VERSION ""

NS_ :

BS_:

BU_:

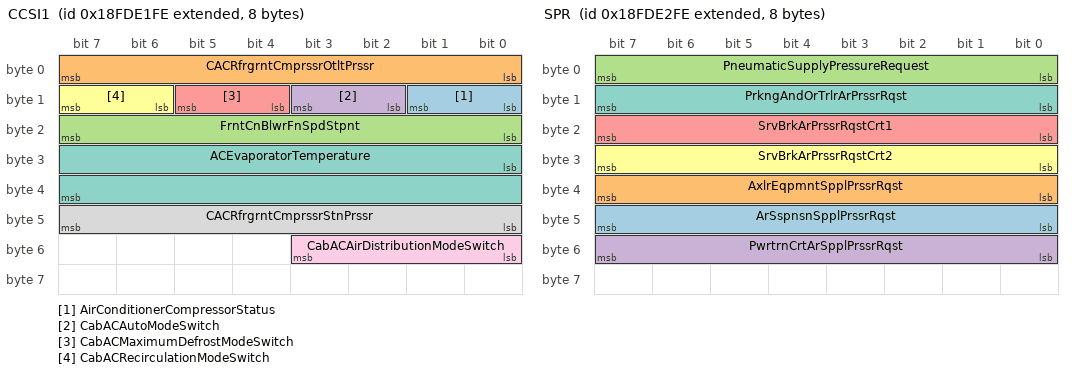
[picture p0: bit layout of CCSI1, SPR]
BO_ 2566775294 CCSI1: 8 Vector__XXX
 SG_ AirConditionerCompressorStatus : 8|2@1+ (1,0) [0|3] "" Vector__XXX
 SG_ CACRfrgrntCmprssrOtltPrssr : 0|8@1+ (16,0) [0|4000] "kPa" Vector__XXX
 SG_ FrntCnBlwrFnSpdStpnt : 16|8@1+ (0.4,0) [0|100] "%" Vector__XXX
 SG_ CabACAutoModeSwitch : 10|2@1+ (1,0) [0|3] "" Vector__XXX
 SG_ CabACMaximumDefrostModeSwitch : 12|2@1+ (1,0) [0|3] "" Vector__XXX
 SG_ CabACRecirculationModeSwitch : 14|2@1+ (1,0) [0|3] "" Vector__XXX
 SG_ ACEvaporatorTemperature : 24|16@1+ (0.03125,-273) [-273|1734.96875] "degC" Vector__XXX
 SG_ CACRfrgrntCmprssrStnPrssr : 40|8@1+ (16,0) [0|4000] "kPa" Vector__XXX
 SG_ CabACAirDistributionModeSwitch : 48|4@1+ (1,0) [0|15] "" Vector__XXX

BO_ 2566775550 SPR: 8 Vector__XXX
 SG_ ArSspnsnSpplPrssrRqst : 40|8@1+ (8,0) [0|2000] "kPa" Vector__XXX
 SG_ AxlrEqpmntSpplPrssrRqst : 32|8@1+ (8,0) [0|2000] "kPa" Vector__XXX
 SG_ PneumaticSupplyPressureRequest : 0|8@1+ (8,0) [0|2000] "kPa" Vector__XXX
 SG_ PwrtrnCrtArSpplPrssrRqst : 48|8@1+ (8,0) [0|2000] "kPa" Vector__XXX
 SG_ SrvBrkArPrssrRqstCrt1 : 16|8@1+ (8,0) [0|2000] "kPa" Vector__XXX
 SG_ SrvBrkArPrssrRqstCrt2 : 24|8@1+ (8,0) [0|2000] "kPa" Vector__XXX
 SG_ PrkngAndOrTrlrArPrssrRqst : 8|8@1+ (8,0) [0|2000] "kPa" Vector__XXX

BO_ 2566775806 EOAC: 8 Vector__XXX
 SG_ TravelVelocityControlPosition : 0|8@1+ (1,-125) [-125|125] "%" Vector__XXX

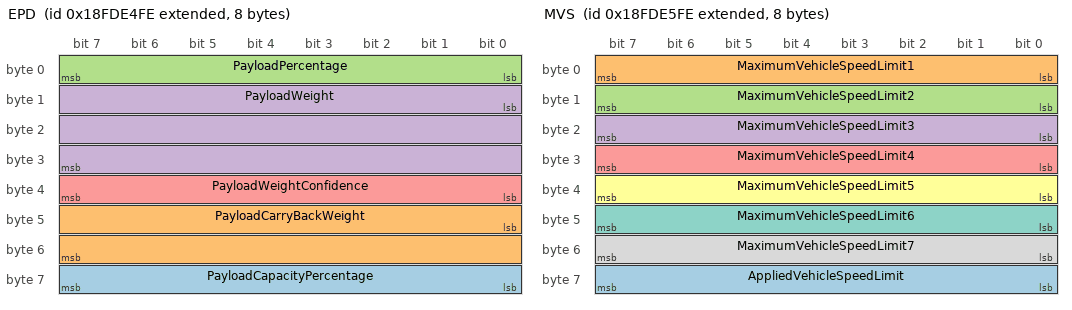
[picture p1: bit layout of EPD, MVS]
BO_ 2566776062 EPD: 8 Vector__XXX
 SG_ PayloadCapacityPercentage : 56|8@1+ (1,0) [0|250] "%" Vector__XXX
 SG_ PayloadCarryBackWeight : 40|16@1+ (2,0) [0|128510] "kg" Vector__XXX
 SG_ PayloadPercentage : 0|8@1+ (1,0) [0|250] "%" Vector__XXX
 SG_ PayloadWeight : 8|24@1+ (2,0) [0|32899070] "kg" Vector__XXX
 SG_ PayloadWeightConfidence : 32|8@1+ (0.5,0) [0|100] "%" Vector__XXX

BO_ 2566776318 MVS: 8 Vector__XXX
 SG_ AppliedVehicleSpeedLimit : 56|8@1+ (1,0) [0|250] "km/h" Vector__XXX
 SG_ MaximumVehicleSpeedLimit1 : 0|8@1+ (1,0) [0|250] "km/h" Vector__XXX
 SG_ MaximumVehicleSpeedLimit2 : 8|8@1+ (1,0) [0|250] "km/h" Vector__XXX
 SG_ MaximumVehicleSpeedLimit3 : 16|8@1+ (1,0) [0|250] "km/h" Vector__XXX
 SG_ MaximumVehicleSpeedLimit4 : 24|8@1+ (1,0) [0|250] "km/h" Vector__XXX
 SG_ MaximumVehicleSpeedLimit5 : 32|8@1+ (1,0) [0|250] "km/h" Vector__XXX
 SG_ MaximumVehicleSpeedLimit6 : 40|8@1+ (1,0) [0|250] "km/h" Vector__XXX
 SG_ MaximumVehicleSpeedLimit7 : 48|8@1+ (1,0) [0|250] "km/h" Vector__XXX

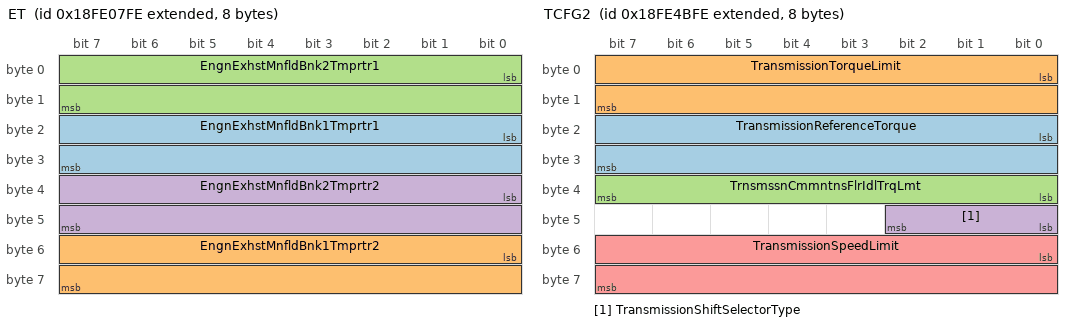
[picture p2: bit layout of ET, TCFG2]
BO_ 2566785022 ET: 8 Vector__XXX
 SG_ EngnExhstMnfldBnk1Tmprtr1 : 16|16@1+ (0.03125,-273) [-273|1734.96875] "degC" Vector__XXX
 SG_ EngnExhstMnfldBnk1Tmprtr2 : 48|16@1+ (0.03125,-273) [-273|1734.96875] "degC" Vector__XXX
 SG_ EngnExhstMnfldBnk2Tmprtr1 : 0|16@1+ (0.03125,-273) [-273|1734.96875] "degC" Vector__XXX
 SG_ EngnExhstMnfldBnk2Tmprtr2 : 32|16@1+ (0.03125,-273) [-273|1734.96875] "degC" Vector__XXX

BO_ 2566799614 LD: 8 Vector__XXX
 SG_ AlternateBeamHeadLightData : 2|2@1+ (1,0) [0|3] "" Vector__XXX
 SG_ BackUpLightAndAlarmHorn : 16|2@1+ (1,0) [0|3] "" Vector__XXX
 SG_ CenterStopLight : 18|2@1+ (1,0) [0|3] "" Vector__XXX
 SG_ HighBeamHeadLightData : 6|2@1+ (1,0) [0|3] "" Vector__XXX
 SG_ ImplementClearanceLight : 24|2@1+ (1,0) [0|3] "" Vector__XXX
 SG_ ImplementLeftFacingWorkLight : 60|2@1+ (1,0) [0|3] "" Vector__XXX
 SG_ ImplementLeftForwardWorkLight : 54|2@1+ (1,0) [0|3] "" Vector__XXX
 SG_ ImplementMarkerLight : 28|2@1+ (1,0) [0|3] "" Vector__XXX
 SG_ ImplementOemOption1Light : 50|2@1+ (1,0) [0|3] "" Vector__XXX
 SG_ ImplementOemOption2Light : 48|2@1+ (1,0) [0|3] "" Vector__XXX
 SG_ ImplementRearWorkLight : 62|2@1+ (1,0) [0|3] "" Vector__XXX
 SG_ ImplementRightFacingWorkLight : 52|2@1+ (1,0) [0|3] "" Vector__XXX
 SG_ ImplementRightForwardWorkLight : 58|2@1+ (1,0) [0|3] "" Vector__XXX
 SG_ LeftStopLight : 22|2@1+ (1,0) [0|3] "" Vector__XXX
 SG_ LeftTurnSignalLights : 14|2@1+ (1,0) [0|3] "" Vector__XXX
 SG_ LowBeamHeadLightData : 4|2@1+ (1,0) [0|3] "" Vector__XXX
 SG_ RearFogLights : 32|2@1+ (1,0) [0|3] "" Vector__XXX
 SG_ RightStopLight : 20|2@1+ (1,0) [0|3] "" Vector__XXX
 SG_ RightTurnSignalLights : 12|2@1+ (1,0) [0|3] "" Vector__XXX
 SG_ RotatingBeaconLight : 10|2@1+ (1,0) [0|3] "" Vector__XXX
 SG_ RunningLight : 0|2@1+ (1,0) [0|3] "" Vector__XXX
 SG_ TractorClearanceLight : 26|2@1+ (1,0) [0|3] "" Vector__XXX
 SG_ TractorFrontFogLights : 8|2@1+ (1,0) [0|3] "" Vector__XXX
 SG_ TractorMarkerLight : 30|2@1+ (1,0) [0|3] "" Vector__XXX
 SG_ TractorRearLowMountedWorkLights : 36|2@1+ (1,0) [0|3] "" Vector__XXX
 SG_ TractorSideLowMountedWorkLights : 40|2@1+ (1,0) [0|3] "" Vector__XXX
 SG_ TrtrFrntHghMntdWrkLghts : 46|2@1+ (1,0) [0|3] "" Vector__XXX
 SG_ TrtrFrntLwMntdWrkLghts : 44|2@1+ (1,0) [0|3] "" Vector__XXX
 SG_ TrtrRrHghMntdWrkLghts : 38|2@1+ (1,0) [0|3] "" Vector__XXX
 SG_ TrtrSdHghMntdWrkLghts : 42|2@1+ (1,0) [0|3] "" Vector__XXX
 SG_ TrtrUndrsdMntdWrkLghts : 34|2@1+ (1,0) [0|3] "" Vector__XXX

BO_ 2566802174 ETC7: 8 Vector__XXX
 SG_ ActiveShiftConsoleIndicator : 10|2@1+ (1,0) [0|3] "" Vector__XXX
 SG_ TransmissionEngineCrankEnable : 12|2@1+ (1,0) [0|3] "" Vector__XXX
 SG_ TransmissionManualModeIndicator : 54|2@1+ (1,0) [0|3] "" Vector__XXX
 SG_ TransmissionMode10Indicator : 46|2@1+ (1,0) [0|3] "" Vector__XXX
 SG_ TransmissionMode1Indicator : 22|2@1+ (1,0) [0|3] "" Vector__XXX
 SG_ TransmissionMode2Indicator : 20|2@1+ (1,0) [0|3] "" Vector__XXX
 SG_ TransmissionMode3Indicator : 18|2@1+ (1,0) [0|3] "" Vector__XXX
 SG_ TransmissionMode4Indicator : 16|2@1+ (1,0) [0|3] "" Vector__XXX
 SG_ TransmissionMode5Indicator : 32|2@1+ (1,0) [0|3] "" Vector__XXX
 SG_ TransmissionMode6Indicator : 34|2@1+ (1,0) [0|3] "" Vector__XXX
 SG_ TransmissionMode7Indicator : 36|2@1+ (1,0) [0|3] "" Vector__XXX
 SG_ TransmissionMode8Indicator : 38|2@1+ (1,0) [0|3] "" Vector__XXX
 SG_ TransmissionMode9Indicator : 44|2@1+ (1,0) [0|3] "" Vector__XXX
 SG_ TransmissionServiceIndicator : 2|2@1+ (1,0) [0|3] "" Vector__XXX
 SG_ TransmissionWarningIndicator : 42|2@1+ (1,0) [0|3] "" Vector__XXX
 SG_ TrnsmssnArSpplPrssrIndtr : 48|3@1+ (1,0) [0|7] "" Vector__XXX
 SG_ TrnsmssnAtNtrlMnlRtrnStt : 51|3@1+ (1,0) [0|7] "" Vector__XXX
 SG_ TrnsmssnCrrntRngDsplBlnkStt : 0|2@1+ (1,0) [0|3] "" Vector__XXX
 SG_ TrnsmssnRdFrBrkRls : 8|2@1+ (1,0) [0|3] "" Vector__XXX
 SG_ TrnsmssnRqstdGrFdk : 24|8@1+ (1,-125) [-125|125] "gear value" Vector__XXX
 SG_ TrnsmssnRqstdRngDsplBlnkStt : 4|2@1+ (1,0) [0|3] "" Vector__XXX
 SG_ TrnsmssnRqstdRngDsplFlshStt : 6|2@1+ (1,0) [0|3] "" Vector__XXX
 SG_ TrnsmssnRvrsGrShftInhtStts : 40|2@1+ (1,0) [0|3] "" Vector__XXX
 SG_ TrnsmssnShftInhtIndtr : 14|2@1+ (1,0) [0|3] "" Vector__XXX
 SG_ TrnsmssnLdRdtnIndtr : 56|2@1+ (1,0) [0|3] "" Vector__XXX
 SG_ TrnsmssnPrDfndRngLmtIndtr : 58|2@1+ (1,0) [0|3] "" Vector__XXX
 SG_ TransmissionCoastModeIndicator : 60|2@1+ (1,0) [0|3] "" Vector__XXX
 SG_ TrnsmssnOtptShftBrkIndtr : 62|2@1+ (1,0) [0|3] "" Vector__XXX

BO_ 2566802430 TCFG2: 8 Vector__XXX
 SG_ TransmissionReferenceTorque : 16|16@1+ (1,0) [0|64255] "Nm" Vector__XXX
 SG_ TransmissionTorqueLimit : 0|16@1+ (1,0) [0|64255] "Nm" Vector__XXX
 SG_ TrnsmssnCmmntnsFlrIdlTrqLmt : 32|8@1+ (1,-125) [0|125] "%" Vector__XXX
 SG_ TransmissionShiftSelectorType : 40|3@1+ (1,0) [0|7] "" Vector__XXX
 SG_ TransmissionSpeedLimit : 48|16@1+ (0.125,0) [0|8031.875] "rpm" Vector__XXX

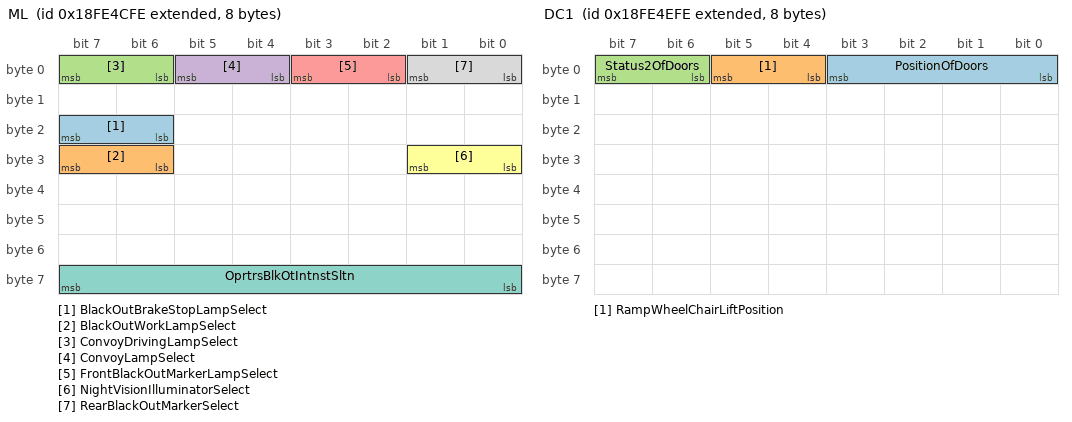
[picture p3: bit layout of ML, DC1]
BO_ 2566802686 ML: 8 Vector__XXX
 SG_ BlackOutBrakeStopLampSelect : 22|2@1+ (1,0) [0|3] "" Vector__XXX
 SG_ BlackOutWorkLampSelect : 30|2@1+ (1,0) [0|3] "" Vector__XXX
 SG_ ConvoyDrivingLampSelect : 6|2@1+ (1,0) [0|3] "" Vector__XXX
 SG_ ConvoyLampSelect : 4|2@1+ (1,0) [0|3] "" Vector__XXX
 SG_ FrontBlackOutMarkerLampSelect : 2|2@1+ (1,0) [0|3] "" Vector__XXX
 SG_ NightVisionIlluminatorSelect : 24|2@1+ (1,0) [0|3] "" Vector__XXX
 SG_ OprtrsBlkOtIntnstSltn : 56|8@1+ (0.4,0) [0|100] "%" Vector__XXX
 SG_ RearBlackOutMarkerSelect : 0|2@1+ (1,0) [0|3] "" Vector__XXX

BO_ 2566803198 DC1: 8 Vector__XXX
 SG_ PositionOfDoors : 0|4@1+ (1,0) [0|15] "" Vector__XXX
 SG_ RampWheelChairLiftPosition : 4|2@1+ (1,0) [0|3] "" Vector__XXX
 SG_ Status2OfDoors : 6|2@1+ (1,0) [0|3] "" Vector__XXX

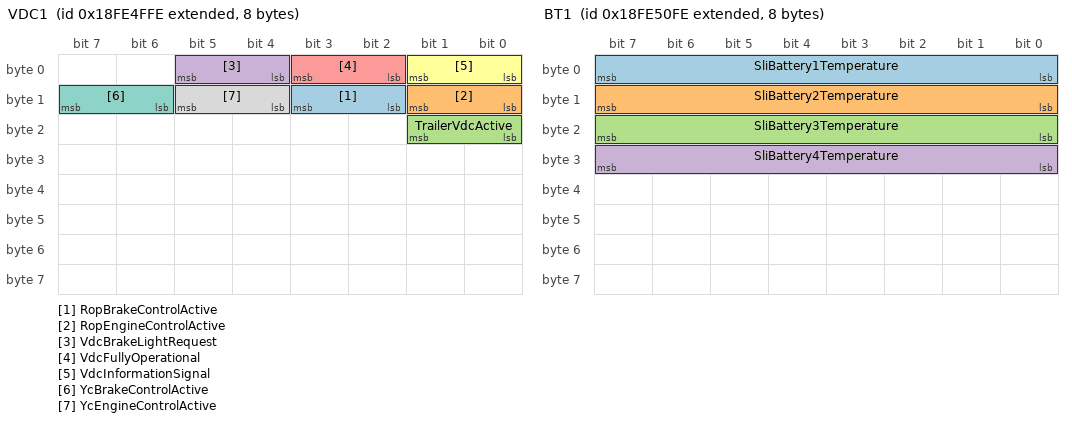
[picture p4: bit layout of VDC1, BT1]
BO_ 2566803454 VDC1: 8 Vector__XXX
 SG_ RopBrakeControlActive : 10|2@1+ (1,0) [0|3] "" Vector__XXX
 SG_ RopEngineControlActive : 8|2@1+ (1,0) [0|3] "" Vector__XXX
 SG_ TrailerVdcActive : 16|2@1+ (1,0) [0|3] "" Vector__XXX
 SG_ VdcBrakeLightRequest : 4|2@1+ (1,0) [0|3] "" Vector__XXX
 SG_ VdcFullyOperational : 2|2@1+ (1,0) [0|3] "" Vector__XXX
 SG_ VdcInformationSignal : 0|2@1+ (1,0) [0|3] "" Vector__XXX
 SG_ YcBrakeControlActive : 14|2@1+ (1,0) [0|3] "" Vector__XXX
 SG_ YcEngineControlActive : 12|2@1+ (1,0) [0|3] "" Vector__XXX

BO_ 2566803710 BT1: 8 Vector__XXX
 SG_ SliBattery1Temperature : 0|8@1+ (1,-40) [-40|210] "degC" Vector__XXX
 SG_ SliBattery2Temperature : 8|8@1+ (1,-40) [-40|210] "degC" Vector__XXX
 SG_ SliBattery3Temperature : 16|8@1+ (1,-40) [-40|210] "degC" Vector__XXX
 SG_ SliBattery4Temperature : 24|8@1+ (1,-40) [-40|210] "degC" Vector__XXX

BO_ 2566803966 ACC2: 8 Vector__XXX
 SG_ AccUsageDemand : 0|2@1+ (1,0) [0|3] "" Vector__XXX
 SG_ RequestedAccDistanceMode : 5|3@1+ (1,0) [0|7] "" Vector__XXX

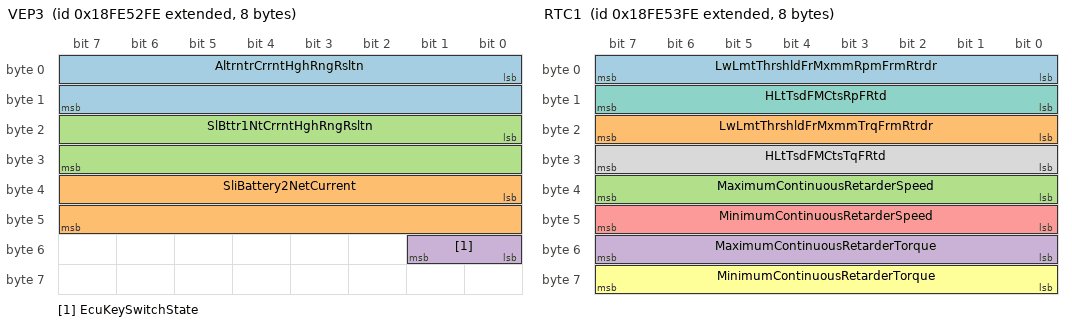
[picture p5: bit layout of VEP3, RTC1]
BO_ 2566804222 VEP3: 8 Vector__XXX
 SG_ AltrntrCrrntHghRngRsltn : 0|16@1+ (0.05,-1600) [-1600|1612.75] "A" Vector__XXX
 SG_ SliBattery2NetCurrent : 32|16@1+ (0.05,-1600) [-1600|1612.75] "A" Vector__XXX
 SG_ SlBttr1NtCrrntHghRngRsltn : 16|16@1+ (0.05,-1600) [-1600|1612.75] "A" Vector__XXX
 SG_ EcuKeySwitchState : 48|2@1+ (1,0) [0|3] "" Vector__XXX

BO_ 2566804478 RTC1: 8 Vector__XXX
 SG_ LwLmtThrshldFrMxmmRpmFrmRtrdr : 0|8@1+ (32,0) [0|8000] "rpm" Vector__XXX
 SG_ LwLmtThrshldFrMxmmTrqFrmRtrdr : 16|8@1+ (1,-125) [-125|125] "%" Vector__XXX
 SG_ MaximumContinuousRetarderSpeed : 32|8@1+ (32,0) [0|8000] "rpm" Vector__XXX
 SG_ MaximumContinuousRetarderTorque : 48|8@1+ (1,-125) [-125|125] "%" Vector__XXX
 SG_ MinimumContinuousRetarderSpeed : 40|8@1+ (32,0) [0|8000] "rpm" Vector__XXX
 SG_ MinimumContinuousRetarderTorque : 56|8@1+ (1,-125) [-125|125] "%" Vector__XXX
 SG_ HLtTsdFMCtsRpFRtd : 8|8@1+ (32,0) [0|8000] "rpm" Vector__XXX
 SG_ HLtTsdFMCtsTqFRtd : 24|8@1+ (1,-125) [-125|125] "%" Vector__XXX

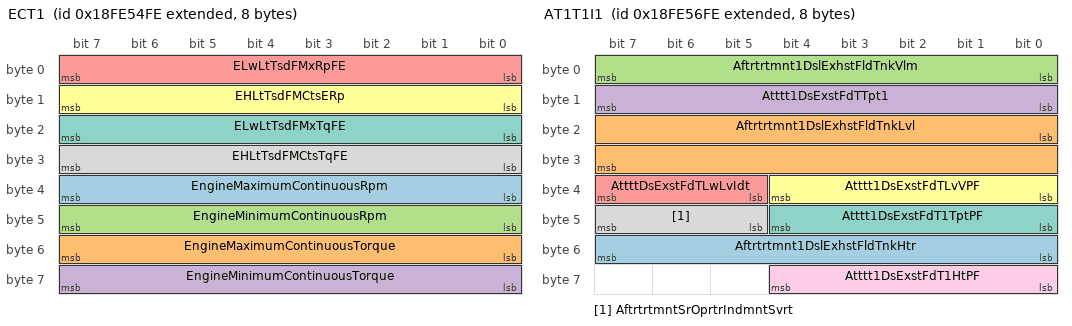
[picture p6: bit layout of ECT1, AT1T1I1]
BO_ 2566804734 ECT1: 8 Vector__XXX
 SG_ EngineMaximumContinuousRpm : 32|8@1+ (32,0) [0|8000] "rpm" Vector__XXX
 SG_ EngineMaximumContinuousTorque : 48|8@1+ (1,-125) [-125|125] "%" Vector__XXX
 SG_ EngineMinimumContinuousRpm : 40|8@1+ (32,0) [0|8000] "rpm" Vector__XXX
 SG_ EngineMinimumContinuousTorque : 56|8@1+ (1,-125) [-125|125] "%" Vector__XXX
 SG_ ELwLtTsdFMxRpFE : 0|8@1+ (32,0) [0|8000] "rpm" Vector__XXX
 SG_ EHLtTsdFMCtsERp : 8|8@1+ (32,0) [0|8000] "rpm" Vector__XXX
 SG_ ELwLtTsdFMxTqFE : 16|8@1+ (1,-125) [-125|125] "%" Vector__XXX
 SG_ EHLtTsdFMCtsTqFE : 24|8@1+ (1,-125) [-125|125] "%" Vector__XXX

BO_ 2566804990 GFD: 8 Vector__XXX
 SG_ FuelEnergyContent : 32|16@1+ (0.00390625,0) [0|250.99609375] "MJ/(Nm*Nm*Nm)" Vector__XXX
 SG_ ReferenceEngineGasMassFlowRate : 16|16@1+ (0.05,0) [0|3212.75] "kg/h" Vector__XXX
 SG_ SpecificHeatRatio : 0|16@1+ (0.001,0) [0|2] "" Vector__XXX

BO_ 2566805246 AT1T1I1: 8 Vector__XXX
 SG_ Aftrtrtmnt1DslExhstFldTnkHtr : 48|8@1+ (0.4,0) [0|100] "%" Vector__XXX
 SG_ Aftrtrtmnt1DslExhstFldTnkLvl : 16|16@1+ (0.1,0) [0|6425.5] "mm" Vector__XXX
 SG_ Aftrtrtmnt1DslExhstFldTnkVlm : 0|8@1+ (0.4,0) [0|100] "%" Vector__XXX
 SG_ Atttt1DsExstFdTTpt1 : 8|8@1+ (1,-40) [-40|210] "degC" Vector__XXX
 SG_ AttttDsExstFdTLwLvIdt : 37|3@1+ (1,0) [0|7] "" Vector__XXX
 SG_ Atttt1DsExstFdTLvVPF : 32|5@1+ (1,0) [0|31] "" Vector__XXX
 SG_ Atttt1DsExstFdT1TptPF : 40|5@1+ (1,0) [0|31] "" Vector__XXX
 SG_ AftrtrtmntSrOprtrIndmntSvrt : 45|3@1+ (1,0) [0|7] "" Vector__XXX
 SG_ Atttt1DsExstFdT1HtPF : 56|5@1+ (1,0) [0|31] "" Vector__XXX

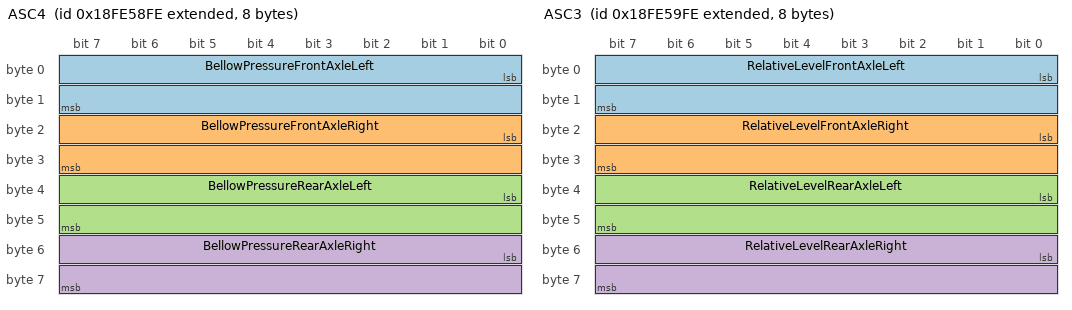
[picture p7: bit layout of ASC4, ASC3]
BO_ 2566805758 ASC4: 8 Vector__XXX
 SG_ BellowPressureFrontAxleLeft : 0|16@1+ (0.1,0) [0|6425.5] "kPa" Vector__XXX
 SG_ BellowPressureFrontAxleRight : 16|16@1+ (0.1,0) [0|6425.5] "kPa" Vector__XXX
 SG_ BellowPressureRearAxleLeft : 32|16@1+ (0.1,0) [0|6425.5] "kPa" Vector__XXX
 SG_ BellowPressureRearAxleRight : 48|16@1+ (0.1,0) [0|6425.5] "kPa" Vector__XXX

BO_ 2566806014 ASC3: 8 Vector__XXX
 SG_ RelativeLevelFrontAxleLeft : 0|16@1+ (0.1,-3200) [-3200|3225.5] "mm" Vector__XXX
 SG_ RelativeLevelFrontAxleRight : 16|16@1+ (0.1,-3200) [-3200|3225.5] "mm" Vector__XXX
 SG_ RelativeLevelRearAxleLeft : 32|16@1+ (0.1,-3200) [-3200|3225.5] "mm" Vector__XXX
 SG_ RelativeLevelRearAxleRight : 48|16@1+ (0.1,-3200) [-3200|3225.5] "mm" Vector__XXX

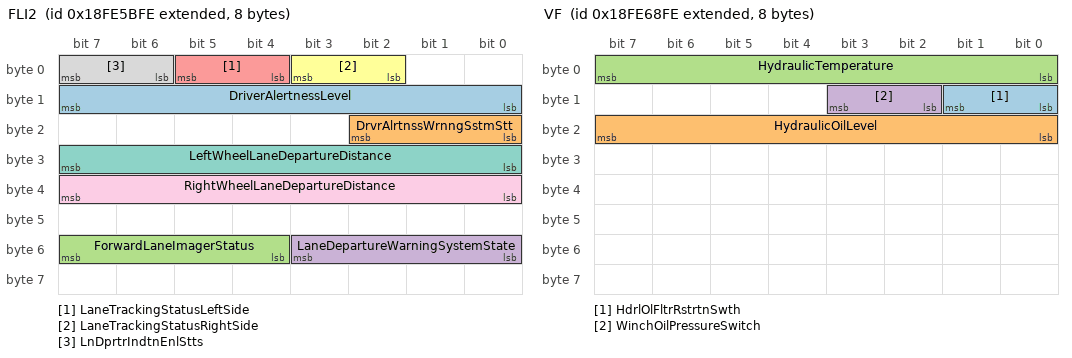
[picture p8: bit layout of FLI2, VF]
BO_ 2566806526 FLI2: 8 Vector__XXX
 SG_ DriverAlertnessLevel : 8|8@1+ (0.4,0) [0|100] "%" Vector__XXX
 SG_ DrvrAlrtnssWrnngSstmStt : 16|3@1+ (1,0) [0|7] "" Vector__XXX
 SG_ ForwardLaneImagerStatus : 52|4@1+ (1,0) [0|15] "" Vector__XXX
 SG_ LaneDepartureWarningSystemState : 48|4@1+ (1,0) [0|15] "" Vector__XXX
 SG_ LaneTrackingStatusLeftSide : 4|2@1+ (1,0) [0|3] "" Vector__XXX
 SG_ LaneTrackingStatusRightSide : 2|2@1+ (1,0) [0|3] "" Vector__XXX
 SG_ LeftWheelLaneDepartureDistance : 24|8@1+ (1,-125) [-125|125] "cm" Vector__XXX
 SG_ LnDprtrIndtnEnlStts : 6|2@1+ (1,0) [0|3] "" Vector__XXX
 SG_ RightWheelLaneDepartureDistance : 32|8@1+ (1,-125) [-125|125] "cm" Vector__XXX

BO_ 2566809342 BM: 8 Vector__XXX
 SG_ BatteryMainSwitchHoldState : 0|2@1+ (1,0) [0|3] "" Vector__XXX

BO_ 2566809598 CCC: 8 Vector__XXX
 SG_ AxlrHtrMxmmOtptPwr : 0|16@1+ (2,0) [0|128510] "W" Vector__XXX

BO_ 2566809854 VF: 8 Vector__XXX
 SG_ HdrlOlFltrRstrtnSwth : 8|2@1+ (1,0) [0|3] "" Vector__XXX
 SG_ HydraulicOilLevel : 16|8@1+ (0.4,0) [0|100] "%" Vector__XXX
 SG_ HydraulicTemperature : 0|8@1+ (1,-40) [-40|210] "degC" Vector__XXX
 SG_ WinchOilPressureSwitch : 10|2@1+ (1,0) [0|3] "" Vector__XXX

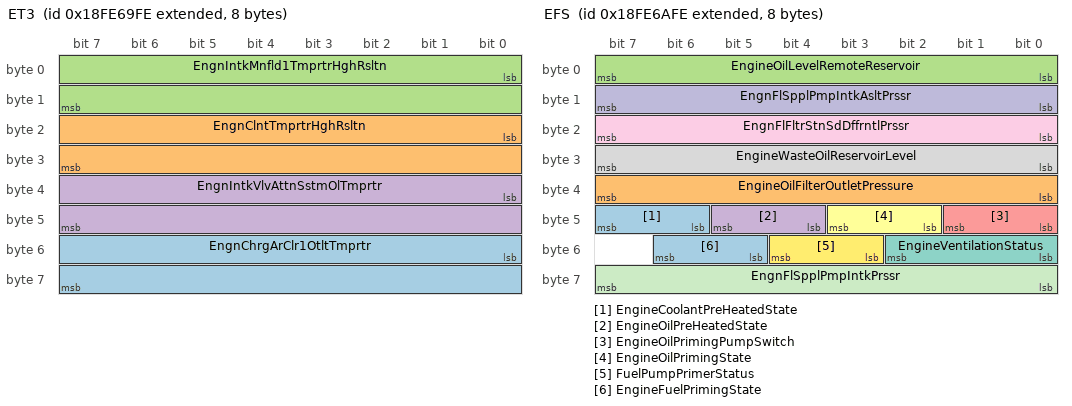
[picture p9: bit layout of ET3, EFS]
BO_ 2566810110 ET3: 8 Vector__XXX
 SG_ EngnChrgArClr1OtltTmprtr : 48|16@1+ (0.03125,-273) [-273|1734.96875] "degC" Vector__XXX
 SG_ EngnClntTmprtrHghRsltn : 16|16@1+ (0.03125,-273) [-273|1734.96875] "degC" Vector__XXX
 SG_ EngnIntkMnfld1TmprtrHghRsltn : 0|16@1+ (0.03125,-273) [-273|1734.96875] "degC" Vector__XXX
 SG_ EngnIntkVlvAttnSstmOlTmprtr : 32|16@1+ (0.03125,-273) [-273|1734.96875] "degC" Vector__XXX

BO_ 2566810366 EFS: 8 Vector__XXX
 SG_ EngineCoolantPreHeatedState : 46|2@1+ (1,0) [0|3] "" Vector__XXX
 SG_ EngineOilFilterOutletPressure : 32|8@1+ (4,0) [0|1000] "kPa" Vector__XXX
 SG_ EngineOilLevelRemoteReservoir : 0|8@1+ (0.4,0) [0|100] "%" Vector__XXX
 SG_ EngineOilPreHeatedState : 44|2@1+ (1,0) [0|3] "" Vector__XXX
 SG_ EngineOilPrimingPumpSwitch : 40|2@1+ (1,0) [0|3] "" Vector__XXX
 SG_ EngineOilPrimingState : 42|2@1+ (1,0) [0|3] "" Vector__XXX
 SG_ EngineVentilationStatus : 48|3@1+ (1,0) [0|7] "" Vector__XXX
 SG_ EngineWasteOilReservoirLevel : 24|8@1+ (0.4,0) [0|100] "%" Vector__XXX
 SG_ EngnFlFltrStnSdDffrntlPrssr : 16|8@1+ (2,0) [0|500] "kPa" Vector__XXX
 SG_ EngnFlSpplPmpIntkAsltPrssr : 8|8@1+ (2,0) [0|500] "kPa" Vector__XXX
 SG_ EngnFlSpplPmpIntkPrssr : 56|8@1+ (2,0) [0|500] "kPa" Vector__XXX
 SG_ FuelPumpPrimerStatus : 51|2@1+ (1,0) [0|3] "" Vector__XXX
 SG_ EngineFuelPrimingState : 53|2@1+ (1,0) [0|3] "" Vector__XXX

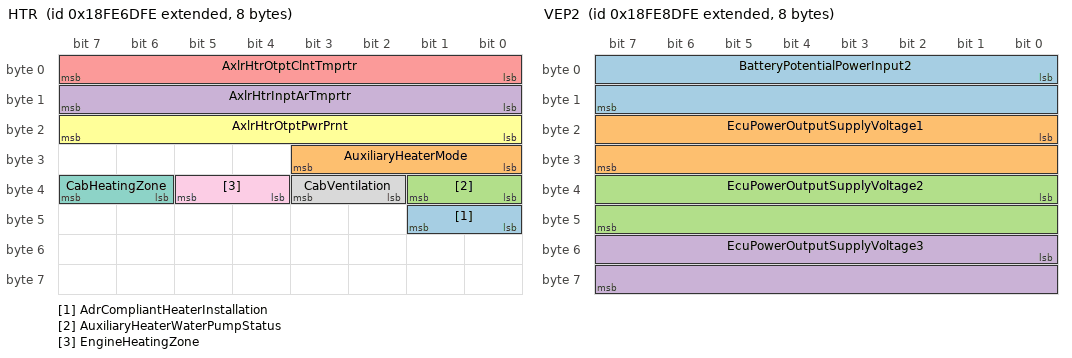
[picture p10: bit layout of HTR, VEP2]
BO_ 2566811134 HTR: 8 Vector__XXX
 SG_ AdrCompliantHeaterInstallation : 40|2@1+ (1,0) [0|3] "" Vector__XXX
 SG_ AuxiliaryHeaterMode : 24|4@1+ (1,0) [0|15] "" Vector__XXX
 SG_ AuxiliaryHeaterWaterPumpStatus : 32|2@1+ (1,0) [0|3] "" Vector__XXX
 SG_ AxlrHtrInptArTmprtr : 8|8@1+ (1,-40) [-40|210] "degC" Vector__XXX
 SG_ AxlrHtrOtptClntTmprtr : 0|8@1+ (1,-40) [-40|210] "degC" Vector__XXX
 SG_ AxlrHtrOtptPwrPrnt : 16|8@1+ (0.4,0) [0|100] "%" Vector__XXX
 SG_ CabHeatingZone : 38|2@1+ (1,0) [0|3] "" Vector__XXX
 SG_ CabVentilation : 34|2@1+ (1,0) [0|3] "" Vector__XXX
 SG_ EngineHeatingZone : 36|2@1+ (1,0) [0|3] "" Vector__XXX

BO_ 2566811902 CVW: 8 Vector__XXX
 SG_ GrossCombinationVehicleWeight : 16|16@1+ (10,0) [0|642550] "kg" Vector__XXX
 SG_ PoweredVehicleWeight : 0|16@1+ (10,0) [0|642550] "kg" Vector__XXX
 SG_ GrssCmntnVhlWghtCnfdn : 32|8@1+ (0.5,0) [0|100] "%" Vector__XXX

BO_ 2566819326 VEP2: 8 Vector__XXX
 SG_ BatteryPotentialPowerInput2 : 0|16@1+ (0.05,0) [0|3212.75] "V" Vector__XXX
 SG_ EcuPowerOutputSupplyVoltage1 : 16|16@1+ (0.05,0) [0|3212.75] "V" Vector__XXX
 SG_ EcuPowerOutputSupplyVoltage2 : 32|16@1+ (0.05,0) [0|3212.75] "V" Vector__XXX
 SG_ EcuPowerOutputSupplyVoltage3 : 48|16@1+ (0.05,0) [0|3212.75] "V" Vector__XXX

BO_ 2566819838 SP2: 8 Vector__XXX
 SG_ EngnExtrnlShtdwnArSpplPrssr : 0|16@1+ (0.5,0) [0|32127.5] "kPa" Vector__XXX

BO_ 2566820094 ETH: 33 Vector__XXX
 SG_ CalibrationRecordDurationTime : 80|32@1+ (0.05,0) [0|210554060.75] "h" Vector__XXX
 SG_ CalibrationRecordStartDay : 64|8@1+ (0.25,0) [0.25|31.75] "days" Vector__XXX
 SG_ CalibrationRecordStartMonth : 56|8@1+ (1,0) [1|12] "month" Vector__XXX
 SG_ CalibrationRecordStartYear : 72|8@1+ (1,1985) [1985|2235] "year" Vector__XXX
 SG_ EnginePeakTorque1 : 24|16@1+ (1,0) [0|64255] "Nm" Vector__XXX
 SG_ EnginePeakTorque2 : 40|16@1+ (1,0) [0|64255] "Nm" Vector__XXX
 SG_ EnginePower : 8|16@1+ (0.5,0) [0|32127.5] "kW" Vector__XXX
 SG_ EngineTorqueLimit1Transmission : 136|16@1+ (1,0) [0|64255] "Nm" Vector__XXX
 SG_ EngineTorqueLimit2Transmission : 168|16@1+ (1,0) [0|64255] "Nm" Vector__XXX
 SG_ EngineTorqueLimit3Transmission : 200|16@1+ (1,0) [0|64255] "Nm" Vector__XXX
 SG_ EngineTorqueLimit4Transmission : 216|16@1+ (1,0) [0|64255] "Nm" Vector__XXX
 SG_ EngineTorqueLimit5Switch : 232|16@1+ (1,0) [0|64255] "Nm" Vector__XXX
 SG_ EngineTorqueLimit6AxleInput : 248|16@1+ (2,0) [0|128510] "Nm" Vector__XXX
 SG_ EngineTorqueLimitFeature : 114|3@1+ (1,0) [0|7] "" Vector__XXX
 SG_ TorqueLimitingFeatureStatus : 112|2@1+ (1,0) [0|3] "" Vector__XXX
 SG_ TransmissionGearRatio1 : 120|16@1+ (0.01,0) [0|642.55] "" Vector__XXX
 SG_ TransmissionGearRatio2 : 152|16@1+ (0.01,0) [0|642.55] "" Vector__XXX
 SG_ TransmissionGearRatio3 : 184|16@1+ (0.01,0) [0|642.55] "" Vector__XXX
 SG_ NmrOfEngnTrqHstrRrds : 0|8@1+ (1,0) [0|250] "Record" Vector__XXX

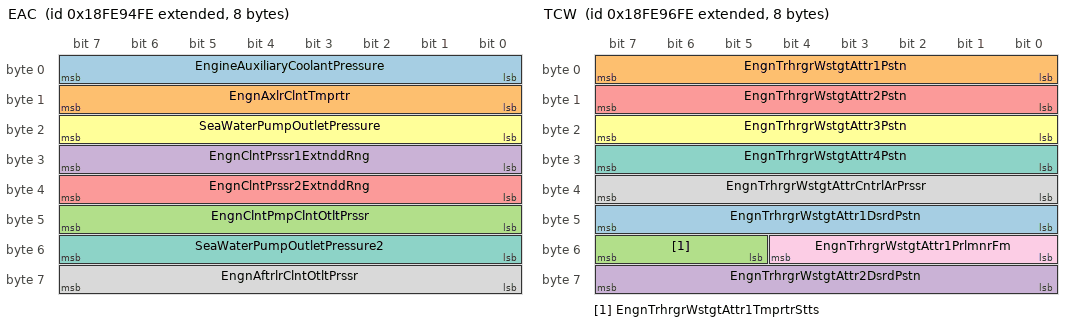
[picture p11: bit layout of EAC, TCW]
BO_ 2566821118 EAC: 8 Vector__XXX
 SG_ EngineAuxiliaryCoolantPressure : 0|8@1+ (4,0) [0|1000] "kPa" Vector__XXX
 SG_ EngnAxlrClntTmprtr : 8|8@1+ (1,-40) [-40|210] "degC" Vector__XXX
 SG_ EngnClntPmpClntOtltPrssr : 40|8@1+ (2,0) [0|500] "kPa" Vector__XXX
 SG_ EngnClntPrssr1ExtnddRng : 24|8@1+ (4,0) [0|1000] "kPa" Vector__XXX
 SG_ EngnClntPrssr2ExtnddRng : 32|8@1+ (4,0) [0|1000] "kPa" Vector__XXX
 SG_ SeaWaterPumpOutletPressure : 16|8@1+ (2,0) [0|500] "kPa" Vector__XXX
 SG_ SeaWaterPumpOutletPressure2 : 48|8@1+ (2,0) [0|500] "kPa" Vector__XXX
 SG_ EngnAftrlrClntOtltPrssr : 56|8@1+ (4,0) [0|1000] "kPa" Vector__XXX

BO_ 2566821630 TCW: 8 Vector__XXX
 SG_ EngnTrhrgrWstgtAttr1DsrdPstn : 40|8@1+ (0.4,0) [0|100] "%" Vector__XXX
 SG_ EngnTrhrgrWstgtAttr1Pstn : 0|8@1+ (0.4,0) [0|100] "%" Vector__XXX
 SG_ EngnTrhrgrWstgtAttr1TmprtrStts : 53|3@1+ (1,0) [0|7] "" Vector__XXX
 SG_ EngnTrhrgrWstgtAttr2DsrdPstn : 56|8@1+ (0.4,0) [0|100] "%" Vector__XXX
 SG_ EngnTrhrgrWstgtAttr2Pstn : 8|8@1+ (0.4,0) [0|100] "%" Vector__XXX
 SG_ EngnTrhrgrWstgtAttr3Pstn : 16|8@1+ (0.4,0) [0|100] "%" Vector__XXX
 SG_ EngnTrhrgrWstgtAttr4Pstn : 24|8@1+ (0.4,0) [0|100] "%" Vector__XXX
 SG_ EngnTrhrgrWstgtAttrCntrlArPrssr : 32|8@1+ (4,0) [0|1000] "kPa" Vector__XXX
 SG_ EngnTrhrgrWstgtAttr1PrlmnrFm : 48|5@1+ (1,0) [0|31] "" Vector__XXX

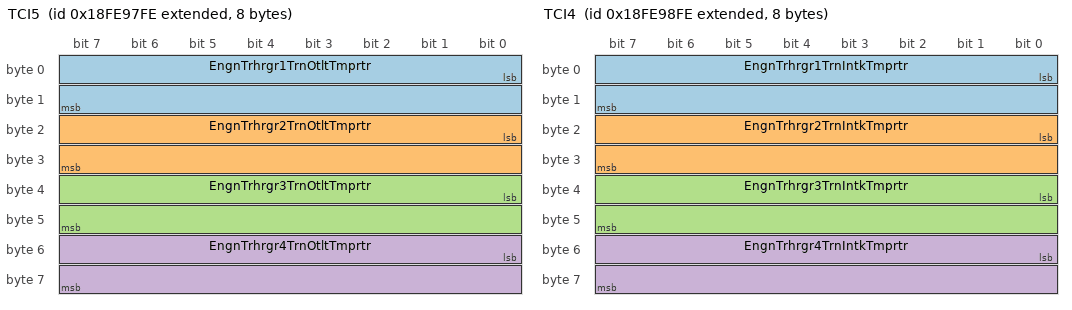
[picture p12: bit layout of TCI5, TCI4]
BO_ 2566821886 TCI5: 8 Vector__XXX
 SG_ EngnTrhrgr1TrnOtltTmprtr : 0|16@1+ (0.03125,-273) [-273|1734.96875] "degC" Vector__XXX
 SG_ EngnTrhrgr2TrnOtltTmprtr : 16|16@1+ (0.03125,-273) [-273|1734.96875] "degC" Vector__XXX
 SG_ EngnTrhrgr3TrnOtltTmprtr : 32|16@1+ (0.03125,-273) [-273|1734.96875] "degC" Vector__XXX
 SG_ EngnTrhrgr4TrnOtltTmprtr : 48|16@1+ (0.03125,-273) [-273|1734.96875] "degC" Vector__XXX

BO_ 2566822142 TCI4: 8 Vector__XXX
 SG_ EngnTrhrgr1TrnIntkTmprtr : 0|16@1+ (0.03125,-273) [-273|1734.96875] "degC" Vector__XXX
 SG_ EngnTrhrgr2TrnIntkTmprtr : 16|16@1+ (0.03125,-273) [-273|1734.96875] "degC" Vector__XXX
 SG_ EngnTrhrgr3TrnIntkTmprtr : 32|16@1+ (0.03125,-273) [-273|1734.96875] "degC" Vector__XXX
 SG_ EngnTrhrgr4TrnIntkTmprtr : 48|16@1+ (0.03125,-273) [-273|1734.96875] "degC" Vector__XXX

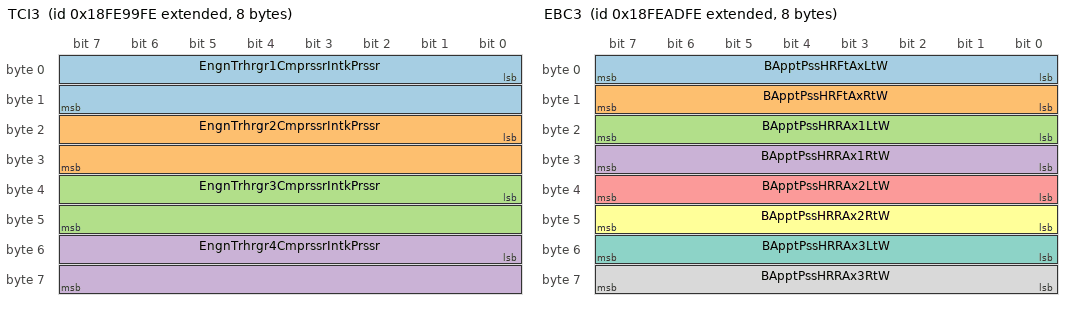
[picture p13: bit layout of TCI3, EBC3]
BO_ 2566822398 TCI3: 8 Vector__XXX
 SG_ EngnTrhrgr1CmprssrIntkPrssr : 0|16@1+ (0.0078125,-250) [-250|251.9921875] "kPa" Vector__XXX
 SG_ EngnTrhrgr2CmprssrIntkPrssr : 16|16@1+ (0.0078125,-250) [-250|251.9921875] "kPa" Vector__XXX
 SG_ EngnTrhrgr3CmprssrIntkPrssr : 32|16@1+ (0.0078125,-250) [-250|251.9921875] "kPa" Vector__XXX
 SG_ EngnTrhrgr4CmprssrIntkPrssr : 48|16@1+ (0.0078125,-250) [-250|251.9921875] "kPa" Vector__XXX

BO_ 2566822654 TCI2: 8 Vector__XXX
 SG_ EngnTrhrgr1CmprssrIntkTmprtr : 0|16@1+ (0.03125,-273) [-273|1734.96875] "degC" Vector__XXX
 SG_ EngnTrhrgr2CmprssrIntkTmprtr : 16|16@1+ (0.03125,-273) [-273|1734.96875] "degC" Vector__XXX
 SG_ EngnTrhrgr3CmprssrIntkTmprtr : 32|16@1+ (0.03125,-273) [-273|1734.96875] "degC" Vector__XXX
 SG_ EngnTrhrgr4CmprssrIntkTmprtr : 48|16@1+ (0.03125,-273) [-273|1734.96875] "degC" Vector__XXX

BO_ 2566823166 MBT3: 8 Vector__XXX
 SG_ EngineMainBearing10Temperature : 16|16@1+ (0.03125,-273) [-273|1734.96875] "degC" Vector__XXX
 SG_ EngineMainBearing11Temperature : 32|16@1+ (0.03125,-273) [-273|1734.96875] "degC" Vector__XXX
 SG_ EngineMainBearing12Temperature : 48|16@1+ (0.03125,-273) [-273|1734.96875] "degC" Vector__XXX
 SG_ EngineMainBearing9Temperature : 0|16@1+ (0.03125,-273) [-273|1734.96875] "degC" Vector__XXX

BO_ 2566823422 MBT2: 8 Vector__XXX
 SG_ EngineMainBearing5Temperature : 0|16@1+ (0.03125,-273) [-273|1734.96875] "degC" Vector__XXX
 SG_ EngineMainBearing6Temperature : 16|16@1+ (0.03125,-273) [-273|1734.96875] "degC" Vector__XXX
 SG_ EngineMainBearing7Temperature : 32|16@1+ (0.03125,-273) [-273|1734.96875] "degC" Vector__XXX
 SG_ EngineMainBearing8Temperature : 48|16@1+ (0.03125,-273) [-273|1734.96875] "degC" Vector__XXX

BO_ 2566823678 MBT1: 8 Vector__XXX
 SG_ EngineMainBearing1Temperature : 0|16@1+ (0.03125,-273) [-273|1734.96875] "degC" Vector__XXX
 SG_ EngineMainBearing2Temperature : 16|16@1+ (0.03125,-273) [-273|1734.96875] "degC" Vector__XXX
 SG_ EngineMainBearing3Temperature : 32|16@1+ (0.03125,-273) [-273|1734.96875] "degC" Vector__XXX
 SG_ EngineMainBearing4Temperature : 48|16@1+ (0.03125,-273) [-273|1734.96875] "degC" Vector__XXX

BO_ 2566824190 EPT4: 8 Vector__XXX
 SG_ EngnExhstGsPrt13Tmprtr : 0|16@1+ (0.03125,-273) [-273|1734.96875] "degC" Vector__XXX
 SG_ EngnExhstGsPrt14Tmprtr : 16|16@1+ (0.03125,-273) [-273|1734.96875] "degC" Vector__XXX
 SG_ EngnExhstGsPrt15Tmprtr : 32|16@1+ (0.03125,-273) [-273|1734.96875] "degC" Vector__XXX
 SG_ EngnExhstGsPrt16Tmprtr : 48|16@1+ (0.03125,-273) [-273|1734.96875] "degC" Vector__XXX

BO_ 2566825214 ET2: 8 Vector__XXX
 SG_ EngineEcuTemperature : 16|16@1+ (0.03125,-273) [-273|1734.96875] "degC" Vector__XXX
 SG_ EngineOilTemperature2 : 0|16@1+ (0.03125,-273) [-273|1734.96875] "degC" Vector__XXX
 SG_ EngnExhstGsRrltn1DffrntlPrssr : 32|16@1+ (0.0078125,-250) [-250|251.9921875] "kPa" Vector__XXX
 SG_ EngnExhstGsRrltn1Tmprtr : 48|16@1+ (0.03125,-273) [-273|1734.96875] "degC" Vector__XXX

BO_ 2566825726 IMT1: 8 Vector__XXX
 SG_ EngnTrhrgr1BstPrssr : 0|16@1+ (0.125,0) [0|8031.875] "kPa" Vector__XXX
 SG_ EngnTrhrgr2BstPrssr : 16|16@1+ (0.125,0) [0|8031.875] "kPa" Vector__XXX
 SG_ EngnTrhrgr3BstPrssr : 32|16@1+ (0.125,0) [0|8031.875] "kPa" Vector__XXX
 SG_ EngnTrhrgr4BstPrssr : 48|16@1+ (0.125,0) [0|8031.875] "kPa" Vector__XXX

BO_ 2566827518 EBC3: 8 Vector__XXX
 SG_ BApptPssHRFtAxLtW : 0|8@1+ (5,0) [0|1250] "kPa" Vector__XXX
 SG_ BApptPssHRFtAxRtW : 8|8@1+ (5,0) [0|1250] "kPa" Vector__XXX
 SG_ BApptPssHRRAx1LtW : 16|8@1+ (5,0) [0|1250] "kPa" Vector__XXX
 SG_ BApptPssHRRAx1RtW : 24|8@1+ (5,0) [0|1250] "kPa" Vector__XXX
 SG_ BApptPssHRRAx2LtW : 32|8@1+ (5,0) [0|1250] "kPa" Vector__XXX
 SG_ BApptPssHRRAx2RtW : 40|8@1+ (5,0) [0|1250] "kPa" Vector__XXX
 SG_ BApptPssHRRAx3LtW : 48|8@1+ (5,0) [0|1250] "kPa" Vector__XXX
 SG_ BApptPssHRRAx3RtW : 56|8@1+ (5,0) [0|1250] "kPa" Vector__XXX

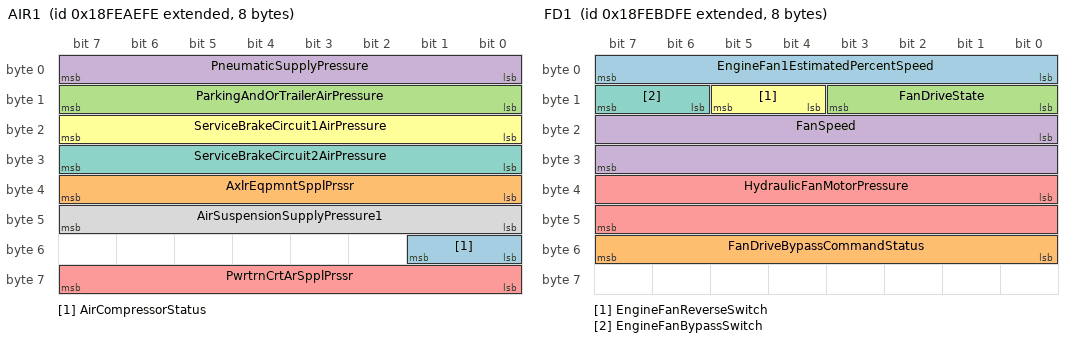
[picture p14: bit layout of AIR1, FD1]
BO_ 2566827774 AIR1: 8 Vector__XXX
 SG_ AirCompressorStatus : 48|2@1+ (1,0) [0|3] "" Vector__XXX
 SG_ AxlrEqpmntSpplPrssr : 32|8@1+ (8,0) [0|2000] "kPa" Vector__XXX
 SG_ ParkingAndOrTrailerAirPressure : 8|8@1+ (8,0) [0|2000] "kPa" Vector__XXX
 SG_ PneumaticSupplyPressure : 0|8@1+ (8,0) [0|2000] "kPa" Vector__XXX
 SG_ PwrtrnCrtArSpplPrssr : 56|8@1+ (8,0) [0|2000] "kPa" Vector__XXX
 SG_ ServiceBrakeCircuit1AirPressure : 16|8@1+ (8,0) [0|2000] "kPa" Vector__XXX
 SG_ ServiceBrakeCircuit2AirPressure : 24|8@1+ (8,0) [0|2000] "kPa" Vector__XXX
 SG_ AirSuspensionSupplyPressure1 : 40|8@1+ (8,0) [0|2000] "kPa" Vector__XXX

BO_ 2566831614 FD1: 8 Vector__XXX
 SG_ EngineFan1EstimatedPercentSpeed : 0|8@1+ (0.4,0) [0|100] "%" Vector__XXX
 SG_ FanDriveBypassCommandStatus : 48|8@1+ (0.4,0) [0|100] "%" Vector__XXX
 SG_ FanDriveState : 8|4@1+ (1,0) [0|15] "" Vector__XXX
 SG_ FanSpeed : 16|16@1+ (0.125,0) [0|8031.875] "rpm" Vector__XXX
 SG_ HydraulicFanMotorPressure : 32|16@1+ (0.5,0) [0|32127.5] "kPa" Vector__XXX
 SG_ EngineFanReverseSwitch : 12|2@1+ (1,0) [0|3] "" Vector__XXX
 SG_ EngineFanBypassSwitch : 14|2@1+ (1,0) [0|3] "" Vector__XXX

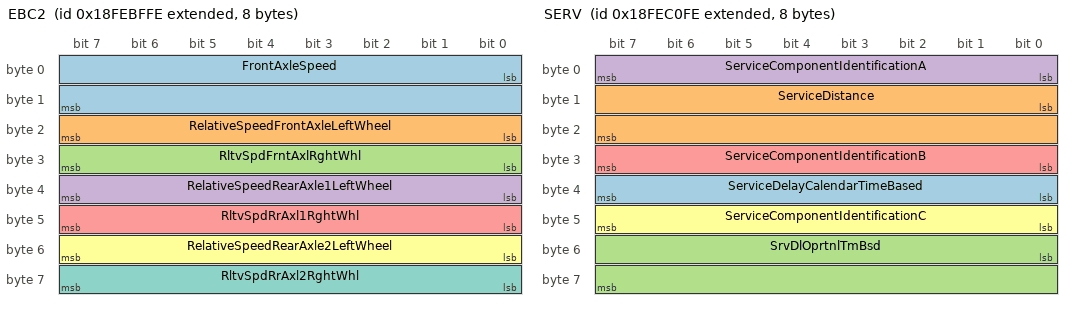
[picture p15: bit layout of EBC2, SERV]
BO_ 2566832126 EBC2: 8 Vector__XXX
 SG_ FrontAxleSpeed : 0|16@1+ (0.00390625,0) [0|250.99609375] "km/h" Vector__XXX
 SG_ RelativeSpeedFrontAxleLeftWheel : 16|8@1+ (0.0625,-7.8125) [-7.8125|7.8125] "km/h" Vector__XXX
 SG_ RltvSpdFrntAxlRghtWhl : 24|8@1+ (0.0625,-7.8125) [-7.8125|7.8125] "km/h" Vector__XXX
 SG_ RelativeSpeedRearAxle1LeftWheel : 32|8@1+ (0.0625,-7.8125) [-7.8125|7.8125] "km/h" Vector__XXX
 SG_ RltvSpdRrAxl1RghtWhl : 40|8@1+ (0.0625,-7.8125) [-7.8125|7.8125] "km/h" Vector__XXX
 SG_ RelativeSpeedRearAxle2LeftWheel : 48|8@1+ (0.0625,-7.8125) [-7.8125|7.8125] "km/h" Vector__XXX
 SG_ RltvSpdRrAxl2RghtWhl : 56|8@1+ (0.0625,-7.8125) [-7.8125|7.8125] "km/h" Vector__XXX

BO_ 2566832382 SERV: 8 Vector__XXX
 SG_ ServiceDelayCalendarTimeBased : 32|8@1+ (1,-125) [-125|125] "week" Vector__XXX
 SG_ ServiceDistance : 8|16@1+ (5,-160635) [-160635|160640] "km" Vector__XXX
 SG_ SrvDlOprtnlTmBsd : 48|16@1+ (1,-32127) [-32127|32128] "h" Vector__XXX
 SG_ ServiceComponentIdentificationA : 0|8@1+ (1,0) [0|250] "ID" Vector__XXX
 SG_ ServiceComponentIdentificationB : 24|8@1+ (1,0) [0|250] "ID" Vector__XXX
 SG_ ServiceComponentIdentificationC : 40|8@1+ (1,0) [0|250] "ID" Vector__XXX

BO_ 2566832638 VDHR: 8 Vector__XXX
 SG_ TripDistanceHighResolution : 32|32@1+ (5,0) [0|21055406075] "m" Vector__XXX
 SG_ TtlVhlDstnHghRsltn : 0|32@1+ (5,0) [0|21055406075] "m" Vector__XXX

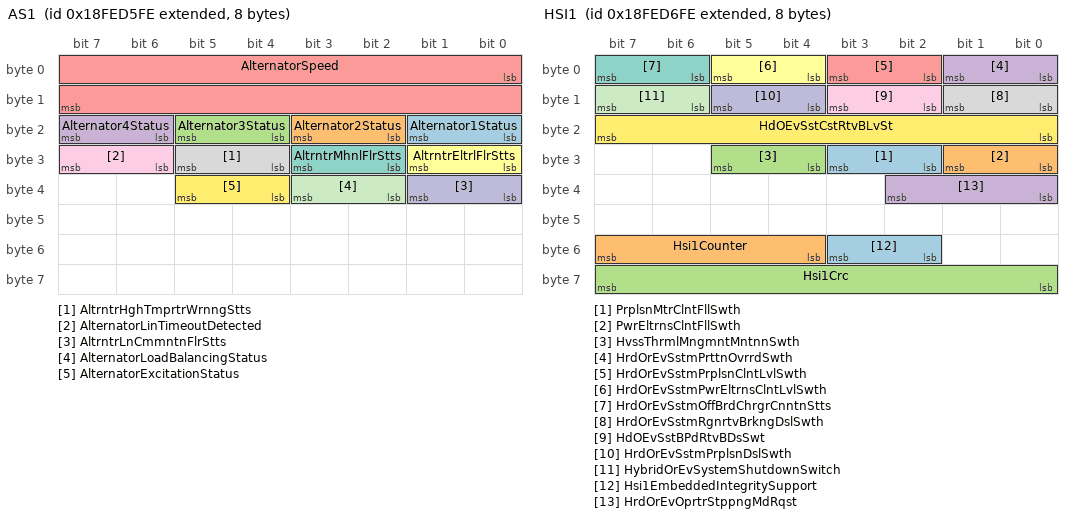
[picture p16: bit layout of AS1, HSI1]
BO_ 2566837758 AS1: 8 Vector__XXX
 SG_ Alternator1Status : 16|2@1+ (1,0) [0|3] "" Vector__XXX
 SG_ Alternator2Status : 18|2@1+ (1,0) [0|3] "" Vector__XXX
 SG_ Alternator3Status : 20|2@1+ (1,0) [0|3] "" Vector__XXX
 SG_ Alternator4Status : 22|2@1+ (1,0) [0|3] "" Vector__XXX
 SG_ AlternatorSpeed : 0|16@1+ (0.5,0) [0|32127.5] "rpm" Vector__XXX
 SG_ AltrntrEltrlFlrStts : 24|2@1+ (1,0) [0|3] "" Vector__XXX
 SG_ AltrntrMhnlFlrStts : 26|2@1+ (1,0) [0|3] "" Vector__XXX
 SG_ AltrntrHghTmprtrWrnngStts : 28|2@1+ (1,0) [0|3] "" Vector__XXX
 SG_ AlternatorLinTimeoutDetected : 30|2@1+ (1,0) [0|3] "" Vector__XXX
 SG_ AltrntrLnCmmntnFlrStts : 32|2@1+ (1,0) [0|3] "" Vector__XXX
 SG_ AlternatorLoadBalancingStatus : 34|2@1+ (1,0) [0|3] "" Vector__XXX
 SG_ AlternatorExcitationStatus : 36|2@1+ (1,0) [0|3] "" Vector__XXX

BO_ 2566838014 HSI1: 8 Vector__XXX
 SG_ PrplsnMtrClntFllSwth : 26|2@1+ (1,0) [0|3] "" Vector__XXX
 SG_ PwrEltrnsClntFllSwth : 24|2@1+ (1,0) [0|3] "" Vector__XXX
 SG_ HvssThrmlMngmntMntnnSwth : 28|2@1+ (1,0) [0|3] "" Vector__XXX
 SG_ HrdOrEvSstmPrttnOvrrdSwth : 0|2@1+ (1,0) [0|3] "" Vector__XXX
 SG_ HrdOrEvSstmPrplsnClntLvlSwth : 2|2@1+ (1,0) [0|3] "" Vector__XXX
 SG_ HrdOrEvSstmPwrEltrnsClntLvlSwth : 4|2@1+ (1,0) [0|3] "" Vector__XXX
 SG_ HrdOrEvSstmOffBrdChrgrCnntnStts : 6|2@1+ (1,0) [0|3] "" Vector__XXX
 SG_ HrdOrEvSstmRgnrtvBrkngDslSwth : 8|2@1+ (1,0) [0|3] "" Vector__XXX
 SG_ HdOEvSstBPdRtvBDsSwt : 10|2@1+ (1,0) [0|3] "" Vector__XXX
 SG_ HrdOrEvSstmPrplsnDslSwth : 12|2@1+ (1,0) [0|3] "" Vector__XXX
 SG_ HybridOrEvSystemShutdownSwitch : 14|2@1+ (1,0) [0|3] "" Vector__XXX
 SG_ HdOEvSstCstRtvBLvSt : 16|8@1+ (0.4,0) [0|100] "%" Vector__XXX
 SG_ Hsi1EmbeddedIntegritySupport : 50|2@1+ (1,0) [0|3] "" Vector__XXX
 SG_ Hsi1Counter : 52|4@1+ (1,0) [0|15] "" Vector__XXX
 SG_ Hsi1Crc : 56|8@1+ (1,0) [0|250] "count" Vector__XXX
 SG_ HrdOrEvOprtrStppngMdRqst : 32|3@1+ (1,0) [0|7] "" Vector__XXX

BO_ 2566838782 AUXIO1: 8 Vector__XXX
 SG_ AuxiliaryIO01 : 6|2@1+ (1,0) [0|3] "" Vector__XXX
 SG_ AuxiliaryIO02 : 4|2@1+ (1,0) [0|3] "" Vector__XXX
 SG_ AuxiliaryIO03 : 2|2@1+ (1,0) [0|3] "" Vector__XXX
 SG_ AuxiliaryIO04 : 0|2@1+ (1,0) [0|3] "" Vector__XXX
 SG_ AuxiliaryIO05 : 14|2@1+ (1,0) [0|3] "" Vector__XXX
 SG_ AuxiliaryIO06 : 12|2@1+ (1,0) [0|3] "" Vector__XXX
 SG_ AuxiliaryIO07 : 10|2@1+ (1,0) [0|3] "" Vector__XXX
 SG_ AuxiliaryIO08 : 8|2@1+ (1,0) [0|3] "" Vector__XXX
 SG_ AuxiliaryIO09 : 22|2@1+ (1,0) [0|3] "" Vector__XXX
 SG_ AuxiliaryIO10 : 20|2@1+ (1,0) [0|3] "" Vector__XXX
 SG_ AuxiliaryIO11 : 18|2@1+ (1,0) [0|3] "" Vector__XXX
 SG_ AuxiliaryIO12 : 16|2@1+ (1,0) [0|3] "" Vector__XXX
 SG_ AuxiliaryIO13 : 30|2@1+ (1,0) [0|3] "" Vector__XXX
 SG_ AuxiliaryIO14 : 28|2@1+ (1,0) [0|3] "" Vector__XXX
 SG_ AuxiliaryIO15 : 26|2@1+ (1,0) [0|3] "" Vector__XXX
 SG_ AuxiliaryIO16 : 24|2@1+ (1,0) [0|3] "" Vector__XXX
 SG_ AuxiliaryIOChannel1 : 32|16@1+ (1,0) [0|64255] "count" Vector__XXX
 SG_ AuxiliaryIOChannel2 : 48|16@1+ (1,0) [0|64255] "count" Vector__XXX

BO_ 2566839038 SOFT: 8 Vector__XXX
 SG_ NmrOfSftwrIdntftnFlds : 0|8@1+ (1,0) [0|125] "step" Vector__XXX

BO_ 2566839294 EFLP2: 8 Vector__XXX
 SG_ EngnFl1InjtrMtrngRl1Prssr : 16|16@1+ (0.00390625,0) [0|250.99609375] "MPa" Vector__XXX
 SG_ EngnFl1InjtrMtrngRl2Prssr : 48|16@1+ (0.00390625,0) [0|250.99609375] "MPa" Vector__XXX
 SG_ EngnFl1InjtrTmngRl1Prssr : 32|16@1+ (0.00390625,0) [0|250.99609375] "MPa" Vector__XXX
 SG_ EngnFlInjtnCntrlPrssr : 0|16@1+ (0.00390625,0) [0|250.99609375] "MPa" Vector__XXX

BO_ 2566839550 IO: 8 Vector__XXX
 SG_ EngineTotalIdleFuelUsed : 0|32@1+ (0.5,0) [0|2105540607.5] "l" Vector__XXX
 SG_ EngineTotalIdleHours : 32|32@1+ (0.05,0) [0|210554060.75] "h" Vector__XXX

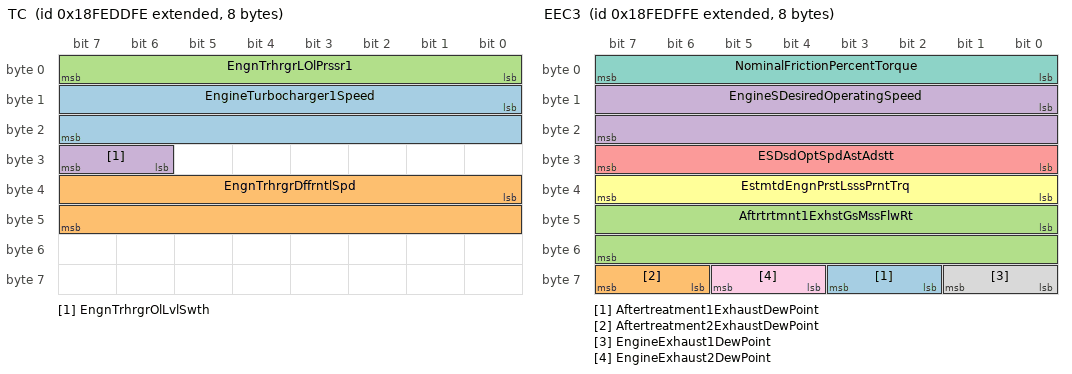
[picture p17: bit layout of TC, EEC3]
BO_ 2566839806 TC: 8 Vector__XXX
 SG_ EngineTurbocharger1Speed : 8|16@1+ (4,0) [0|257020] "rpm" Vector__XXX
 SG_ EngnTrhrgrDffrntlSpd : 32|16@1+ (4,0) [0|257020] "rpm" Vector__XXX
 SG_ EngnTrhrgrLOlPrssr1 : 0|8@1+ (4,0) [0|1000] "kPa" Vector__XXX
 SG_ EngnTrhrgrOlLvlSwth : 30|2@1+ (1,0) [0|3] "" Vector__XXX

BO_ 2566840062 AIR2: 8 Vector__XXX
 SG_ EngineAirStartPressure : 0|8@1+ (4,0) [0|1000] "kPa" Vector__XXX
 SG_ EngineAirStopPressure : 16|8@1+ (4,0) [0|1000] "kPa" Vector__XXX
 SG_ EngnArStrtPrssrExtnddRng : 8|8@1+ (16,0) [0|4000] "kPa" Vector__XXX

BO_ 2566840318 EEC3: 8 Vector__XXX
 SG_ Aftertreatment1ExhaustDewPoint : 58|2@1+ (1,0) [0|3] "" Vector__XXX
 SG_ Aftertreatment2ExhaustDewPoint : 62|2@1+ (1,0) [0|3] "" Vector__XXX
 SG_ Aftrtrtmnt1ExhstGsMssFlwRt : 40|16@1+ (0.2,0) [0|12851] "kg/h" Vector__XXX
 SG_ EngineSDesiredOperatingSpeed : 8|16@1+ (0.125,0) [0|8031.875] "rpm" Vector__XXX
 SG_ ESDsdOptSpdAstAdstt : 24|8@1+ (1,0) [0|250] "" Vector__XXX
 SG_ EstmtdEngnPrstLsssPrntTrq : 32|8@1+ (1,-125) [0|125] "%" Vector__XXX
 SG_ NominalFrictionPercentTorque : 0|8@1+ (1,-125) [-125|125] "%" Vector__XXX
 SG_ EngineExhaust1DewPoint : 56|2@1+ (1,0) [0|3] "" Vector__XXX
 SG_ EngineExhaust2DewPoint : 60|2@1+ (1,0) [0|3] "" Vector__XXX

BO_ 2566840574 VD: 8 Vector__XXX
 SG_ TotalVehicleDistance : 32|32@1+ (0.125,0) [0|526385151.875] "km" Vector__XXX
 SG_ TripDistance : 0|32@1+ (0.125,0) [0|526385151.875] "km" Vector__XXX

BO_ 2566840830 RC: 19 Vector__XXX
 SG_ MaximumRetarderSpeedPoint2 : 40|16@1+ (0.125,0) [0|8031.875] "rpm" Vector__XXX
 SG_ RetarderControlMethod : 8|8@1+ (1,0) [0|250] "step" Vector__XXX
 SG_ RetarderLocation : 4|4@1+ (1,0) [0|15] "" Vector__XXX
 SG_ RetarderPercentTorqueAtPoint3 : 80|8@1+ (1,-125) [-125|0] "%" Vector__XXX
 SG_ RetarderPercentTorqueAtPoint4 : 104|8@1+ (1,-125) [-125|0] "%" Vector__XXX
 SG_ RetarderReferenceTorque : 128|16@1+ (1,0) [0|64255] "Nm" Vector__XXX
 SG_ RetarderSpeedAtIdlePoint1 : 16|16@1+ (0.125,0) [0|8031.875] "rpm" Vector__XXX
 SG_ RetarderSpeedAtPeakTorquePoint5 : 112|16@1+ (0.125,0) [0|8031.875] "rpm" Vector__XXX
 SG_ RetarderSpeedAtPoint3 : 64|16@1+ (0.125,0) [0|8031.875] "rpm" Vector__XXX
 SG_ RetarderSpeedAtPoint4 : 88|16@1+ (0.125,0) [0|8031.875] "rpm" Vector__XXX
 SG_ RetarderType : 0|4@1+ (1,0) [0|15] "" Vector__XXX
 SG_ RtrdrPrntTrqAtIdlPnt1 : 32|8@1+ (1,-125) [-125|0] "%" Vector__XXX
 SG_ RtrdrPrntTrqAtMxmmSpdPnt2 : 56|8@1+ (1,-125) [-125|0] "%" Vector__XXX
 SG_ RtrdrPrntTrqAtPkTrqPnt5 : 144|8@1+ (1,-125) [-125|0] "%" Vector__XXX

BO_ 2566841086 TCFG: 8 Vector__XXX
 SG_ NumberOfForwardGearRatios : 8|8@1+ (1,0) [0|125] "gear value" Vector__XXX
 SG_ NumberOfReverseGearRatios : 0|8@1+ (1,0) [0|125] "gear value" Vector__XXX
 SG_ TransmissionGearRatio : 16|16@1+ (0.001,0) [0|64.255] "" Vector__XXX

BO_ 2566841342 EC1: 42 Vector__XXX
 SG_ EngineDefaultIdleTorqueLimit : 312|8@1+ (1,-125) [0|125] "%" Vector__XXX
 SG_ EngineDefaultTorqueLimit : 256|16@1+ (1,0) [0|64255] "Nm" Vector__XXX
 SG_ EngineMomentOfInertia : 240|16@1+ (0.004,0) [0|257.02] "kg*(m*m)" Vector__XXX
 SG_ EnginePercentTorqueAtIdlePoint1 : 16|8@1+ (1,-125) [0|125] "%" Vector__XXX
 SG_ EnginePercentTorqueAtPoint2 : 40|8@1+ (1,-125) [0|125] "%" Vector__XXX
 SG_ EnginePercentTorqueAtPoint3 : 64|8@1+ (1,-125) [0|125] "%" Vector__XXX
 SG_ EnginePercentTorqueAtPoint4 : 88|8@1+ (1,-125) [0|125] "%" Vector__XXX
 SG_ EnginePercentTorqueAtPoint5 : 112|8@1+ (1,-125) [0|125] "%" Vector__XXX
 SG_ EngineReferenceTorque : 152|16@1+ (1,0) [0|64255] "Nm" Vector__XXX
 SG_ EngineSpeedAtHighIdlePoint6 : 120|16@1+ (0.125,0) [0|8031.875] "rpm" Vector__XXX
 SG_ EngineSpeedAtIdlePoint1 : 0|16@1+ (0.125,0) [0|8031.875] "rpm" Vector__XXX
 SG_ EngineSpeedAtPoint2 : 24|16@1+ (0.125,0) [0|8031.875] "rpm" Vector__XXX
 SG_ EngineSpeedAtPoint3 : 48|16@1+ (0.125,0) [0|8031.875] "rpm" Vector__XXX
 SG_ EngineSpeedAtPoint4 : 72|16@1+ (0.125,0) [0|8031.875] "rpm" Vector__XXX
 SG_ EngineSpeedAtPoint5 : 96|16@1+ (0.125,0) [0|8031.875] "rpm" Vector__XXX
 SG_ EngnGnKpOfThEndspdGvrnr : 136|16@1+ (0.00078125,0) [0|50.19921875] "%/rpm" Vector__XXX
 SG_ EngnMxmmMmntrOvrrdSpdPnt7 : 168|16@1+ (0.125,0) [0|8031.875] "rpm" Vector__XXX
 SG_ EngnMxmmMmntrOvrrdTmLmt : 184|8@1+ (0.1,0) [0|25] "s" Vector__XXX
 SG_ EngnRqstdSpdCntrlRngLwrLmt : 192|8@1+ (10,0) [0|2500] "rpm" Vector__XXX
 SG_ EngnRqstdSpdCntrlRngUpprLmt : 200|8@1+ (10,0) [0|2500] "rpm" Vector__XXX
 SG_ EngnRqstdTrqCntrlRngLwrLmt : 208|8@1+ (1,-125) [0|125] "%" Vector__XXX
 SG_ EngnRqstdTrqCntrlRngUpprLmt : 216|8@1+ (1,-125) [0|125] "%" Vector__XXX
 SG_ ERqstdSpdCtRUppLtExtddR : 224|16@1+ (0.125,0) [0|8031.875] "rpm" Vector__XXX
 SG_ SupportTsc1ControlPurposeGroup1 : 280|8@1+ (1,0) [0|250] "" Vector__XXX
 SG_ SupportTsc1ControlPurposeGroup2 : 288|8@1+ (1,0) [0|250] "" Vector__XXX
 SG_ SupportTsc1ControlPurposeGroup3 : 296|8@1+ (1,0) [0|250] "" Vector__XXX
 SG_ SupportTsc1ControlPurposeGroup4 : 304|8@1+ (1,0) [0|250] "" Vector__XXX
 SG_ SupportVariableRateTsc1Message : 272|8@1+ (1,0) [0|250] "" Vector__XXX
 SG_ EngineDefaultSpeedLimit : 320|16@1+ (0.125,0) [0|8031.875] "rpm" Vector__XXX

BO_ 2566841598 SHUTDN: 8 Vector__XXX
 SG_ ACHighPressureFanSwitch : 16|2@1+ (1,0) [0|3] "" Vector__XXX
 SG_ ClntLvlEngnPrttnShtdwnStts : 60|2@1+ (1,0) [0|3] "" Vector__XXX
 SG_ EngineAirShutoffCommandStatus : 52|2@1+ (1,0) [0|3] "" Vector__XXX
 SG_ EngineAirShutoffStatus : 56|2@1+ (1,0) [0|3] "" Vector__XXX
 SG_ EngineAlarmAcknowledge : 48|2@1+ (1,0) [0|3] "" Vector__XXX
 SG_ EngineAlarmOutputCommandStatus : 50|2@1+ (1,0) [0|3] "" Vector__XXX
 SG_ EngineIdleShutdownTimerFunction : 14|2@1+ (1,0) [0|3] "" Vector__XXX
 SG_ EngineIdleShutdownTimerOverride : 4|2@1+ (1,0) [0|3] "" Vector__XXX
 SG_ EngineIdleShutdownTimerState : 6|2@1+ (1,0) [0|3] "" Vector__XXX
 SG_ EngineOilPressureSwitch : 62|2@1+ (1,0) [0|3] "" Vector__XXX
 SG_ EngineOverspeedTest : 54|2@1+ (1,0) [0|3] "" Vector__XXX
 SG_ EngineWaitToStartLamp : 24|2@1+ (1,0) [0|3] "" Vector__XXX
 SG_ EngnIdlShtdwnDrvrAlrtMd : 2|2@1+ (1,0) [0|3] "" Vector__XXX
 SG_ EngnIdlShtdwnHsShtdwnEngn : 0|2@1+ (1,0) [0|3] "" Vector__XXX
 SG_ EngnPrttnSstmApprhngShtdwn : 34|2@1+ (1,0) [0|3] "" Vector__XXX
 SG_ EngnPrttnSstmCnfgrtn : 46|2@1+ (1,0) [0|3] "" Vector__XXX
 SG_ EngnPrttnSstmHsShtdwnEngn : 32|2@1+ (1,0) [0|3] "" Vector__XXX
 SG_ EngnPrttnSstmTmrOvrrd : 36|2@1+ (1,0) [0|3] "" Vector__XXX
 SG_ EngnPrttnSstmTmrStt : 38|2@1+ (1,0) [0|3] "" Vector__XXX
 SG_ PtoShutdownHasShutdownEngine : 58|2@1+ (1,0) [0|3] "" Vector__XXX
 SG_ RefrigerantHighPressureSwitch : 20|2@1+ (1,0) [0|3] "" Vector__XXX
 SG_ RefrigerantLowPressureSwitch : 18|2@1+ (1,0) [0|3] "" Vector__XXX
 SG_ MhnIntvtShtdwnHsShtdwnEngn : 26|2@1+ (1,0) [0|3] "" Vector__XXX

BO_ 2566841854 HOURS: 8 Vector__XXX
 SG_ EngineTotalHoursOfOperation : 0|32@1+ (0.05,0) [0|210554060.75] "h" Vector__XXX
 SG_ EngineTotalRevolutions : 32|32@1+ (1000,0) [0|4211081215000] "r" Vector__XXX

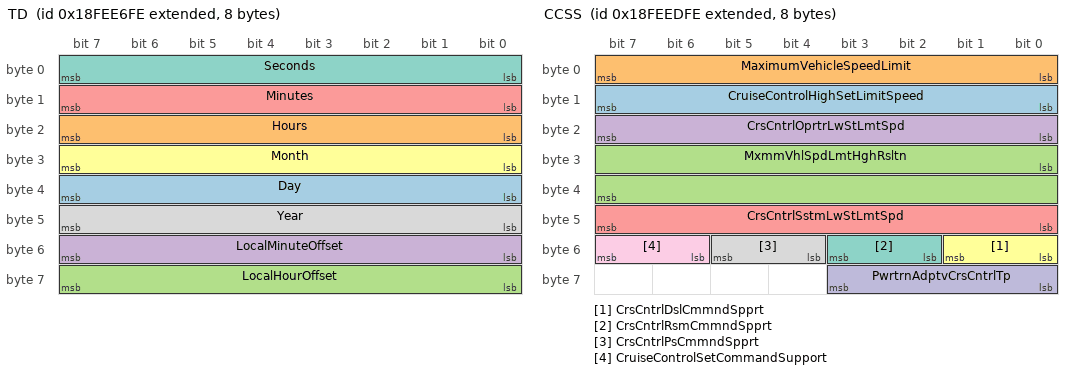
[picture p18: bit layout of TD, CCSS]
BO_ 2566842110 TD: 8 Vector__XXX
 SG_ Day : 32|8@1+ (0.25,0) [0.25|31.75] "days" Vector__XXX
 SG_ Hours : 16|8@1+ (1,0) [0|23] "h" Vector__XXX
 SG_ LocalHourOffset : 56|8@1+ (1,-125) [-23|23] "h" Vector__XXX
 SG_ LocalMinuteOffset : 48|8@1+ (1,-125) [-59|59] "min" Vector__XXX
 SG_ Minutes : 8|8@1+ (1,0) [0|59] "min" Vector__XXX
 SG_ Month : 24|8@1+ (1,0) [1|12] "month" Vector__XXX
 SG_ Seconds : 0|8@1+ (0.25,0) [0|59.75] "s" Vector__XXX
 SG_ Year : 40|8@1+ (1,1985) [1985|2235] "year" Vector__XXX

BO_ 2566842366 VH: 8 Vector__XXX
 SG_ TotalPowerTakeoffHours : 32|32@1+ (0.05,0) [0|210554060.75] "h" Vector__XXX
 SG_ TotalVehicleHours : 0|32@1+ (0.05,0) [0|210554060.75] "h" Vector__XXX

BO_ 2566842622 VDS: 8 Vector__XXX
 SG_ Altitude : 48|16@1+ (0.125,-2500) [-2500|5531.875] "m" Vector__XXX
 SG_ CompassBearing : 0|16@1+ (0.0078125,0) [0|501.9921875] "deg" Vector__XXX
 SG_ NavigationBasedVehicleSpeed : 16|16@1+ (0.00390625,0) [0|250.99609375] "km/h" Vector__XXX
 SG_ Pitch : 32|16@1+ (0.0078125,-200) [-200|301.9921875] "deg" Vector__XXX

BO_ 2566842878 LFC1: 8 Vector__XXX
 SG_ EngineTotalFuelUsed : 32|32@1+ (0.5,0) [0|2105540607.5] "l" Vector__XXX
 SG_ EngineTripFuel : 0|32@1+ (0.5,0) [0|2105540607.5] "l" Vector__XXX

BO_ 2566843134 VW: 8 Vector__XXX
 SG_ AxleLocation : 0|8@1+ (1,0) [0|250] "" Vector__XXX
 SG_ AxleWeight : 8|16@1+ (0.5,0) [0|32127.5] "kg" Vector__XXX
 SG_ CargoWeight : 40|16@1+ (2,0) [0|128510] "kg" Vector__XXX
 SG_ TrailerWeight : 24|16@1+ (2,0) [0|128510] "kg" Vector__XXX

BO_ 2566843902 CCSS: 8 Vector__XXX
 SG_ CruiseControlHighSetLimitSpeed : 8|8@1+ (1,0) [0|250] "km/h" Vector__XXX
 SG_ MaximumVehicleSpeedLimit : 0|8@1+ (1,0) [0|250] "km/h" Vector__XXX
 SG_ MxmmVhlSpdLmtHghRsltn : 24|16@1+ (0.00390625,0) [0|250.99609375] "km/h" Vector__XXX
 SG_ CrsCntrlOprtrLwStLmtSpd : 16|8@1+ (1,0) [0|250] "km/h" Vector__XXX
 SG_ CrsCntrlSstmLwStLmtSpd : 40|8@1+ (1,0) [0|250] "km/h" Vector__XXX
 SG_ CrsCntrlDslCmmndSpprt : 48|2@1+ (1,0) [0|3] "" Vector__XXX
 SG_ CrsCntrlRsmCmmndSpprt : 50|2@1+ (1,0) [0|3] "" Vector__XXX
 SG_ CrsCntrlPsCmmndSpprt : 52|2@1+ (1,0) [0|3] "" Vector__XXX
 SG_ CruiseControlSetCommandSupport : 54|2@1+ (1,0) [0|3] "" Vector__XXX
 SG_ PwrtrnAdptvCrsCntrlTp : 56|4@1+ (1,0) [0|15] "" Vector__XXX

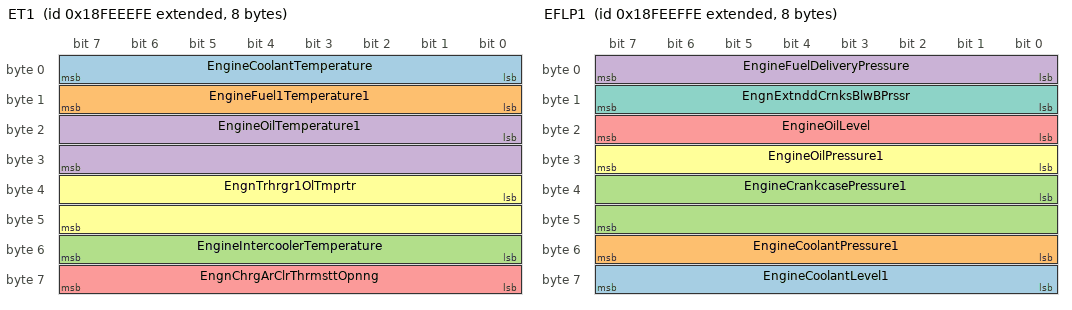
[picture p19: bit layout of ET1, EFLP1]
BO_ 2566844158 ET1: 8 Vector__XXX
 SG_ EngineCoolantTemperature : 0|8@1+ (1,-40) [-40|210] "degC" Vector__XXX
 SG_ EngineFuel1Temperature1 : 8|8@1+ (1,-40) [-40|210] "degC" Vector__XXX
 SG_ EngineIntercoolerTemperature : 48|8@1+ (1,-40) [-40|210] "degC" Vector__XXX
 SG_ EngineOilTemperature1 : 16|16@1+ (0.03125,-273) [-273|1734.96875] "degC" Vector__XXX
 SG_ EngnChrgArClrThrmsttOpnng : 56|8@1+ (0.4,0) [0|100] "%" Vector__XXX
 SG_ EngnTrhrgr1OlTmprtr : 32|16@1+ (0.03125,-273) [-273|1734.96875] "degC" Vector__XXX

BO_ 2566844414 EFLP1: 8 Vector__XXX
 SG_ EngineCoolantLevel1 : 56|8@1+ (0.4,0) [0|100] "%" Vector__XXX
 SG_ EngineCoolantPressure1 : 48|8@1+ (2,0) [0|500] "kPa" Vector__XXX
 SG_ EngineCrankcasePressure1 : 32|16@1+ (0.0078125,-250) [-250|251.9921875] "kPa" Vector__XXX
 SG_ EngineFuelDeliveryPressure : 0|8@1+ (4,0) [0|1000] "kPa" Vector__XXX
 SG_ EngineOilLevel : 16|8@1+ (0.4,0) [0|100] "%" Vector__XXX
 SG_ EngineOilPressure1 : 24|8@1+ (4,0) [0|1000] "kPa" Vector__XXX
 SG_ EngnExtnddCrnksBlwBPrssr : 8|8@1+ (0.05,0) [0|12.5] "kPa" Vector__XXX

CM_ BO_ 2566775294 "Cab Climate System Information 1";
CM_ SG_ 2566775294 AirConditionerCompressorStatus "Air Conditioner Compressor Status: Signal which indicates if the Air Conditioner compressor is on or off.00b = Air Conditioner Compressor is OFF01b = Air Conditioner Compressor is ON10b = Error11b = Not Available";
CM_ SG_ 2566775294 CACRfrgrntCmprssrOtltPrssr "Cab A/C Refrigerant Compressor Outlet Pressure: This is the gage pressure at the compressor outlet in the cab air conditioning system.";
CM_ SG_ 2566775294 FrntCnBlwrFnSpdStpnt "Front Cabin Blower Fan Speed Setpoint: Speed at which the cabin front HVAC blower fan is being controlled.  100% represents the highest available fan speed.";
CM_ SG_ 2566775294 CabACAutoModeSwitch "Cab A/C Auto Mode Switch: Indicates whether HVAC auto mode is selected.00b = HVAC auto mode is selected OFF01b = HVAC auto mode is selected ON10b = Error11b = Not Available";
CM_ SG_ 2566775294 CabACMaximumDefrostModeSwitch "Cab A/C Maximum Defrost Mode Switch: Indicates whether HVAC maximum defrost mode is selected.00b = HVAC Maximum Defrost mode is selected OFF01b = HVAC Maximum Defrost mode is selected ON10b = Error11b = Not Available";
CM_ SG_ 2566775294 CabACRecirculationModeSwitch "Cab A/C Recirculation Mode Switch: Indicates whether HVAC recirculation mode is selected.00b = HVAC recirculation mode is selected OFF (fresh air)01b = HVAC recirculation mode is selected ON (cabin air)10b = Error11b = Not Available";
CM_ SG_ 2566775294 ACEvaporatorTemperature "A/C Evaporator Temperature: Temperature of the HVAC evaporator.";
CM_ SG_ 2566775294 CACRfrgrntCmprssrStnPrssr "Cab A/C Refrigerant Compressor Suction Pressure: The gage pressure at the suction or intake side of the compressor in the cab air conditioning system.Note:  Sometimes called the low side pressure.";
CM_ SG_ 2566775294 CabACAirDistributionModeSwitch "Cab A/C Air Distribution Mode Switch: Indicates which HVAC Air Distribution mode is selected. Modes are manufacturer and application specific (but may include for example, defrost, defrost & vents, vents, etc.)0000b = Mode 10001b = Mode 20010b = Mode...";
CM_ BO_ 2566775550 "Supply Pressure Demand";
CM_ SG_ 2566775550 ArSspnsnSpplPrssrRqst "Air Suspension Supply Pressure Request: Command signal to influence the pneumatic pressure in the circuit for the electronically controlled air suspension system.   This parameter is the setpoint for the parameter SPN 1090.";
CM_ SG_ 2566775550 AxlrEqpmntSpplPrssrRqst "Auxiliary Equipment Supply Pressure Request: Command signal to influence the pneumatic pressure in the auxiliary circuit.   This parameter is the setpoint for the parameter SPN 1089.";
CM_ SG_ 2566775550 PneumaticSupplyPressureRequest "Pneumatic Supply Pressure Request: Command signal to influence the pneumatic pressure in the main reservoir.  This parameter is the setpoint for the parameter SPN 46.";
CM_ SG_ 2566775550 PwrtrnCrtArSpplPrssrRqst "Powertrain Circuit Air Supply Pressure Request: Command signal to influence the air pressure in the powertrain circuit.  This parameter is the setpoint for the parameter SPN 6305.";
CM_ SG_ 2566775550 SrvBrkArPrssrRqstCrt1 "Service Brake Air Pressure Request, Circuit #1: Command signal to influence the pneumatic pressure in the service brake circuit or reservoir #1.  This parameter is the setpoint for the parameter SPN 1087.";
CM_ SG_ 2566775550 SrvBrkArPrssrRqstCrt2 "Service Brake Air Pressure Request, Circuit #2: Command signal to influence the pneumatic pressure in the service brake circuit or reservoir #2.  This parameter is the setpoint for the parameter SPN 1088.";
CM_ SG_ 2566775550 PrkngAndOrTrlrArPrssrRqst "Parking and/or Trailer Air Pressure Request: Command signal to influence the pneumatic pressure in the circuit or reservoir for the parking brake and/or the trailer supply.  This parameter is the setpoint for the parameter SPN 1086.";
CM_ BO_ 2566775806 "Equipment Operation and Control";
CM_ SG_ 2566775806 TravelVelocityControlPosition "Travel Velocity Control Position: The position of the travel velocity control component reported as a percentage of the control's full displacement in each direction respectively.  Positive position values indicate forward travel direction;  negative...";
CM_ BO_ 2566776062 "Equipment Performance Data";
CM_ SG_ 2566776062 PayloadCapacityPercentage "Payload Capacity Percentage: The current equipment payload plus the weight of any after-factory modifications reported as a percentage of the equipment's maximum payload capacity. The equipment's maximum payload capacity is the maximum capacity of th...";
CM_ SG_ 2566776062 PayloadCarryBackWeight "Payload Carry Back Weight: The payload weight left on the machine after the last payload dump event.";
CM_ SG_ 2566776062 PayloadPercentage "Payload Percentage: The current payload of the equipment, reported as a percentage of the equipment's rated payload limit.";
CM_ SG_ 2566776062 PayloadWeight "Payload Weight: The current payload weight carried by the machine.";
CM_ SG_ 2566776062 PayloadWeightConfidence "Payload Weight Confidence: The level of confidence of the real time payload weight measurement (SPN 6851). Higher confidence values indicate greater probability the real time payload weight is the actual weight and providing feedback on the potential...";
CM_ BO_ 2566776318 "Maximum Vehicle Speed Limit Status";
CM_ SG_ 2566776318 AppliedVehicleSpeedLimit "Applied Vehicle Speed Limit: The vehicle speed limit in effect.251 (FBh) is used to indicate that a maximum vehicle speed limit is not selected.See SPN 7420 for alternate resolution.";
CM_ SG_ 2566776318 MaximumVehicleSpeedLimit1 "Maximum Vehicle Speed Limit 1: The lowest Maximum Vehicle Speed Limit. This value is the similar to SPN 74. However, SPN 74 was not specifically defined to convey the applied vehicle speed limit or what was possible to be applied. This new SP is the ...";
CM_ SG_ 2566776318 MaximumVehicleSpeedLimit2 "Maximum Vehicle Speed Limit 2: The highest of the two lowest vehicle speed limits";
CM_ SG_ 2566776318 MaximumVehicleSpeedLimit3 "Maximum Vehicle Speed Limit 3: The highest of the three lowest vehicle speed limits";
CM_ SG_ 2566776318 MaximumVehicleSpeedLimit4 "Maximum Vehicle Speed Limit 4: The highest of the four lowest vehicle speed limits";
CM_ SG_ 2566776318 MaximumVehicleSpeedLimit5 "Maximum Vehicle Speed Limit 5: The highest of the five lowest vehicle speed limits";
CM_ SG_ 2566776318 MaximumVehicleSpeedLimit6 "Maximum Vehicle Speed Limit 6: The highest of the six lowest vehicle speed limits";
CM_ SG_ 2566776318 MaximumVehicleSpeedLimit7 "Maximum Vehicle Speed Limit 7: The highest of the seven lowest vehicle speed limits";
CM_ BO_ 2566785022 "Exhaust Temperature";
CM_ SG_ 2566785022 EngnExhstMnfldBnk1Tmprtr1 "Engine Exhaust Manifold Bank 1 Temperature 1: Temperature of combustion byproducts measured in engine bank 1 (left bank) exhaust manifold.  Single manifold engines should use exhaust temperature (SPN 173).";
CM_ SG_ 2566785022 EngnExhstMnfldBnk1Tmprtr2 "Engine Exhaust Manifold Bank 1 Temperature 2: Temperature of combustion byproducts measured by a second sensor in engine bank 1 (left bank) exhaust manifold. This should be used for the sensor toward the rear of the engine on the bank 1 manifold.";
CM_ SG_ 2566785022 EngnExhstMnfldBnk2Tmprtr1 "Engine Exhaust Manifold Bank 2 Temperature 1: Temperature of combustion byproducts measured in engine bank 2 (right bank) exhaust manifold.  Single manifold engines should use exhaust temperature (SPN 173).";
CM_ SG_ 2566785022 EngnExhstMnfldBnk2Tmprtr2 "Engine Exhaust Manifold Bank 2 Temperature 2: Temperature of combustion byproducts measured by a second sensor in engine bank 2 (right bank) exhaust manifold. This should be used for the sensor toward the rear of the engine on the bank 2 manifold.";
CM_ BO_ 2566799614 "Lighting Data";
CM_ SG_ 2566799614 AlternateBeamHeadLightData "Alternate Beam Head Light Data: This parameter provides measured data from the tractor alternate beam head light lamps. 00b = De-activated01b = Activated10b = Fault Detected11b = Not Available";
CM_ SG_ 2566799614 BackUpLightAndAlarmHorn "Back Up Light and Alarm Horn: This parameter provides measured data from the back up lights and/ or associated alarm.00b = De-activated01b = Activated10b = Fault Detected11b = Not Available";
CM_ SG_ 2566799614 CenterStopLight "Center Stop Light: This parameter provides measured data from the tractor and attached implement center stop lights.00b = De-activated01b = Activated10b = Fault Detected11b = Not Available";
CM_ SG_ 2566799614 HighBeamHeadLightData "High Beam Head Light Data: This parameter provides measured data from the tractor high beam head light lamps. 00b = De-activated01b = Activated10b = Fault Detected11b = Not Available";
CM_ SG_ 2566799614 ImplementClearanceLight "Implement Clearance Light: This parameter provides measured data from an attached implement high mounted clearance lights.00b = De-activated01b = Activated10b = Fault Detected11b = Not Available";
CM_ SG_ 2566799614 ImplementLeftFacingWorkLight "Implement Left Facing Work Light: This parameter provides measured data from the left facing work lights toward the left end of the implement.00b = De-activated01b = Activated10b = Fault Detected11b = Not Available";
CM_ SG_ 2566799614 ImplementLeftForwardWorkLight "Implement Left Forward Work Light: This parameter provides measured data from the work lights mounted on an implement to illuminate the forward left end of the implement.00b = De-activate01b = Activate10b = Fault Detected11b = Not Available";
CM_ SG_ 2566799614 ImplementMarkerLight "Implement Marker Light: This parameter provides measured data from an attached implement marker lights, including front position lights, rear tail lights, side running lights, license plate lights and instruments and switch back lights.00b = De-activ...";
CM_ SG_ 2566799614 ImplementOemOption1Light "Implement OEM Option 1 Light: This parameter provides measured data from the implement OEM option 1 light.00b = De-activated01b = Activated10b = Fault Detected11b = Not Available";
CM_ SG_ 2566799614 ImplementOemOption2Light "Implement OEM Option 2 Light: This parameter provides measured data from the implement OEM option 2 light.00b = De-activated01b = Activated10b = Fault Detected11b = Not Available";
CM_ SG_ 2566799614 ImplementRearWorkLight "Implement Rear Work Light: This parameter provides measured data from the implement rear work lamps.00b = De-activated01b = Activated10b = Fault Detected11b = Not Available";
CM_ SG_ 2566799614 ImplementRightFacingWorkLight "Implement Right Facing Work Light: This parameter provides measured data from the work lights mounted on an implement to illuminate beyond right end of the implement.00b = De-activated01b = Activated10b = Fault Detected11b = Not Available";
CM_ SG_ 2566799614 ImplementRightForwardWorkLight "Implement Right Forward Work Light: This parameter provides measured data from the forward facing work lights toward the right end of the implement.00b = De-activated01b = Activated10b = Fault Detected11b = Not Available";
CM_ SG_ 2566799614 LeftStopLight "Left Stop Light: This parameter provides measured data from the tractor and attached implement left stop lights.00b = De-activated01b = Activated10b = Fault Detected11b = Not Available";
CM_ SG_ 2566799614 LeftTurnSignalLights "Left Turn Signal Lights: This parameter provides measured data from the tractor and attached implement left turn signal lights.00b = De-activated01b = Activated10b = Fault Detected11b = Not Available";
CM_ SG_ 2566799614 LowBeamHeadLightData "Low Beam Head Light Data: This parameter provides measured data from the tractor low beam head light lamps. 00b = De-activated01b = Activated10b = Fault Detected11b = Not Available";
CM_ SG_ 2566799614 RearFogLights "Rear Fog Lights: This parameter provides measured data from the tractor and/or implement rear fog lights.00b = De-activated01b = Activated10b = Fault Detected11b = Not Available";
CM_ SG_ 2566799614 RightStopLight "Right Stop Light: This parameter provides measured data from the tractor and attached implement right stop lights.00b = De-activated01b = Activated10b = Fault Detected11b = Not Available";
CM_ SG_ 2566799614 RightTurnSignalLights "Right Turn Signal Lights: This parameter provides measured data from the tractor and attached implement right turn signal lights.00b = De-activated01b = Activated10b = Fault Detected11b = Not Available";
CM_ SG_ 2566799614 RotatingBeaconLight "Rotating Beacon Light: This parameter provides measured data from the beacon light on tractor or attached implements.00b = De-activated01b = Activated10b = Fault Detected11b = Not Available";
CM_ SG_ 2566799614 RunningLight "Running Light: This parameter provides measured data from the vehicle's running lights.00b = De-activated01b = Activated10b = Fault Detected11b = Not Available";
CM_ SG_ 2566799614 TractorClearanceLight "Tractor Clearance Light: This parameter provides measured data from the tractor high mounted clearance and center ID lights.00b = De-activated01b = Activated10b = Fault Detected11b = Not Available";
CM_ SG_ 2566799614 TractorFrontFogLights "Tractor Front Fog Lights: This parameter provides measured data from the tractor front fog lights.00b = De-activated01b = Activated10b = Fault Detected11b = Not Available";
CM_ SG_ 2566799614 TractorMarkerLight "Tractor Marker Light: This parameter provides measured data from the tractor and attached implement marker lights, including front position lights, rear tail lights, side running lights, license plate lights and instruments and switch back lights.00b...";
CM_ SG_ 2566799614 TractorRearLowMountedWorkLights "Tractor Rear Low Mounted Work Lights: This parameter provides measured data from the tractor rear low mounted work lights.00b = De-activated01b = Activated10b = Fault Detected11b = Not Available";
CM_ SG_ 2566799614 TractorSideLowMountedWorkLights "Tractor Side Low Mounted Work Lights: This parameter provides measured data from the tractor side low mounted work lights. 00b = De-activated01b = Activated10b = Fault Detected11b = Not Available";
CM_ SG_ 2566799614 TrtrFrntHghMntdWrkLghts "Tractor Front High Mounted Work Lights: This parameter provides measured data from the tractor front high mounted work lights. 00b = De-activated01b = Activated10b = Fault Detected11b = Not Available";
CM_ SG_ 2566799614 TrtrFrntLwMntdWrkLghts "Tractor Front Low Mounted Work Lights: This parameter provides measured data from the tractor front low mounted work lights. 00b = De-activated01b = Activated10b = Fault Detected11b = Not Available";
CM_ SG_ 2566799614 TrtrRrHghMntdWrkLghts "Tractor Rear High Mounted Work Lights: This parameter provides measured data from the tractor rear high mounted work lights. 00b = De-activated01b = Activated10b = Fault Detected11b = Not Available";
CM_ SG_ 2566799614 TrtrSdHghMntdWrkLghts "Tractor Side High Mounted Work Lights: This parameter provides measured data from the tractor side high mounted work lights. 00b = De-activated01b = Activated10b = Fault Detected11b = Not Available";
CM_ SG_ 2566799614 TrtrUndrsdMntdWrkLghts "Tractor Underside Mounted Work Lights: This parameter provides measured data from the tractor underside mounted work lights. 00b = De-activated01b = Activated10b = Fault Detected11b = Not Available";
CM_ BO_ 2566802174 "Electronic Transmission Controller 7";
CM_ SG_ 2566802174 ActiveShiftConsoleIndicator "Active Shift Console Indicator: Signal from transmission control unit indicating which shift console (primary or secondary) it currently considers as the active shift selector input.00b = Primary shift console is active01b = Secondary shift console i...";
CM_ SG_ 2566802174 TransmissionEngineCrankEnable "Transmission Engine Crank Enable: State signal from the transmission indicating if the transmission's status is such that engine cranking is allowed (i.e.  at a minimum, transmission is in neutral and the driveline is disengaged).  As sender of this ...";
CM_ SG_ 2566802174 TransmissionManualModeIndicator "Transmission Manual Mode Indicator: This parameter indicates if the operator has selected a Manual Mode of the transmission. When a Manual Mode is active, the operator has directly and intentionally restricted the available transmission ranges for th...";
CM_ SG_ 2566802174 TransmissionMode10Indicator "Transmission Mode 10 Indicator: Indicates that the transmission is operating under transmission mode 10 (SPN 6570) as commanded via the TC2 message (PGN 3328). The definition of the transmission mode is left to the discretion of the transmission manu...";
CM_ SG_ 2566802174 TransmissionMode1Indicator "Transmission Mode 1 Indicator: This state signal is the transmission's indication that it is operating under transmission mode 1 (SPN 1852) as commanded via the TC1 message (PGN 256).  The definition of the transmission mode is left to the discretion...";
CM_ SG_ 2566802174 TransmissionMode2Indicator "Transmission Mode 2 Indicator: This state signal is the transmission's indication that it is operating under transmission mode 2 (SPN 1853) as commanded via the TC1 message (PGN 256).  The definition of the transmission mode is left to the discretion...";
CM_ SG_ 2566802174 TransmissionMode3Indicator "Transmission Mode 3 Indicator: This state signal is the transmission's indication that it is operating under transmission mode 3 (SPN 1854) as commanded via the TC1 message (PGN 256).  The definition of the transmission mode is left to the discretion...";
CM_ SG_ 2566802174 TransmissionMode4Indicator "Transmission Mode 4 Indicator: This state signal is the transmission's indication that it is operating under transmission mode 4 (SPN 1855) as commanded via the TC1 message (PGN 256).  The definition of the transmission mode is left to the discretion...";
CM_ SG_ 2566802174 TransmissionMode5Indicator "Transmission Mode 5 Indicator: This state signal is the transmission's indication that it is operating under transmission mode 5 (SPN 4246) as commanded via the TC1 message (PGN 256).  The definition of the transmission mode is left to the discretion...";
CM_ SG_ 2566802174 TransmissionMode6Indicator "Transmission Mode 6 Indicator: This state signal is the transmission's indication that it is operating under transmission mode 6 (SPN 4247) as commanded via the TC1 message (PGN 256).  The definition of the transmission mode is left to the discretion...";
CM_ SG_ 2566802174 TransmissionMode7Indicator "Transmission Mode 7 Indicator: This state signal is the transmission's indication that it is operating under transmission mode 7 (SPN 4248) as commanded via the TC1 message (PGN 256).  The definition of the transmission mode is left to the discretion...";
CM_ SG_ 2566802174 TransmissionMode8Indicator "Transmission Mode 8 Indicator: This state signal is the transmission's indication that it is operating under transmission mode 8 (SPN 4249) as commanded via the TC1 message (PGN 256).  The definition of the transmission mode is left to the discretion...";
CM_ SG_ 2566802174 TransmissionMode9Indicator "Transmission Mode 9 Indicator: Indicates that the transmission is operating under transmission mode 9 (SPN 6569) as commanded via the TC2 message (PGN 3328). The definition of the transmission mode is left to the discretion of the transmission manufa...";
CM_ SG_ 2566802174 TransmissionServiceIndicator "Transmission Service Indicator: Signal from transmission indicating that some aspect of the gearbox requires servicing, such as the oil, filter, clutch(es) or other component.00b = Transmission Service Indicator is off01b = Transmission Service Indic...";
CM_ SG_ 2566802174 TransmissionWarningIndicator "Transmission Warning Indicator: Signal from transmission indicating that some aspect of its operation is not functioning correctly, and as a result, transmission operation may be altered or restricted.  The indicator is typically a lamp.  Distinction...";
CM_ SG_ 2566802174 TrnsmssnArSpplPrssrIndtr "Transmission Air Supply Pressure Indicator: Indicates whether transmission air supply is sufficient000b = Normal Pressure Range - The transmission supply air pressure is within the normal operational range.001b = Low pressure - The transmission suppl...";
CM_ SG_ 2566802174 TrnsmssnAtNtrlMnlRtrnStt "Transmission Auto-Neutral (Manual Return) State: Indicates the transmission response to a Neutral request from SPN 7695 [Transmission Auto-Neutral (Manual Return) Request] or other vehicle input configured for Auto-Neutral (Manual Return) functionali...";
CM_ SG_ 2566802174 TrnsmssnCrrntRngDsplBlnkStt "Transmission Current Range Display Blank State: State signal indicating a transmission request for the display of the Transmission Current Range parameter (SPN 163) to be blanked or not blanked.  The 'Transmission Current Range Display Blank State' i...";
CM_ SG_ 2566802174 TrnsmssnRdFrBrkRls "Transmission Ready for Brake Release: This parameter indicates that enough torque / motive force is available at the transmission output shaft to release all the brakes without a risk of unintentional movement in the opposite direction.00b = Transmis...";
CM_ SG_ 2566802174 TrnsmssnRqstdGrFdk "Transmission Requested Gear Feedback: Feedback of the SPN 525 Transmission Requested Gear input as received from the shift selector, ABS or engine via PGN 256, Transmission Control 1 (TC1) or other transmission selector input.  Scaling, values and pa...";
CM_ SG_ 2566802174 TrnsmssnRqstdRngDsplBlnkStt "Transmission Requested Range Display Blank State: State signal indicating a transmission request for the display of the Transmission Requested Range parameter (SPN162) to be blanked or not blanked.  The 'Transmission Requested Range Display Blank Sta...";
CM_ SG_ 2566802174 TrnsmssnRqstdRngDsplFlshStt "Transmission Requested Range Display Flash State: State signal indicating a transmission request for the display of the Transmission Requested Range parameter (SPN 162) to flash or not to flash. The 'Transmission Requested Range Display Flash State' ...";
CM_ SG_ 2566802174 TrnsmssnRvrsGrShftInhtStts "Transmission Reverse Gear Shift Inhibit Status: Reflects the status of transmission reverse inhibit activity in response to requests via SPN 4242 - Transmission Reverse Gear Shift Inhibit Request.  Typically broadcast by the transmission controller.0...";
CM_ SG_ 2566802174 TrnsmssnShftInhtIndtr "Transmission Shift Inhibit Indicator: State signal indicating a transmission request for the Shift Inhibit Indicator to be active or inactive. The shift inhibit indicator can be of lamp or text form, located on (but not limited to) the shift console,...";
CM_ SG_ 2566802174 TrnsmssnLdRdtnIndtr "Transmission Load Reduction Indicator: This parameter indicates whether or not the transmission has internally disconnected from the driveline in order to reduce transmission parastic drag on the vehicle while it is stopped or nearly stopped. Most of...";
CM_ SG_ 2566802174 TrnsmssnPrDfndRngLmtIndtr "Transmission Pre-Defined Range Limit Indicator: This parameter indicates if the transmission is currently restricted to operation below a pre-defined range as requested by SPN 11751 [Transmission Pre-Defined Maximum Gear Activation Request].00b = Pre...";
CM_ SG_ 2566802174 TransmissionCoastModeIndicator "Transmission Coast Mode Indicator: Parameter indicates whether or not the transmission has internally disconnected from the driveline in order to reduce engine and transmission parastic drag on the vehicle while it is in motion. Most often used to im...";
CM_ SG_ 2566802174 TrnsmssnOtptShftBrkIndtr "Transmission Output Shaft Brake Indicator: This parameter indicates that the transmission is applying either internal or external braking systems for the purpose of stopping output shaft rotation. Such action is typically used to facilitate engagemen...";
CM_ BO_ 2566802430 "Transmission Configuration 2";
CM_ SG_ 2566802430 TransmissionReferenceTorque "Transmission Reference Torque: This parameter is the 100% reference value for all defined transmission output torque parameters.  For a given vehicle application, it is only defined once and doesn't change.";
CM_ SG_ 2566802430 TransmissionTorqueLimit "Transmission Torque Limit: Parameter provided to the engine from the transmission as a torque limit to be invoked by the engine in the event that J1939 communication with the transmission is lost.The intention is to protect transmissions that use a c...";
CM_ SG_ 2566802430 TrnsmssnCmmntnsFlrIdlTrqLmt "Transmission Communications Failure Idle Torque Limit: This parameter is provided to the engine from the transmission as an idle governor torque limit to be invoked by the engine in the event that CAN communication with the transmission is lost.The d...";
CM_ SG_ 2566802430 TransmissionShiftSelectorType "Transmission Shift Selector Type: The Transmission Shift Selector Type signal indicates the type of operator shift selector that is installed on the vehicle. The type of range selection (momentary versus persistent) may be used by the autonomous syst...";
CM_ SG_ 2566802430 TransmissionSpeedLimit "Transmission Speed Limit: Parameter provided to the engine from the transmission as a speed limit to be invoked by the engine in the event that J1939 communication with the transmission is lost. If communication is lost, unrestricted engine speed cou...";
CM_ BO_ 2566802686 "Military Lighting Command";
CM_ SG_ 2566802686 BlackOutBrakeStopLampSelect "Black Out Brake/Stop Lamp Select: Black Out Brake/Stop Lamp Selection00b = Off01b = On10b = Reserved11b = Not Supported";
CM_ SG_ 2566802686 BlackOutWorkLampSelect "Black Out Work Lamp Select: Black Out Work Lamp Selection00b = Off01b = On10b = Reserved11b = Not Supported";
CM_ SG_ 2566802686 ConvoyDrivingLampSelect "Convoy Driving Lamp Select: Black Out Convoy Driving Lamp Selection00b = Off01b = On10b = Reserved11b = Not Supported";
CM_ SG_ 2566802686 ConvoyLampSelect "Convoy Lamp Select: Black Out Convoy Lamp Selection00b = Off01b = On10b = Reserved11b = Not Supported";
CM_ SG_ 2566802686 FrontBlackOutMarkerLampSelect "Front Black Out Marker Lamp Select: Front Black Out Marker Lamp Selection00b = Off01b = On10b = Reserved11b = Not Supported";
CM_ SG_ 2566802686 NightVisionIlluminatorSelect "Night Vision Illuminator Select: Night Vision Illuminator Selection00b = Off01b = On10b = Reserved11b = Not Supported";
CM_ SG_ 2566802686 OprtrsBlkOtIntnstSltn "Operators Black Out Intensity Selection: Operators Selection of lamp intensity in black out mode.  This parameter provides the operators selected illumination intensity as a percentage of available full scale.  This parameter would be typically used ...";
CM_ SG_ 2566802686 RearBlackOutMarkerSelect "Rear Black Out Marker Select: Rear Black Out Marker Selection00b = Off01b = On10b = Reserved11b = Not Supported";
CM_ BO_ 2566803198 "Door Control 1";
CM_ SG_ 2566803198 PositionOfDoors "Position of doors: Signal which indicates the actual position of the doors.0000b = At least 1 door is open0001b = Closing last door0010b = All doors close0011b to 1101b = Not defined1110b = Error1111b = Not available";
CM_ SG_ 2566803198 RampWheelChairLiftPosition "Ramp / Wheel Chair Lift Position: Signal which indicates the actual position of the ramp / wheel chair lift.00b = Inside bus01b = Outside bus10b = Error11b = Not available";
CM_ SG_ 2566803198 Status2OfDoors "Status 2 of doors: Composite indication of all bus door statuses. Enabled means the bus doors are able to be automatically opened or closed.00b = all bus doors are disabled01b = at least 1 bus door enabled 10b = error11b = not available";
CM_ BO_ 2566803454 "Vehicle Dynamic Stability Control 1";
CM_ SG_ 2566803454 RopBrakeControlActive "ROP Brake Control active: State signal which indicates that Roll over Prevention (ROP) has activated brake control. Active means that ROP actually controls wheel brake pressure at one or more wheels of the vehicle or vehicle combination. Within the p...";
CM_ SG_ 2566803454 RopEngineControlActive "ROP Engine Control active: State Signal which indicates that the Roll Over Prevention (ROP) has commanded engine control to be active. Within the physical limits, ROP attempts to prevent rolling over of the vehicle. Active means that ROP actually tri...";
CM_ SG_ 2566803454 TrailerVdcActive "Trailer-VDC Active: The trailer-VDC (Vehicle Dynamic Control) is an electronic vehicle stability function within the (semi) trailer braking system. It acts to stabilize the (semi) trailer during dynamic maneuvers. VDC includes Roll Over Prevention (R...";
CM_ SG_ 2566803454 VdcBrakeLightRequest "VDC brake light request: Indicates whether VDC requests to turn the vehicle brake lights on00b = Turn brake light not on01b = Turn brake light on10b = Reserved11b = Don't care/Take no action";
CM_ SG_ 2566803454 VdcFullyOperational "VDC Fully Operational: Signal that indicates whether VDC is fully operational or whether its functionality is reduced by a permanent or temporary (e.g. low voltage) defect, by intended action (e.g. disabled by a switch or during special diagnostic pr...";
CM_ SG_ 2566803454 VdcInformationSignal "VDC Information Signal: This parameter commands the VDC information signal, for example a dash lamp.00b = Off01b = On10b = Reserved11b = Don't care/Take no action";
CM_ SG_ 2566803454 YcBrakeControlActive "YC Brake Control active: State signal which indicates that Yaw Control (YC) has activated brake control. Active means that YC actually controls wheel brake pressure at one or more wheels of the vehicle or vehicle combination. Within the physical limi...";
CM_ SG_ 2566803454 YcEngineControlActive "YC Engine Control active: State Signal which indicates that the Yaw Control (YC) has commanded engine control to be active. Within the physical limits, YC attempts to prevent yawing of the vehicle. Active means that YC actually tries to control the e...";
CM_ BO_ 2566803710 "Battery Temperature";
CM_ SG_ 2566803710 SliBattery1Temperature "SLI Battery 1 Temperature: Temperature of the battery 1 used for starting the engine, for lighting, and for ignition (SLI). The relation to physical location is determined by the equipment manufacturer.";
CM_ SG_ 2566803710 SliBattery2Temperature "SLI Battery 2 Temperature: Temperature of the second battery or second set of batteries used for starting the engine, for lighting, and for ignition (SLI). The relation to physical location is determined by the equipment manufacturer.";
CM_ SG_ 2566803710 SliBattery3Temperature "SLI Battery 3 Temperature: Temperature of the third battery or third set of batteries used for starting the engine, for lighting, and for ignition (SLI). The relation to physical location is determined by the equipment manufacturer.";
CM_ SG_ 2566803710 SliBattery4Temperature "SLI Battery 4 Temperature: Temperature of the fourth battery or fourth set of batteries used for starting the engine, for lighting, and for ignition (SLI). The relation to physical location is determined by the equipment manufacturer.";
CM_ BO_ 2566803966 "Adaptive Cruise Control, Operator Input";
CM_ SG_ 2566803966 AccUsageDemand "ACC usage demand: This parameter indicates the drivers demand to activate or deactivate ACC keeping distance control.00b = driver demand for not using ACC distance keeping control01b = driver demand for using ACC distance keeping control10b = reserve...";
CM_ SG_ 2566803966 RequestedAccDistanceMode "Requested ACC Distance Mode: The Requested Distance Control Mode to the ACC system from the operators interface.The ACC Set Distance Mode (SPN 1589) indicates the selected Distance Control Mode for the ACC system. This parameter is the driver request...";
CM_ BO_ 2566804222 "Vehicle Electrical Power 3";
CM_ SG_ 2566804222 AltrntrCrrntHghRngRsltn "Alternator Current (High Range/Resolution): This parameter indicates the amount of electrical current output from the alternator of the main vehicle.  Alternator Current (SPN 115) has a lower range and resolution.";
CM_ SG_ 2566804222 SliBattery2NetCurrent "SLI Battery 2 Net Current: Net flow of electrical current into/out of the second battery or second set of batteries used for starting the engine, for lighting, and for ignition (SLI).";
CM_ SG_ 2566804222 SlBttr1NtCrrntHghRngRsltn "SLI Battery 1 Net Current (High Range/Resolution): Net flow of electrical current into/out of the first battery or first set of batteries used for starting the engine, for lighting, and for ignition (SLI).  If more than one battery is included in the...";
CM_ SG_ 2566804222 EcuKeySwitchState "ECU Key Switch State: Indicates the key switch state detected at the input of the electronic control unit supplied through a key switch or similar switching device.00b = Off01b = On10b = Error11b = Not AvailableNote:  See SPN 158 (Key Switch Battery ...";
CM_ BO_ 2566804478 "Retarder Continuous Torque & Speed Limit";
CM_ SG_ 2566804478 LwLmtThrshldFrMxmmRpmFrmRtrdr "Low Limit Threshold for Maximum RPM from Retarder: Minimum allowable value for maximum continuous retarder speed";
CM_ SG_ 2566804478 LwLmtThrshldFrMxmmTrqFrmRtrdr "Low Limit Threshold for Maximum Torque from Retarder: Minimum allowable value for maximum continuous retarder torque.";
CM_ SG_ 2566804478 MaximumContinuousRetarderSpeed "Maximum Continuous Retarder Speed : Applied limit for maximum continuous retarder RPM";
CM_ SG_ 2566804478 MaximumContinuousRetarderTorque "Maximum Continuous Retarder Torque: Applied limit for maximum continuous retarder torque.";
CM_ SG_ 2566804478 MinimumContinuousRetarderSpeed "Minimum Continuous Retarder Speed: Applied limit for minimum continuous retarder RPM";
CM_ SG_ 2566804478 MinimumContinuousRetarderTorque "Minimum Continuous Retarder Torque: Applied limit for minimum continuous retarder torque";
CM_ SG_ 2566804478 HLtTsdFMCtsRpFRtd "High Limit Threshold for Minimum Continuous RPM from Retarder: Maximum allowable value for minimum continuous retarder speed";
CM_ SG_ 2566804478 HLtTsdFMCtsTqFRtd "High Limit Threshold for Minimum Continuous Torque from Retarder: Maximum allowable value for minimum continuous retarder torque.";
CM_ BO_ 2566804734 "Engine Continuous Torque & Speed Limit";
CM_ SG_ 2566804734 EngineMaximumContinuousRpm "Engine Maximum Continuous RPM: Applied limit for maximum continuous engine RPM";
CM_ SG_ 2566804734 EngineMaximumContinuousTorque "Engine Maximum Continuous Torque: Applied limit for maximum continuous engine torque.";
CM_ SG_ 2566804734 EngineMinimumContinuousRpm "Engine Minimum Continuous RPM: Applied limit for minimum continuous engine RPM";
CM_ SG_ 2566804734 EngineMinimumContinuousTorque "Engine Minimum Continuous Torque: Applied limit for minimum continuous engine torque";
CM_ SG_ 2566804734 ELwLtTsdFMxRpFE "Engine Low Limit Threshold for Maximum RPM from Engine: Minimum allowable value for maximum continuous RPM from engine";
CM_ SG_ 2566804734 EHLtTsdFMCtsERp "Engine High Limit Threshold for Minimum Continuous Engine RPM: Maximum allowable value for minimum continuous RPM from engine";
CM_ SG_ 2566804734 ELwLtTsdFMxTqFE "Engine Low Limit Threshold for Maximum Torque from Engine: Minimum allowable value for maximum continuous torque from engine";
CM_ SG_ 2566804734 EHLtTsdFMCtsTqFE "Engine High Limit Threshold for Minimum Continuous Torque from Engine: Maximum allowable value for minimum continuous torque from engine";
CM_ BO_ 2566804990 "Gaseous Fuel Properties";
CM_ SG_ 2566804990 FuelEnergyContent "Fuel energy content: Energy content (lower heating value) of the gaseous fuel.Note:  For gaseous fuels, the fuel's energy content (lower heating value) is commonly defined in terms of energy / volume. The gas volume is defined for regular pressure an...";
CM_ SG_ 2566804990 ReferenceEngineGasMassFlowRate "Reference Engine Gas Mass Flow Rate: Configuration of the mass flow rate of gaseous fuel expected for 100% engine fuel valve control command.Note:  The actuator will request this parameter from the ECU in order to determine what mass fuel flow to ass...";
CM_ SG_ 2566804990 SpecificHeatRatio "Specific Heat Ratio: The specific heat ratio of the fuel.";
CM_ BO_ 2566805246 "Aftertreatment 1 Diesel Exhaust Fluid Tank 1 Information 1";
CM_ SG_ 2566805246 Aftrtrtmnt1DslExhstFldTnkHtr "Aftertreatment 1 Diesel Exhaust Fluid Tank Heater: Percentage of heating applied to the aftertreatment 1 diesel exhaust fluid tank heater.  A value of 0% means no heating applied, a value of 100% means full heating applied.  The diesel exhaust fluid ...";
CM_ SG_ 2566805246 Aftrtrtmnt1DslExhstFldTnkLvl "Aftertreatment 1 Diesel Exhaust Fluid Tank Level: The diesel exhaust fluid level height in mm in the diesel exhaust fluid storage container for aftertreatment system 1 (exhaust bank 1).  See SPN 1761 and SPN 7530 for alternate measurements. Parameter...";
CM_ SG_ 2566805246 Aftrtrtmnt1DslExhstFldTnkVlm "Aftertreatment 1 Diesel Exhaust Fluid Tank Volume: Ratio of volume of diesel exhaust fluid to the total volume of diesel exhaust fluid storage container for aftertreatment system 1 (exhaust bank 1).  0% is empty and 100% is full.  See SPN 3517 and SP...";
CM_ SG_ 2566805246 Atttt1DsExstFdTTpt1 "Aftertreatment 1 Diesel Exhaust Fluid Tank Temperature 1: Temperature of the diesel exhaust fluid in the storage tank.";
CM_ SG_ 2566805246 AttttDsExstFdTLwLvIdt "Aftertreatment Diesel Exhaust Fluid Tank Low Level Indicator: The desired illumination of the driver's warning indicator for diesel exhaust fluid (DEF) tank low level.000b = Off -  indicates adequate DEF level   e.g., for Euro VI this is used to indi...";
CM_ SG_ 2566805246 Atttt1DsExstFdTLvVPF "Aftertreatment 1 Diesel Exhaust Fluid Tank Level/Volume Preliminary FMI: Used to identify the applicable J1939-73 FMI detected in the diesel exhaust fluid tank level sensor by the manufacturer's sensor control software.  This FMI is applicable to eit...";
CM_ SG_ 2566805246 Atttt1DsExstFdT1TptPF "Aftertreatment 1 Diesel Exhaust Fluid Tank 1 Temperature Preliminary FMI: Used to identify the applicable J1939-73 FMI detected for the diesel exhaust fluid tank temperature for aftertreatment system 1 (exhaust bank 1), as detected by the manufacture...";
CM_ SG_ 2566805246 AftrtrtmntSrOprtrIndmntSvrt "Aftertreatment SCR Operator Inducement Severity: Severity status of the operator inducement system for anomalies with the SCR system, such as tampering, low DEF quality, and DEF tank level.  Higher numerical levels indicate more severe levels of indu...";
CM_ SG_ 2566805246 Atttt1DsExstFdT1HtPF "Aftertreatment 1 Diesel Exhaust Fluid Tank 1 Heater Preliminary FMI: Used to identify the applicable J1939-73 FMI detected for the heater of the diesel exhaust fluid tank for aftertreatment system 1 (exhaust bank 1), as detected by the manufacturer's...";
CM_ BO_ 2566805758 "Air Suspension Control 4";
CM_ SG_ 2566805758 BellowPressureFrontAxleLeft "Bellow Pressure Front Axle Left: Information of the pressure of the air suspension bellow at the left side of the front axle";
CM_ SG_ 2566805758 BellowPressureFrontAxleRight "Bellow Pressure Front Axle Right: Information of the pressure of the air suspension bellow at the right side of the front axle";
CM_ SG_ 2566805758 BellowPressureRearAxleLeft "Bellow Pressure Rear Axle Left: Information of the pressure of the air suspension bellow at the left side of the rear axle";
CM_ SG_ 2566805758 BellowPressureRearAxleRight "Bellow Pressure Rear Axle Right: Information of the pressure of the air suspension bellow at the right side of the rear axle";
CM_ BO_ 2566806014 "Air Suspension Control 3";
CM_ SG_ 2566806014 RelativeLevelFrontAxleLeft "Relative Level Front Axle Left: Information of the height at the left side of the front axle referred to normal level 1.  For explanations of normal level 1 see SPN 1734 - Nominal Level Front Axle.";
CM_ SG_ 2566806014 RelativeLevelFrontAxleRight "Relative Level Front Axle Right: Information of the height at the right side of the front axle referred to normal level 1.  For explanations of normal level 1 see SPN 1734 - Nominal Level Front Axle.";
CM_ SG_ 2566806014 RelativeLevelRearAxleLeft "Relative Level Rear Axle Left: Information of the height at the left side of the rear axle referred to normal level 1.  For explanations of normal level 1 see parameter SPN 1734 - Nominal Level Front Axle.";
CM_ SG_ 2566806014 RelativeLevelRearAxleRight "Relative Level Rear Axle Right: Information of the height at the left side of the rear axle referred to normal level 1.  For explanations of normal level 1 see parameter SPN 1734 - Nominal Level Front Axle.";
CM_ BO_ 2566806526 "Forward Lane Image 2";
CM_ SG_ 2566806526 DriverAlertnessLevel "Driver Alertness Level: Indicates the alertness level of the driver measured by the driver alertness warning system. 100 % means driver is fully attentive. This signal can be used independent of the technology and ECU used to estimate the driver aler...";
CM_ SG_ 2566806526 DrvrAlrtnssWrnngSstmStt "Driver Alertness Warning System State: Indicates the various system state in the driver alertness warning system. This signal can be used independent of the technology and ECU used to estimate the driver alertness condition.000b = System installed bu...";
CM_ SG_ 2566806526 ForwardLaneImagerStatus "Forward Lane Imager Status: Indicates the status of the Forward Looking Imager.0000b = Imager fully operational0001b = Imager warming up / initializing0010b = Imager partially blocked / partially blind0011b = Imager fully blocked / fully blind0100b =...";
CM_ SG_ 2566806526 LaneDepartureWarningSystemState "Lane Departure Warning System State: Indicates the status of Lane Departure Warning system.0000b = System is not ready (initialization not finished)0001b = System is temporarily not available (not all activation conditions fulfulled)0010b = System is...";
CM_ SG_ 2566806526 LaneTrackingStatusLeftSide "Lane Tracking Status Left Side: Indicates whether the left side is tracking lane.00b = Not Tracking Left side01b = Tracking Left side10b = Reserved11b = Don't care/Take no action";
CM_ SG_ 2566806526 LaneTrackingStatusRightSide "Lane Tracking Status Right Side: Indicates whether right side is tracking lane.00b = Not Tracking Right side01b = Tracking Right side10b = Reserved11b = Don't Care/take no action";
CM_ SG_ 2566806526 LeftWheelLaneDepartureDistance "Left Wheel Lane Departure Distance: The measured distance of departure of the left wheel on the left side of the lane, as measured from the left edge of the left tire to the right edge of the current lane's left marker.A distance of 0 indicates the l...";
CM_ SG_ 2566806526 LnDprtrIndtnEnlStts "Lane Departure Indication Enable Status: Indicates whether lane departure indication is active.00b = Lane Departure indication disabled01b = Lane Departure Indication enabled 10b = Reserved11b = Not Used";
CM_ SG_ 2566806526 RightWheelLaneDepartureDistance "Right Wheel Lane Departure Distance: The measured distance of departure of the right wheel on the right side of the lane, as measured from the right edge of the right tire to the left edge of the current lane's right marker.A distance of 0 indicates ...";
CM_ BO_ 2566809342 "Battery Main Switch Information";
CM_ SG_ 2566809342 BatteryMainSwitchHoldState "Battery Main Switch Hold State: Parameter indicating whether the battery main switch is held due to an external request or not. The state battery main switch held indicates that the battery main switch is about to switch off.00b = Battery main switch...";
CM_ BO_ 2566809598 "Climate Control Configuration";
CM_ SG_ 2566809598 AxlrHtrMxmmOtptPwr "Auxiliary Heater Maximum Output Power: The maximum output power of the auxiliary heater.";
CM_ BO_ 2566809854 "Vehicle Fluids";
CM_ SG_ 2566809854 HdrlOlFltrRstrtnSwth "Hydraulic Oil Filter Restriction Switch: This switch indicates whether hydraulic oil filter is clogged. This is not the transmission oil filter restriction switch, which is SPN 3359.00b = No restriction01b = Restriction exists on oil filter10b = Erro...";
CM_ SG_ 2566809854 HydraulicOilLevel "Hydraulic Oil Level: This parameter indicates the level of the hydraulic fluid in tank as a ratio of current volume to total tank volume.  This parameter is intended for reporting the hydraulic fluid level in the system tank or reservoir.  This hydra...";
CM_ SG_ 2566809854 HydraulicTemperature "Hydraulic Temperature: Temperature of hydraulic fluid.";
CM_ SG_ 2566809854 WinchOilPressureSwitch "Winch Oil Pressure Switch: State of switch used to determine if Winch Oil Pressure is above desired minimum00b = NOT OK- Oil pressure is too low01b = OK - Oil pressure is above minimum10b = Error - Switch state cannot be determined11b = Not Available...";
CM_ BO_ 2566810110 "Engine Temperature 3";
CM_ SG_ 2566810110 EngnChrgArClr1OtltTmprtr "Engine Charge Air Cooler 1 Outlet Temperature: Temperature of combustion air after it exits from the Charge Air Cooler 1 but before any mixing of recirculated exhaust gas.";
CM_ SG_ 2566810110 EngnClntTmprtrHghRsltn "Engine Coolant Temperature (High Resolution): Temperature of liquid found in engine cooling system. The higher resolution is required for control purposes.";
CM_ SG_ 2566810110 EngnIntkMnfld1TmprtrHghRsltn "Engine Intake Manifold 1 Temperature (High Resolution): Temperature of pre-combustion air found in intake manifold of engine air supply system. The higher resolution is required for control purposes.";
CM_ SG_ 2566810110 EngnIntkVlvAttnSstmOlTmprtr "Engine Intake Valve Actuation System Oil Temperature: The temperature of the oil in the hydraulic system that powers the intake valve actuation system.";
CM_ BO_ 2566810366 "Engine Fuel/Lube Systems";
CM_ SG_ 2566810366 EngineCoolantPreHeatedState "Engine Coolant Pre-heated State: Indicates whether the engine coolant is pre-heated sufficiently for starting purposes.00b = Not sufficiently pre-heated01b = Sufficiently pre-heated10b = Unable to determine  engine coolant pre-heated sufficiently11b ...";
CM_ SG_ 2566810366 EngineOilFilterOutletPressure "Engine Oil Filter Outlet Pressure: Oil pressure (gage) measured just downstream of oil filter.Used in conjunction with SPN1208 (pre-filter oil pressure) to determine oil filter health.";
CM_ SG_ 2566810366 EngineOilLevelRemoteReservoir "Engine Oil Level Remote Reservoir: Ratio of current volume of engine oil in a remote reservoir to the maximum required volume.  If a single switch (on/off) is used, 20% and 100% respectively will be used where 100% means no oil needs to be added and ...";
CM_ SG_ 2566810366 EngineOilPreHeatedState "Engine Oil Pre-Heated State: Indicates whether the engine oil pre-heated sufficiently for starting purposes.00b = Not sufficiently pre-heated01b = Sufficiently pre-heated10b = Unable to determine if engine oil is pre-heated sufficiently11b = Not avai...";
CM_ SG_ 2566810366 EngineOilPrimingPumpSwitch "Engine Oil Priming Pump Switch: Switch input for activating the engine oil priming pump.00b = Off01b = On10b = Error11b = Not available or not installed";
CM_ SG_ 2566810366 EngineOilPrimingState "Engine Oil Priming State: Determination of whether or not the engine is (or has recently been) sufficiently lubricated for starting purposes.00b = Not sufficiently lubricated01b = Sufficiently lubricated10b = Unable to determine if sufficiently lubri...";
CM_ SG_ 2566810366 EngineVentilationStatus "Engine Ventilation Status: Engine ventilation control states.000b = Sufficiently vented (all combustible gases have been evacuated from intake and exhaust systems)001b = Ventilation needed (combustible gases may be present in intake and exhaust syste...";
CM_ SG_ 2566810366 EngineWasteOilReservoirLevel "Engine Waste Oil Reservoir Level: Level of crankcase blowby emulsion collected by a container.  Normalized to percent, 0% represents completely empty and 100% represents completely full.";
CM_ SG_ 2566810366 EngnFlFltrStnSdDffrntlPrssr "Engine Fuel Filter (suction side) Differential Pressure: Differential pressure measured across the fuel filter located between the fuel tank and the supply pump.  See Figures SPN16_A and SPN16_B.See SPN 22745 (Engine Fuel Filter (suction side) Differ...";
CM_ SG_ 2566810366 EngnFlSpplPmpIntkAsltPrssr "Engine Fuel Supply Pump Intake Absolute Pressure: Absolute pressure of fuel at the fuel supply pump intake.  See Figures SPN16_A & SPN16_B.  See SPN 7472 for alternate resolution.";
CM_ SG_ 2566810366 EngnFlSpplPmpIntkPrssr "Engine Fuel Supply Pump Intake Pressure: Gage pressure of fuel at the fuel supply pump intake.  See Figures SPN16_A & SPN16_B.See also SPN 1381.";
CM_ SG_ 2566810366 FuelPumpPrimerStatus "Fuel Pump Primer Status: Parameter used to transmit the actual status of the fuel priming system.  The fuel priming system is a system that purges air in the fuel lines and may assist fuel delivery to a second pump at lower speeds.00b = Off01b = On10...";
CM_ SG_ 2566810366 EngineFuelPrimingState "Engine Fuel Priming State: Determination of whether or not the engine fuel system is (or has recently been) sufficiently primed with fuel for starting purposes.00b = Not sufficiently primed01b = Sufficiently primed10b = Unable to determine if suffici...";
CM_ BO_ 2566811134 "Heater Information";
CM_ SG_ 2566811134 AdrCompliantHeaterInstallation "ADR Compliant Heater Installation: Indicates that the heater is installed in an ADR compliant vehicle.   00b = Heater installation is not ADR compliant01b = Heater installation is ADR compliant10b = Error11b = Not AvailableNote:  ADR is a European ag...";
CM_ SG_ 2566811134 AuxiliaryHeaterMode "Auxiliary Heater Mode: State of the auxiliary heater0000b = Heater not active0001b = Off due to ADR per European Regulations for Transport of hazardous materials0010b = Economy mode0011b = Normal mode0100b = Heater pump up-keep   (running the equipme...";
CM_ SG_ 2566811134 AuxiliaryHeaterWaterPumpStatus "Auxiliary Heater Water Pump Status: Parameter indicating whether the auxiliary heater water pump is running00b = Water Pump is not running01b = Water Pump is  running10b = Reserved11b = Not available";
CM_ SG_ 2566811134 AxlrHtrInptArTmprtr "Auxiliary Heater Input Air Temperature: Temperature of the input air in an auxiliary heater system.";
CM_ SG_ 2566811134 AxlrHtrOtptClntTmprtr "Auxiliary Heater Output Coolant Temperature: Temperature of the auxiliary heater output coolant (I.e. water in a water heater system.)";
CM_ SG_ 2566811134 AxlrHtrOtptPwrPrnt "Auxiliary Heater Output Power Percent: Current auxiliary heater output power, relative to the auxiliary heater maximum output power.";
CM_ SG_ 2566811134 CabHeatingZone "Cab Heating Zone: Parameter indicating whether the cab zone is being heated.00b = Cab heating zone off01b = Cab heating zone on10b = Reserved11b = Not available";
CM_ SG_ 2566811134 CabVentilation "Cab Ventilation: Indicates whether the cab is being ventilated or not.00b = Cab not ventilated01b = Cab is ventilated10b = Reserved11b = Not available";
CM_ SG_ 2566811134 EngineHeatingZone "Engine Heating Zone: Parameter indicating whether the engine zone is being heated.00b = Engine heating zone off01b = Engine heating zone on10b = Reserved11b = Not available";
CM_ BO_ 2566811902 "Combination Vehicle Weight";
CM_ SG_ 2566811902 GrossCombinationVehicleWeight "Gross Combination Vehicle Weight: The total weight of the truck and all attached trailers.";
CM_ SG_ 2566811902 PoweredVehicleWeight "Powered Vehicle Weight: Total mass imposed by the tires of the powered vehicle on the road surface.  Does not include the trailer.";
CM_ SG_ 2566811902 GrssCmntnVhlWghtCnfdn "Gross Combination Vehicle Weight Confidence: Represents the confidence in % of the estimated gross combination vehicle weight (SPN 1760) and shall reflect to what degree the mass estimator function has had the opportunity to evaluate sufficiently man...";
CM_ BO_ 2566819326 "Vehicle Electrical Power 2";
CM_ SG_ 2566819326 BatteryPotentialPowerInput2 "Battery Potential / Power Input 2: This parameter measures the second source of battery potential as measured at the input of the ECU/actuator etc. coming from one or more batteries, irrespective of the distance between the component and the battery....";
CM_ SG_ 2566819326 EcuPowerOutputSupplyVoltage1 "ECU Power Output Supply Voltage #1: The first power output from an ECU.";
CM_ SG_ 2566819326 EcuPowerOutputSupplyVoltage2 "ECU Power Output Supply Voltage #2: The second power output from an ECU.";
CM_ SG_ 2566819326 EcuPowerOutputSupplyVoltage3 "ECU Power Output Supply Voltage #3: The third power output from an ECU.";
CM_ BO_ 2566819838 "Supply Pressure 2";
CM_ SG_ 2566819838 EngnExtrnlShtdwnArSpplPrssr "Engine External Shutdown Air Supply Pressure: Pressure of the air used to shut off the fuel supply to the engine.";
CM_ BO_ 2566820094 "Engine Torque History";
CM_ SG_ 2566820094 CalibrationRecordDurationTime "Calibration Record Duration Time: Duration in hours for which the engine operated in the conditions captured in the current record.";
CM_ SG_ 2566820094 CalibrationRecordStartDay "Calibration Record Start Day: Calendar day timestamp when an ECU record was established.NOTE - A value of 0 for the date is null.  The values 1, 2, 3, and 4 are used to identify the first day of the month; 5, 6, 7, and 8 identify the second day of th...";
CM_ SG_ 2566820094 CalibrationRecordStartMonth "Calibration Record Start Month: Calendar month timestamp when an ECU record was established.NOTE - A value of 0 for the month is null.  The value 1 identifies January; 2 identifies February; etc.";
CM_ SG_ 2566820094 CalibrationRecordStartYear "Calibration Record Start Year: Calendar year timestamp when an ECU record was established.NOTE - A value of 0 for the year identifies the year 1985; a value of 1 identifies 1986; etc.";
CM_ SG_ 2566820094 EnginePeakTorque1 "Engine Peak Torque 1: Maximum torque output of the current ECU calibration when the engine operates on torque curve 1.  For calibrations that support two torque curves, this parameter shall be assigned the value of the lower curve.  For calibrations ...";
CM_ SG_ 2566820094 EnginePeakTorque2 "Engine Peak Torque 2: Maximum torque output of the current ECU calibration when the engine operates on torque curve 2.  For calibrations that support two torque curves, this parameter shall be assigned the value of the higher curve.  For calibrations...";
CM_ SG_ 2566820094 EnginePower "Engine Power: Advertised engine power capability.  Advertised power is what a customer will find on a sales sheet for an engine with a certain calibration.";
CM_ SG_ 2566820094 EngineTorqueLimit1Transmission "Engine Torque Limit 1, Transmission: Limit applied to the engine output torque during vehicle operation in transmission gear ratios numerically greater than transmission gear ratio 1 (see SPN 1255).";
CM_ SG_ 2566820094 EngineTorqueLimit2Transmission "Engine Torque Limit 2, Transmission: Limit applied to the engine output torque during vehicle operation in transmission gear ratios numerically less than or equal to transmission gear ratio 1 (see SPN 1255) and numerically greater than transmission g...";
CM_ SG_ 2566820094 EngineTorqueLimit3Transmission "Engine Torque Limit 3, Transmission: Limit applied to the engine output torque during vehicle operation in transmission gear ratios numerically less than or equal to transmission gear ratio 2 (see SPN 1257) and numerically greater than transmission g...";
CM_ SG_ 2566820094 EngineTorqueLimit4Transmission "Engine Torque Limit 4, Transmission: Limit applied to the engine output torque during vehicle operation in transmission gear ratios numerically less than or equal to transmission gear ratio 3 (see SPN 1259).";
CM_ SG_ 2566820094 EngineTorqueLimit5Switch "Engine Torque Limit 5, Switch: Limit applied to the engine output torque based on activation of an ECU switch input.";
CM_ SG_ 2566820094 EngineTorqueLimit6AxleInput "Engine Torque Limit 6, Axle Input: Limit applied to the engine output torque based on the maximum allowable axle input torque.  Axle input torque is calculated as the current engine torque output multiplied by the transmission gear ratio.";
CM_ SG_ 2566820094 EngineTorqueLimitFeature "Engine Torque Limit Feature: Torque limit rating described in the current record. 000b = Reserved001b = Highest torque rating010b = First torque rating011b = Previous torque rating (rating prior to the current rating)100b = Current torque rating101b ...";
CM_ SG_ 2566820094 TorqueLimitingFeatureStatus "Torque Limiting Feature Status: Status of an ECU feature which limits the torque output of the engine. 00b = Disabled01b = Enabled10b = Error11b = Not available";
CM_ SG_ 2566820094 TransmissionGearRatio1 "Transmission Gear Ratio 1: Gear ratio value stored in the ECU that is used to define a range of transmission gears for which a limit is applied to the engine output torque.  Transmission gear ratio 1 should be the numerically highest transmission gea...";
CM_ SG_ 2566820094 TransmissionGearRatio2 "Transmission Gear Ratio 2: Gear ratio value stored in the ECU that is used to define a range of transmission gears for which a limit is applied to the engine output torque.  Transmission gear ratio 2 should be the numerically highest transmission gea...";
CM_ SG_ 2566820094 TransmissionGearRatio3 "Transmission Gear Ratio 3: Gear ratio value stored in the ECU that is used to define a range of transmission gears for which a limit is applied to the engine output torque.  Transmission gear ratio 3 should be the numerically highest transmission gea...";
CM_ SG_ 2566820094 NmrOfEngnTrqHstrRrds "Number of Engine Torque History Records: Number of torque history records contained in the engine torque history PG.  A value of 0 is broadcast if no torque history records are stored in the ECU.";
CM_ BO_ 2566821118 "Engine Auxiliary Coolant";
CM_ SG_ 2566821118 EngineAuxiliaryCoolantPressure "Engine Auxiliary Coolant Pressure: Gage pressure of coolant found in the intercooler which is located after the turbocharger.";
CM_ SG_ 2566821118 EngnAxlrClntTmprtr "Engine Auxiliary Coolant Temperature: Temperature of coolant found in the intercooler which is located after the turbocharger.";
CM_ SG_ 2566821118 EngnClntPmpClntOtltPrssr "Engine Coolant Pump Coolant Outlet Pressure: Engine coolant pressure at the coolant pump outlet.";
CM_ SG_ 2566821118 EngnClntPrssr1ExtnddRng "Engine Coolant Pressure 1 (Extended Range): Gage pressure of liquid found in engine cooling system.See also SPN 109 for alternate range and resolution.";
CM_ SG_ 2566821118 EngnClntPrssr2ExtnddRng "Engine Coolant Pressure 2 (Extended Range): Gage pressure of liquid found in engine coolant system - second instance.See also SPN 5708 for alternate range and resolution.";
CM_ SG_ 2566821118 SeaWaterPumpOutletPressure "Sea Water Pump Outlet Pressure: Gauge pressure of liquid found at outlet of sea water pump in sea water cooling system.";
CM_ SG_ 2566821118 SeaWaterPumpOutletPressure2 "Sea Water Pump Outlet Pressure 2: Gage pressure of liquid found at outlet of sea water pump in sea water cooling system - second instance.";
CM_ SG_ 2566821118 EngnAftrlrClntOtltPrssr "Engine Aftercooler Coolant Outlet Pressure: The gage pressure of the engine coolant located at the aftercooler outlet.";
CM_ BO_ 2566821630 "Turbocharger Wastegate";
CM_ SG_ 2566821630 EngnTrhrgrWstgtAttr1DsrdPstn "Engine Turbocharger Wastegate Actuator 1 Desired Position: The Requested Valve position of the Turbocharger Wastegate Valve 1, commanded by the engine ECU. A value of 0% represents fully closed and a value of 100% represents fully open.This is the po...";
CM_ SG_ 2566821630 EngnTrhrgrWstgtAttr1Pstn "Engine Turbocharger Wastegate Actuator 1 Position: Position of the wastegate drive.  A value of 0% represents fully closed and a value of 100% represents fully open.";
CM_ SG_ 2566821630 EngnTrhrgrWstgtAttr1TmprtrStts "Engine Turbocharger Wastegate Actuator 1 Temperature Status: Used to identify the status of the Engine Turbocharger Wastegate Actuator 1 drive circuitry temperature.  Temperature excursions may affect the torque output.000b = High Most severe001b = H...";
CM_ SG_ 2566821630 EngnTrhrgrWstgtAttr2DsrdPstn "Engine Turbocharger Wastegate Actuator 2 Desired Position: The Requested Valve position of the Turbocharger Wastegate Valve 2, commanded by the engine ECU. A value of 0% represents fully closed and a value of 100% represents fully open.This is the po...";
CM_ SG_ 2566821630 EngnTrhrgrWstgtAttr2Pstn "Engine Turbocharger Wastegate Actuator 2 Position: Position of the wastegate drive.  A value of 0% represents fully closed and a value of 100% represents fully open.";
CM_ SG_ 2566821630 EngnTrhrgrWstgtAttr3Pstn "Engine Turbocharger Wastegate Actuator 3 Position: Position of the wastegate drive.  A value of 0% represents fully closed and a value of 100% represents fully open.";
CM_ SG_ 2566821630 EngnTrhrgrWstgtAttr4Pstn "Engine Turbocharger Wastegate Actuator 4 Position: Position of the wastegate drive.  A value of 0% represents fully closed and a value of 100% represents fully open.";
CM_ SG_ 2566821630 EngnTrhrgrWstgtAttrCntrlArPrssr "Engine Turbocharger Wastegate Actuator Control Air Pressure: Gage pressure of the air used to control the actuator which opens and closes the wastegate valve.";
CM_ SG_ 2566821630 EngnTrhrgrWstgtAttr1PrlmnrFm "Engine Turbocharger Wastegate Actuator 1 Preliminary FMI: Used to identify the applicable J1939-73 FMI detected in the Engine Turbocharger Wastegate Actuator 1 by the manufacturers software.  When there is multiple failures, the most severe is transm...";
CM_ BO_ 2566821886 "Turbocharger Information 5";
CM_ SG_ 2566821886 EngnTrhrgr1TrnOtltTmprtr "Engine Turbocharger 1 Turbine Outlet Temperature: Temperature of the combustion by-products exiting the turbine side of the turbocharger.";
CM_ SG_ 2566821886 EngnTrhrgr2TrnOtltTmprtr "Engine Turbocharger 2 Turbine Outlet Temperature: Temperature of the combustion by-products exiting the turbine side of the turbocharger.";
CM_ SG_ 2566821886 EngnTrhrgr3TrnOtltTmprtr "Engine Turbocharger 3 Turbine Outlet Temperature: Temperature of the combustion by-products exiting the turbine side of the turbocharger.";
CM_ SG_ 2566821886 EngnTrhrgr4TrnOtltTmprtr "Engine Turbocharger 4 Turbine Outlet Temperature: Temperature of the combustion by-products exiting the turbine side of the turbocharger.";
CM_ BO_ 2566822142 "Turbocharger Information 4";
CM_ SG_ 2566822142 EngnTrhrgr1TrnIntkTmprtr "Engine Turbocharger 1 Turbine Intake Temperature: Temperature of the combustion by-products entering the turbine side of the turbocharger.";
CM_ SG_ 2566822142 EngnTrhrgr2TrnIntkTmprtr "Engine Turbocharger 2 Turbine Intake Temperature: Temperature of the combustion by-products entering the turbine side of the turbocharger.";
CM_ SG_ 2566822142 EngnTrhrgr3TrnIntkTmprtr "Engine Turbocharger 3 Turbine Intake Temperature: Temperature of the combustion by-products entering the turbine side of the turbocharger.";
CM_ SG_ 2566822142 EngnTrhrgr4TrnIntkTmprtr "Engine Turbocharger 4 Turbine Intake Temperature: Temperature of the combustion by-products entering the turbine side of the turbocharger.";
CM_ BO_ 2566822398 "Turbocharger Information 3";
CM_ SG_ 2566822398 EngnTrhrgr1CmprssrIntkPrssr "Engine Turbocharger 1 Compressor Intake Pressure: Gage pressure of the air entering the compressor side of the turbocharger.";
CM_ SG_ 2566822398 EngnTrhrgr2CmprssrIntkPrssr "Engine Turbocharger 2 Compressor Intake Pressure: Gage pressure of the air entering the compressor side of the turbocharger.";
CM_ SG_ 2566822398 EngnTrhrgr3CmprssrIntkPrssr "Engine Turbocharger 3 Compressor Intake Pressure: Gage pressure of the air entering the compressor side of the turbocharger.";
CM_ SG_ 2566822398 EngnTrhrgr4CmprssrIntkPrssr "Engine Turbocharger 4 Compressor Intake Pressure: Gage pressure of the air entering the compressor side of the turbocharger.";
CM_ BO_ 2566822654 "Turbocharger Information 2";
CM_ SG_ 2566822654 EngnTrhrgr1CmprssrIntkTmprtr "Engine Turbocharger 1 Compressor Intake Temperature: Temperature of the air entering the compressor side of the turbocharger.";
CM_ SG_ 2566822654 EngnTrhrgr2CmprssrIntkTmprtr "Engine Turbocharger 2 Compressor Intake Temperature: Temperature of the air entering the compressor side of the turbocharger.";
CM_ SG_ 2566822654 EngnTrhrgr3CmprssrIntkTmprtr "Engine Turbocharger 3 Compressor Intake Temperature: Temperature of the air entering the compressor side of the turbocharger.";
CM_ SG_ 2566822654 EngnTrhrgr4CmprssrIntkTmprtr "Engine Turbocharger 4 Compressor Intake Temperature: Temperature of the air entering the compressor side of the turbocharger.";
CM_ BO_ 2566823166 "Main Bearing Temperature 3";
CM_ SG_ 2566823166 EngineMainBearing10Temperature "Engine Main Bearing 10 Temperature: Temperature of the main bearing which supports the crankshaft of the engine.";
CM_ SG_ 2566823166 EngineMainBearing11Temperature "Engine Main Bearing 11 Temperature: Temperature of the main bearing which supports the crankshaft of the engine.";
CM_ SG_ 2566823166 EngineMainBearing12Temperature "Engine Main Bearing 12 Temperature: Temperature of the main bearing which supports the crankshaft of the engine.";
CM_ SG_ 2566823166 EngineMainBearing9Temperature "Engine Main Bearing 9 Temperature: Temperature of the main bearing which supports the crankshaft of the engine.";
CM_ BO_ 2566823422 "Main Bearing Temperature 2";
CM_ SG_ 2566823422 EngineMainBearing5Temperature "Engine Main Bearing 5 Temperature: Temperature of the main bearing which supports the crankshaft of the engine.";
CM_ SG_ 2566823422 EngineMainBearing6Temperature "Engine Main Bearing 6 Temperature: Temperature of the main bearing which supports the crankshaft of the engine.";
CM_ SG_ 2566823422 EngineMainBearing7Temperature "Engine Main Bearing 7 Temperature: Temperature of the main bearing which supports the crankshaft of the engine.";
CM_ SG_ 2566823422 EngineMainBearing8Temperature "Engine Main Bearing 8 Temperature: Temperature of the main bearing which supports the crankshaft of the engine.";
CM_ BO_ 2566823678 "Main Bearing Temperature 1";
CM_ SG_ 2566823678 EngineMainBearing1Temperature "Engine Main Bearing 1 Temperature: Temperature of the main bearing which supports the crankshaft of the engine.";
CM_ SG_ 2566823678 EngineMainBearing2Temperature "Engine Main Bearing 2 Temperature: Temperature of the main bearing which supports the crankshaft of the engine.";
CM_ SG_ 2566823678 EngineMainBearing3Temperature "Engine Main Bearing 3 Temperature: Temperature of the main bearing which supports the crankshaft of the engine.";
CM_ SG_ 2566823678 EngineMainBearing4Temperature "Engine Main Bearing 4 Temperature: Temperature of the main bearing which supports the crankshaft of the engine.";
CM_ BO_ 2566824190 "Exhaust Port Temperature 4";
CM_ SG_ 2566824190 EngnExhstGsPrt13Tmprtr "Engine Exhaust Gas Port 13 Temperature: Temperature at the cylinder exhaust port of the engine.";
CM_ SG_ 2566824190 EngnExhstGsPrt14Tmprtr "Engine Exhaust Gas Port 14 Temperature: Temperature at the cylinder exhaust port of the engine.";
CM_ SG_ 2566824190 EngnExhstGsPrt15Tmprtr "Engine Exhaust Gas Port 15 Temperature: Temperature at the cylinder exhaust port of the engine.";
CM_ SG_ 2566824190 EngnExhstGsPrt16Tmprtr "Engine Exhaust Gas Port 16 Temperature: Temperature at the cylinder exhaust port of the engine.";
CM_ BO_ 2566825214 "Engine Temperature 2";
CM_ SG_ 2566825214 EngineEcuTemperature "Engine ECU Temperature: Temperature of the engine electronic control unit.";
CM_ SG_ 2566825214 EngineOilTemperature2 "Engine Oil Temperature 2: Temperature of the engine lubricant.Note:  If there is only one engine oil temperature measurement, SPN 175 should be used. See also SPNs 175 and 5925 for additional engine oil temperature measurements.";
CM_ SG_ 2566825214 EngnExhstGsRrltn1DffrntlPrssr "Engine Exhaust Gas Recirculation 1 Differential Pressure: Differential pressure across the Exhaust Gas Recirculation (EGR) system";
CM_ SG_ 2566825214 EngnExhstGsRrltn1Tmprtr "Engine Exhaust Gas Recirculation 1 Temperature: Temperature of Recirculated Exhaust Gas.  This should not be used for Exhaust Gas Recirculation Mixer Intake Temperature.  See SPN 5020.";
CM_ BO_ 2566825726 "Intake Manifold Information 1";
CM_ SG_ 2566825726 EngnTrhrgr1BstPrssr "Engine Turbocharger 1 Boost Pressure: Gage pressure of air measured downstream of the compressor discharge side of the turbocharger.  See also SPN 102 for alternate range and resolution. If there is only one boost pressure to report and the range and...";
CM_ SG_ 2566825726 EngnTrhrgr2BstPrssr "Engine Turbocharger 2 Boost Pressure: Gage pressure of air measured downstream of the compressor discharge side of the turbocharger.  See also SPN 102 for alternate range and resolution. If there is only one boost pressure to report and the range and...";
CM_ SG_ 2566825726 EngnTrhrgr3BstPrssr "Engine Turbocharger 3 Boost Pressure: Gage pressure of air measured downstream of the compressor discharge side of the turbocharger.  See also SPN 102 for alternate range and resolution. If there is only one boost pressure to report and the range and...";
CM_ SG_ 2566825726 EngnTrhrgr4BstPrssr "Engine Turbocharger 4 Boost Pressure: Gage pressure of air measured downstream of the compressor discharge side of the turbocharger.  See also SPN 102 for alternate range and resolution. If there is only one boost pressure to report and the range and...";
CM_ BO_ 2566827518 "Wheel Application Pressure High Range Information";
CM_ SG_ 2566827518 BApptPssHRFtAxLtW "Brake Application Pressure High Range, Front Axle, Left Wheel: The brake application pressure for the left wheel on the front axle.";
CM_ SG_ 2566827518 BApptPssHRFtAxRtW "Brake Application Pressure High Range, Front Axle, Right Wheel: The brake application pressure for the right wheel on the front axle.";
CM_ SG_ 2566827518 BApptPssHRRAx1LtW "Brake Application Pressure High Range, Rear Axle #1, Left Wheel: The brake application pressure for the left wheel on the rear axle #1.";
CM_ SG_ 2566827518 BApptPssHRRAx1RtW "Brake Application Pressure High Range, Rear Axle #1, Right Wheel: The brake application pressure for the right wheel on the rear axle #1.";
CM_ SG_ 2566827518 BApptPssHRRAx2LtW "Brake Application Pressure High Range, Rear Axle #2, Left Wheel: The brake application pressure for the left wheel on the rear axle #2.";
CM_ SG_ 2566827518 BApptPssHRRAx2RtW "Brake Application Pressure High Range, Rear Axle #2, Right Wheel: The brake application pressure for the right wheel on the rear axle #2.";
CM_ SG_ 2566827518 BApptPssHRRAx3LtW "Brake Application Pressure High Range, Rear Axle #3, Left Wheel: The brake application pressure for the left wheel on the rear axle #3.";
CM_ SG_ 2566827518 BApptPssHRRAx3RtW "Brake Application Pressure High Range, Rear Axle #3, Right Wheel: The brake application pressure for the right wheel on the rear axle #3.";
CM_ BO_ 2566827774 "Air Supply Pressure";
CM_ SG_ 2566827774 AirCompressorStatus "Air Compressor Status: Indicates whether the air compressor is actively compressing air.  00b = Compressor not active01b = Compressor active10b = Error indicator11b = Not available";
CM_ SG_ 2566827774 AxlrEqpmntSpplPrssr "Auxiliary Equipment Supply Pressure: The pneumatic pressure in the auxiliary circuit.";
CM_ SG_ 2566827774 ParkingAndOrTrailerAirPressure "Parking and/or Trailer Air Pressure: The pneumatic pressure in the circuit or reservoir for the parking brake and/or the trailer supply.";
CM_ SG_ 2566827774 PneumaticSupplyPressure "Pneumatic Supply Pressure: The pneumatic pressure in the main reservoir, sometimes referred to as the wet tank.";
CM_ SG_ 2566827774 PwrtrnCrtArSpplPrssr "Powertrain Circuit Air Supply Pressure: Supply pressure to carry the pressure information for the powertrain circuit. This circuit typically would feed powertrain components such as throttles, gearbox actuators and aftertreatment actuators for EGR an...";
CM_ SG_ 2566827774 ServiceBrakeCircuit1AirPressure "Service Brake Circuit 1 Air Pressure: The pneumatic pressure in the primary service brake circuit or reservoir, supplying the rear axle.";
CM_ SG_ 2566827774 ServiceBrakeCircuit2AirPressure "Service Brake Circuit 2 Air Pressure: The pneumatic pressure in the secondary service brake circuit or reservoir, supplying the front axle.";
CM_ SG_ 2566827774 AirSuspensionSupplyPressure1 "Air Suspension Supply Pressure 1: The pneumatic pressure in the first circuit for the electronically controlled air suspension system.";
CM_ BO_ 2566831614 "Fan Drive #1";
CM_ SG_ 2566831614 EngineFan1EstimatedPercentSpeed "Engine Fan 1 Estimated Percent Speed: Estimated fan speed as a ratio of the fan drive (current speed) to the fully engaged fan drive (maximum fan speed).  A two state fan (off/on) will use 0% and 100% respectively.  A three state fan (off/intermediat...";
CM_ SG_ 2566831614 FanDriveBypassCommandStatus "Fan Drive Bypass Command Status: Status of the Fan Drive Bypass Command as being commanded by the ECU.  The fan drive bypass diverts pump pressure away from the hydraulic motor to maintain the fan drive pressure.  0% is defined as no bypass (i.e. div...";
CM_ SG_ 2566831614 FanDriveState "Fan Drive State: This parameter is used to indicate the current state or mode of operation by the fan drive.0000b = Fan off0001b = Engine system-General0010b = Excessive engine air temperature0011b = Excessive engine oil temperature0100b = Excessive ...";
CM_ SG_ 2566831614 FanSpeed "Fan Speed: The speed of the fan associated with engine coolant system.";
CM_ SG_ 2566831614 HydraulicFanMotorPressure "Hydraulic Fan Motor Pressure: The hydraulic pressure used to drive the fan system, sensed before the hydraulic fan motor.";
CM_ SG_ 2566831614 EngineFanReverseSwitch "Engine Fan Reverse Switch: Switch signal used to drive the engine fan in the reverse direction. Off indicates the fan is commanded in the normal direction.00b = Off01b = On10b = Error11b = Not available";
CM_ SG_ 2566831614 EngineFanBypassSwitch "Engine Fan Bypass Switch: Switch signal used to activate the engine fan bypass. On indicates the fan bypass is commanded active.00b = Off01b = On10b = Error11b = Not available";
CM_ BO_ 2566832126 "Wheel Speed Information";
CM_ SG_ 2566832126 FrontAxleSpeed "Front Axle Speed: The average speed of the two front wheels.";
CM_ SG_ 2566832126 RelativeSpeedFrontAxleLeftWheel "Relative Speed; Front Axle, Left Wheel: The speed of the front axle, left wheel relative to the front axle speed, SPN 904.";
CM_ SG_ 2566832126 RltvSpdFrntAxlRghtWhl "Relative Speed; Front Axle, Right Wheel: The speed of the front axle, right wheel relative to the front axle speed, SPN 904.";
CM_ SG_ 2566832126 RelativeSpeedRearAxle1LeftWheel "Relative Speed; Rear Axle #1, Left Wheel: The speed of the rear axle #1, left wheel relative to the front axle speed, SPN 904.";
CM_ SG_ 2566832126 RltvSpdRrAxl1RghtWhl "Relative Speed; Rear Axle #1, Right Wheel: The speed of the rear axle #1, right wheel relative to the front axle speed, SPN 904.";
CM_ SG_ 2566832126 RelativeSpeedRearAxle2LeftWheel "Relative Speed; Rear Axle #2, Left Wheel: The speed of the rear axle #2, left wheel relative to the front axle speed, SPN 904.";
CM_ SG_ 2566832126 RltvSpdRrAxl2RghtWhl "Relative Speed; Rear Axle #2, Right Wheel: The speed of the rear axle #2, right wheel relative to the front axle speed, SPN 904.";
CM_ BO_ 2566832382 "Service Information";
CM_ SG_ 2566832382 ServiceDelayCalendarTimeBased "Service Delay/Calendar Time Based: The time in weeks until the next vehicle service inspection is required.  A negative value is transmitted if the service inspection has been passed.  The component that requires service is identified by the service ...";
CM_ SG_ 2566832382 ServiceDistance "Service Distance: The distance which can be traveled by the vehicle before the next service inspection is required.  A negative distance is transmitted if the service inspection has been passed.  The component that requires service is identified by t...";
CM_ SG_ 2566832382 SrvDlOprtnlTmBsd "Service Delay/Operational Time Based: The time in vehicle operational time until the next vehicle service inspection is required.  A negative value is transmitted if the service inspection has been passed.  The component that requires service is iden...";
CM_ SG_ 2566832382 ServiceComponentIdentificationA "Service Component Identification: Identification of component needing service.  See Table SPN911_A.";
CM_ SG_ 2566832382 ServiceComponentIdentificationB "Service Component Identification: Identification of component needing service.  See Table SPN911_A.";
CM_ SG_ 2566832382 ServiceComponentIdentificationC "Service Component Identification: Identification of component needing service.  See Table SPN911_A.";
CM_ BO_ 2566832638 "High Resolution Vehicle Distance";
CM_ SG_ 2566832638 TripDistanceHighResolution "Trip Distance (High Resolution): Distance traveled during all or part of a journey.NOTE - See SPN 244 for alternate resolution.";
CM_ SG_ 2566832638 TtlVhlDstnHghRsltn "Total Vehicle Distance (High Resolution): Accumulated distance traveled by the vehicle during its operation.NOTE - See SPN 245 for alternate resolution.";
CM_ BO_ 2566837758 "Alternator Information 1";
CM_ SG_ 2566837758 Alternator1Status "Alternator 1 Status: Alternator 1 operating status.00b = Alternator 1 not charging01b = Alternator 1 charging10b = error11b = not available";
CM_ SG_ 2566837758 Alternator2Status "Alternator 2 Status: Alternator 2 operating status.00b = Alternator 2 not charging01b = Alternator 2 charging10b = error11b = not available";
CM_ SG_ 2566837758 Alternator3Status "Alternator 3 Status: Alternator 3 operating status.00b = Alternator 3 not charging01b = Alternator 3 charging10b = error11b = not available";
CM_ SG_ 2566837758 Alternator4Status "Alternator 4 Status: Alternator 4 operating status.00b = Alternator 4 not charging01b = Alternator 4 charging10b = error11b = not available";
CM_ SG_ 2566837758 AlternatorSpeed "Alternator Speed: Actual rotation speed of the alternator.";
CM_ SG_ 2566837758 AltrntrEltrlFlrStts "Alternator Electrical Failure Status: The electrical failure status of the alternator.00b - No electrical failure01b - Electrical failure10b - Error11b - Not available";
CM_ SG_ 2566837758 AltrntrMhnlFlrStts "Alternator Mechanical Failure Status: The mechanical failure status of the alternator.00b - No mechanical failure01b - Mechanical failure10b - Error11b - Not available";
CM_ SG_ 2566837758 AltrntrHghTmprtrWrnngStts "Alternator High Temperature Warning Status: The high temperature warning status of the alternator.00b - No high temperature warning01b - High temperature warning10b - Error11b - Not available";
CM_ SG_ 2566837758 AlternatorLinTimeoutDetected "Alternator LIN Timeout Detected: The LIN timeout detection status of the alternator.00b - No LIN timeout detected01b - LIN timeout detected10b - Error11b - Not available";
CM_ SG_ 2566837758 AltrntrLnCmmntnFlrStts "Alternator LIN Communication Failure Status: The LIN communication failure status of the alternator.00b - No LIN communication failure01b - LIN communication failure10b - Error11b - Not available";
CM_ SG_ 2566837758 AlternatorLoadBalancingStatus "Alternator Load Balancing Status: The load balancing status of the alternator.00b - Normal operation, balanced load01b - Load balancing error10b - Error11b - Not available";
CM_ SG_ 2566837758 AlternatorExcitationStatus "Alternator Excitation Status: The excitation status of the alternator.00b - Normal operation, alternator enabled01b - De-excited, alternator inhibited10b - Error11b - Not available";
CM_ BO_ 2566838014 "Hybrid or EV System Inputs 1";
CM_ SG_ 2566838014 PrplsnMtrClntFllSwth "Propulsion Motor Coolant Fill Switch: Indicates the coolant fill switch position for the propulsion motor cooling system.  This switch is used to enable the pump for filling the cooling system.  When the switch is in the On state, the pump is to be r...";
CM_ SG_ 2566838014 PwrEltrnsClntFllSwth "Power Electronics Coolant Fill Switch: Indicates the coolant fill switch position for the power electronics cooling system.  This switch is used to enable the pump for filling the cooling system.  When the switch is in the On state, the pump is to be...";
CM_ SG_ 2566838014 HvssThrmlMngmntMntnnSwth "HVESS Thermal Management Maintenance Switch: Indicates the HVESS Thermal Management Maintenance Switch position. This switch is used to request the Hybrid or Electric Vehicle System Controller to maintain HVESS thermal management for maintenance purp...";
CM_ SG_ 2566838014 HrdOrEvSstmPrttnOvrrdSwth "Hybrid or EV System Protection Override Switch: Indicates the Protection Override switch position.  This switch allows the operator to override hybrid or EV system protection features and failure modes allowing hybrid or EV system to continue to oper...";
CM_ SG_ 2566838014 HrdOrEvSstmPrplsnClntLvlSwth "Hybrid or EV System Propulsion Coolant Level Switch: Indicates the coolant level switch position in the hybrid or EV system propulsion (e.g. electric motor, generator) cooling system.00b = Coolant Level is not sufficient01b = Coolant Level is suffici...";
CM_ SG_ 2566838014 HrdOrEvSstmPwrEltrnsClntLvlSwth "Hybrid or EV System Power Electronics Coolant Level Switch: Indicates the coolant level switch position in the hybrid or EV system power electronics (e.g. Inverters, DC/DC converters) cooling system.00b = Coolant Level is not sufficient01b = Coolant ...";
CM_ SG_ 2566838014 HrdOrEvSstmOffBrdChrgrCnntnStts "Hybrid or EV System Off-Board Charger Connection Status: Indicates the off-board plug-in charger connection status.  One of the uses of this signal is to protect against vehicle motion while a charger is plugged in.00b = Off-board charger is not conn...";
CM_ SG_ 2566838014 HrdOrEvSstmRgnrtvBrkngDslSwth "Hybrid or EV System Regenerative Braking Disable Switch: Indicates the regenerative braking disable switch position.  This switch gives the operator the ability to disable all regenerative braking from all inputs (e.g. such as during slippery road co...";
CM_ SG_ 2566838014 HdOEvSstBPdRtvBDsSwt "Hybrid or EV System Brake Pedal Regenerative Braking Disable Switch: Indicates the brake pedal regenerative braking disable switch position.  This switch allows the operator to disable regenerative braking (e.g. such as during slippery road condition...";
CM_ SG_ 2566838014 HrdOrEvSstmPrplsnDslSwth "Hybrid or EV System Propulsion Disable Switch: When the operator enables this switch, the propulsion aspect of hybrid or EV system operation will be disabled.  However, hybrid or EV powered accessories may be on and the engine may still run in hybrid...";
CM_ SG_ 2566838014 HybridOrEvSystemShutdownSwitch "Hybrid or EV System Shutdown Switch: When the operator enables this switch, all hybrid or EV system functionality is disabled including propulsion, regenerative braking, and hybrid or EV powered accessories.  The hybrid or EV system shall be placed i...";
CM_ SG_ 2566838014 HdOEvSstCstRtvBLvSt "Hybrid or EV System Coasting Regenerative Braking Level Selector: Indicates the coasting regenerative braking level selector position.  Coasting regenerative braking occurs when neither the accelerator nor the brake pedal are depressed.The coasting r...";
CM_ SG_ 2566838014 Hsi1EmbeddedIntegritySupport "HSI1 Embedded Integrity Support: Indicates SPN 22273 (HSI1 CRC) and SPN 22271 (HSI1 Counter) are supported by the sender.00b = HSI1 embedded CRC and Counter are supported by the sender01b = HSI1 protection is provided using an external (not in this P...";
CM_ SG_ 2566838014 Hsi1Counter "HSI1 Counter: The message counter is used to detect situations where the transmitting ECU malfunction repeats the same frame all the time. The receiver of the information may use the counter parameter to detect this situation. The transmitting device...";
CM_ SG_ 2566838014 Hsi1Crc "HSI1 CRC: The CRC is defined as follows:- Length: 8 bits- Polynomial: x^8+x^5+x^3+x^2+x+1- Initial Value: FFh- Input Data Reflection: Not reflected- Result Data Reflection: Not reflected- XOR value: FFhSAE makes no claim of the functional safety leve...";
CM_ SG_ 2566838014 HrdOrEvOprtrStppngMdRqst "Hybrid or EV Operator Stopping Mode Request: A configuration input from the vehicle operator which requests how the released state of the operator's accelerator pedal input is to be interpreted in hybrid or EV applications.  A given hybrid or EV syst...";
CM_ BO_ 2566838782 "Auxiliary Input/Output Status 1";
CM_ SG_ 2566838782 AuxiliaryIO01 "Auxiliary I/O #01: Identifies the current status of auxiliary input/output functions that are configured uniquely per application.00b = Auxiliary channel off01b = Auxiliary channel on10b = Error11b = Not available";
CM_ SG_ 2566838782 AuxiliaryIO02 "Auxiliary I/O #02: Identifies the current status of auxiliary input/output functions that are configured uniquely per application.00b = Auxiliary channel off01b = Auxiliary channel on10b = Error11b = Not available";
CM_ SG_ 2566838782 AuxiliaryIO03 "Auxiliary I/O #03: Identifies the current status of auxiliary input/output functions that are configured uniquely per application.00b = Auxiliary channel off01b = Auxiliary channel on10b = Error11b = Not available";
CM_ SG_ 2566838782 AuxiliaryIO04 "Auxiliary I/O #04: Identifies the current status of auxiliary input/output functions that are configured uniquely per application.00b = Auxiliary channel off01b = Auxiliary channel on10b = Error11b = Not available";
CM_ SG_ 2566838782 AuxiliaryIO05 "Auxiliary I/O #05: Identifies the current status of auxiliary input/output functions that are configured uniquely per application.00b = Auxiliary channel off01b = Auxiliary channel on10b = Error11b = Not available";
CM_ SG_ 2566838782 AuxiliaryIO06 "Auxiliary I/O #06: Identifies the current status of auxiliary input/output functions that are configured uniquely per application.00b = Auxiliary channel off01b = Auxiliary channel on10b = Error11b = Not available";
CM_ SG_ 2566838782 AuxiliaryIO07 "Auxiliary I/O #07: Identifies the current status of auxiliary input/output functions that are configured uniquely per application.00b = Auxiliary channel off01b = Auxiliary channel on10b = Error11b = Not available";
CM_ SG_ 2566838782 AuxiliaryIO08 "Auxiliary I/O #08: Identifies the current status of auxiliary input/output functions that are configured uniquely per application.00b = Auxiliary channel off01b = Auxiliary channel on10b = Error11b = Not available";
CM_ SG_ 2566838782 AuxiliaryIO09 "Auxiliary I/O #09: Identifies the current status of auxiliary input/output functions that are configured uniquely per application.00b = Auxiliary channel off01b = Auxiliary channel on10b = Error11b = Not available";
CM_ SG_ 2566838782 AuxiliaryIO10 "Auxiliary I/O #10: Identifies the current status of auxiliary input/output functions that are configured uniquely per application.00b = Auxiliary channel off01b = Auxiliary channel on10b = Error11b = Not available";
CM_ SG_ 2566838782 AuxiliaryIO11 "Auxiliary I/O #11: Identifies the current status of auxiliary input/output functions that are configured uniquely per application.00b = Auxiliary channel off01b = Auxiliary channel on10b = Error11b = Not available";
CM_ SG_ 2566838782 AuxiliaryIO12 "Auxiliary I/O #12: Identifies the current status of auxiliary input/output functions that are configured uniquely per application.00b = Auxiliary channel off01b = Auxiliary channel on10b = Error11b = Not available";
CM_ SG_ 2566838782 AuxiliaryIO13 "Auxiliary I/O #13: Identifies the current status of auxiliary input/output functions that are configured uniquely per application.00b = Auxiliary channel off01b = Auxiliary channel on10b = Error11b = Not available";
CM_ SG_ 2566838782 AuxiliaryIO14 "Auxiliary I/O #14: Identifies the current status of auxiliary input/output functions that are configured uniquely per application.00b = Auxiliary channel off01b = Auxiliary channel on10b = Error11b = Not available";
CM_ SG_ 2566838782 AuxiliaryIO15 "Auxiliary I/O #15: Identifies the current status of auxiliary input/output functions that are configured uniquely per application.00b = Auxiliary channel off01b = Auxiliary channel on10b = Error11b = Not available";
CM_ SG_ 2566838782 AuxiliaryIO16 "Auxiliary I/O #16: Identifies the current status of auxiliary input/output functions that are configured uniquely per application.00b = Auxiliary channel off01b = Auxiliary channel on10b = Error11b = Not available";
CM_ SG_ 2566838782 AuxiliaryIOChannel1 "Auxiliary I/O Channel #1: Auxiliary channel of data (16 bit) read by the ECU.  This data is in A/D counts and is manufacturer specific.  It may be configured uniquely per application.";
CM_ SG_ 2566838782 AuxiliaryIOChannel2 "Auxiliary I/O Channel #2: Auxiliary channel of data (16 bit) read by the ECU.  This data is in A/D counts and is manufacturer specific.  It may be configured uniquely per application.";
CM_ BO_ 2566839038 "Software Identification";
CM_ SG_ 2566839038 NmrOfSftwrIdntftnFlds "Number of Software Identification Fields: Number of software identification designators represented in the software identification parameter group.";
CM_ BO_ 2566839294 "Engine Fluid Level/Pressure 2";
CM_ SG_ 2566839294 EngnFl1InjtrMtrngRl1Prssr "Engine Fuel 1 Injector Metering Rail 1 Pressure: The gage pressure of fuel in the primary, or first, metering rail as delivered from the supply pump to the injector metering intake.";
CM_ SG_ 2566839294 EngnFl1InjtrMtrngRl2Prssr "Engine Fuel 1 Injector Metering Rail 2 Pressure: The gage pressure of fuel in the metering rail #2 as delivered from the supply pump to the injector metering intake.  See Figure SPN16_A for fuel system related parameters.  Although the figure does no...";
CM_ SG_ 2566839294 EngnFl1InjtrTmngRl1Prssr "Engine Fuel 1 Injector Timing Rail 1 Pressure: The gage pressure of fuel in the timing rail delivered from the supply pump to the injector timing intake.";
CM_ SG_ 2566839294 EngnFlInjtnCntrlPrssr "Engine Fuel Injection Control Pressure: The gage pressure of the engine oil in the hydraulic accumulator that powers an intensifier used for fuel injection.";
CM_ BO_ 2566839550 "Idle Operation";
CM_ SG_ 2566839550 EngineTotalIdleFuelUsed "Engine Total Idle Fuel Used: Accumulated amount of fuel used during vehicle operation while under idle conditions.";
CM_ SG_ 2566839550 EngineTotalIdleHours "Engine Total Idle Hours: Accumulated time of operation of the engine while under idle conditions.";
CM_ BO_ 2566839806 "Turbocharger";
CM_ SG_ 2566839806 EngineTurbocharger1Speed "Engine Turbocharger 1 Speed: Rotational velocity of rotor in the turbocharger.";
CM_ SG_ 2566839806 EngnTrhrgrDffrntlSpd "Engine Turbocharger Differential Speed: The difference between turbocharger speeds on engine systems with 2 or more turbochargers. If there are are more than 2 turbochargers, it will be the difference between the fastest and the slowest turbocharger ...";
CM_ SG_ 2566839806 EngnTrhrgrLOlPrssr1 "Engine Turbocharger Lube Oil Pressure 1: Gage pressure of oil in turbocharger lubrication system.";
CM_ SG_ 2566839806 EngnTrhrgrOlLvlSwth "Engine Turbocharger Oil Level Switch: Switch signal which indicates the presence of oil at the turbocharger00b = No oil present at turbocharger01b = Oil present at turbocharger10b = Error11b = Not available";
CM_ BO_ 2566840062 "Engine Air Start Pressure";
CM_ SG_ 2566840062 EngineAirStartPressure "Engine Air Start Pressure: Gage pressure of air in an engine starting system that utilizes compressed air to provide the force required to rotate the crankshaft.";
CM_ SG_ 2566840062 EngineAirStopPressure "Engine Air Stop Pressure: Gage pressure of air in an engine stopping system that utilizes compressed air to provide the force required to stop the crankshaft. Engine stopping air is typically used for emergency engine stopping.";
CM_ SG_ 2566840062 EngnArStrtPrssrExtnddRng "Engine Air Start Pressure (Extended Range): Gage pressure of air in an engine starting system that utilizes compressed air to provide the force required to rotate the crankshaft.See SPN 82 for higher resolution.";
CM_ BO_ 2566840318 "Electronic Engine Controller 3";
CM_ SG_ 2566840318 Aftertreatment1ExhaustDewPoint "Aftertreatment 1 Exhaust Dew Point: Indicates that the temperature on the exhaust side of the aftertreatment has exceeded the dew point, as estimated by the ECU in exhaust bank 1.00b = Not exceeded the dew point01b = Exceeded the dew point10b = Error...";
CM_ SG_ 2566840318 Aftertreatment2ExhaustDewPoint "Aftertreatment 2 Exhaust Dew Point: Indicates that the temperature on the exhaust side of the aftertreatment has exceeded the dew point, as estimated by the ECU in exhaust bank 2.00b = Not exceeded the dew point01b = Exceeded the dew point10b = Error...";
CM_ SG_ 2566840318 Aftrtrtmnt1ExhstGsMssFlwRt "Aftertreatment 1 Exhaust Gas Mass Flow Rate: Measured/calculated exhaust gas mass upstream of the aftertreatmentsystem in exhaust bank 1 and 2.";
CM_ SG_ 2566840318 EngineSDesiredOperatingSpeed "Engine's Desired Operating Speed: An indication by the engine of the optimal operating speed of the engine for the current existing conditions.  These conditions may include the torque generated to accommodate powertrain demands from the operator (vi...";
CM_ SG_ 2566840318 ESDsdOptSpdAstAdstt "Engine's Desired Operating Speed Asymmetry Adjustment: This byte is utilized in transmission gear selection routines and indicates the engine's preference of lower versus higher engine speeds should its desired speed not be achievable.  This is a sca...";
CM_ SG_ 2566840318 EstmtdEngnPrstLsssPrntTrq "Estimated Engine Parasitic Losses - Percent Torque: The calculated torque that indicates the estimated amount of torque loss due to engine parasitics, such as cooling fan, air compressor, air conditioning, etc. It is expressed as a percent of Engine ...";
CM_ SG_ 2566840318 NominalFrictionPercentTorque "Nominal Friction - Percent Torque: The calculated torque that indicates the amount of torque required by the basic engine itself added by the loss torque of accessories.  It contains the frictional and thermodynamic loss of the engine itself, pumping...";
CM_ SG_ 2566840318 EngineExhaust1DewPoint "Engine Exhaust 1 Dew Point: Indicates that the temperature on the intake side of the aftertreatment system has exceeded the dew point, as estimated by the ECU in exhaust bank 1.00b = Not exceeded the dew point01b = Exceeded the dew point10b = Error11...";
CM_ SG_ 2566840318 EngineExhaust2DewPoint "Engine Exhaust 2 Dew Point: Indicates that the temperature on the intake side of the aftertreatment system has exceeded the dew point, as estimated by the ECU in exhaust bank 2.00b = Not exceeded the dew point01b = Exceeded the dew point10b = Error11...";
CM_ BO_ 2566840574 "Vehicle Distance";
CM_ SG_ 2566840574 TotalVehicleDistance "Total Vehicle Distance: Accumulated distance traveled by vehicle during its operation.NOTE See SPN 917 for alternate resolution.";
CM_ SG_ 2566840574 TripDistance "Trip Distance: Distance traveled during all or part of a journey.NOTE See SPN 918 for alternate resolution.";
CM_ BO_ 2566840830 "Retarder Configuration";
CM_ SG_ 2566840830 MaximumRetarderSpeedPoint2 "Maximum Retarder Speed, Point 2: Maximum speed of retarder (Please reference PGN 65249).";
CM_ SG_ 2566840830 RetarderControlMethod "Retarder Control Method: This parameter identifies the number of steps used by the retarder.0 = Continuous control1 = On/Off control2 to 250 = Number of steps";
CM_ SG_ 2566840830 RetarderLocation "Retarder Location: This parameter defines whether the torque/speed curve defined by the retarder configuration message (PGN 65249) is dependent on engine rpm, output shaft rpm, or other parameter.  The data type of this parameter is measured.0000b = ...";
CM_ SG_ 2566840830 RetarderPercentTorqueAtPoint3 "Retarder Percent Torque At Point 3: The torque limit that indicates the available retarder torque which can be provided by the retarder at points 3 and 4 of the retarder torque map.  Please reference PGN 65249.  The data is transmitted in indicated t...";
CM_ SG_ 2566840830 RetarderPercentTorqueAtPoint4 "Retarder Percent Torque At Point 4: The torque limit that indicates the available retarder torque which can be provided by the retarder at points 3 and 4 of the retarder torque map.  Please reference PGN 65249.  The data is transmitted in indicated t...";
CM_ SG_ 2566840830 RetarderReferenceTorque "Retarder Reference Torque: This parameter is the 100% reference value for all defined indicated retarder torque parameters.  It is only defined once and doesn't change if a different retarder torque map becomes valid.";
CM_ SG_ 2566840830 RetarderSpeedAtIdlePoint1 "Retarder Speed At Idle, Point 1: Please reference PGN 65249";
CM_ SG_ 2566840830 RetarderSpeedAtPeakTorquePoint5 "Retarder Speed At Peak Torque, Point 5: Please reference PGN 65249";
CM_ SG_ 2566840830 RetarderSpeedAtPoint3 "Retarder Speed At Point 3: Retarder speed of point 3 of the engine retarder torque map.  Please reference PGN 65249.";
CM_ SG_ 2566840830 RetarderSpeedAtPoint4 "Retarder Speed At Point 4: Retarder speed of point 4 of the engine retarder torque map.  Please reference PGN 65249.";
CM_ SG_ 2566840830 RetarderType "Retarder Type: A vehicle retarder is a supplementary device to the wheel brakes for the driver to better control the vehicle.  The wheel brakes used in the vehicle are not designed for continuous retarding operation.  In a prolonged period of braking...";
CM_ SG_ 2566840830 RtrdrPrntTrqAtIdlPnt1 "Retarder Percent Torque At Idle, Point 1: The torque limit that indicates the available retarder torque which can be provided by the retarder at idle speed.  The data is transmitted in indicated torque as a percent of the reference retarder torque.";
CM_ SG_ 2566840830 RtrdrPrntTrqAtMxmmSpdPnt2 "Retarder Percent Torque At Maximum Speed, Point 2: The torque limit that indicates the available retarder torque which can be provided by the retarder at its maximum speed.  Please reference PGN 65249.  The data is transmitted in indicated torque as ...";
CM_ SG_ 2566840830 RtrdrPrntTrqAtPkTrqPnt5 "Retarder Percent Torque At Peak Torque, Point 5: The torque limit that indicates the available retarder torque which can be provided by the retarder at point 5 of the retarder torque map.  Please reference PGN 65249.  The data is transmitted in indic...";
CM_ BO_ 2566841086 "Transmission Configuration";
CM_ SG_ 2566841086 NumberOfForwardGearRatios "Number of Forward Gear Ratios: Number of forward gear ratios in the transmission, provided as part of the configuration.";
CM_ SG_ 2566841086 NumberOfReverseGearRatios "Number of Reverse Gear Ratios: Number of reverse gear ratios in the transmission, provided as part of the transmission configuration.";
CM_ SG_ 2566841086 TransmissionGearRatio "Transmission Gear Ratio: The transmission configuration describes the number of forward gears, the number of reverse gears, and the ratio of each gear with the following resolution.";
CM_ BO_ 2566841342 "Engine Configuration 1";
CM_ SG_ 2566841342 EngineDefaultIdleTorqueLimit "Engine Default Idle Torque Limit: Companion parameter to Transmission Communications Failure Idle Torque Limit (SPN 7827).  This echo parameter provides confirmation to the transmission that the engine has received and will invoke the requested SPN 7...";
CM_ SG_ 2566841342 EngineDefaultTorqueLimit "Engine Default Torque Limit: Companion parameter to Transmission Torque Limit (SPN 1845).  This echo parameter provides confirmation to the transmission that the engine has received and will invoke the requested Transmission Torque Limit in the event...";
CM_ SG_ 2566841342 EngineMomentOfInertia "Engine Moment of Inertia: Moment of inertia for the engine, including items driven full-time by the engine such as fuel, oil and cooling pumps.  The inertia from the following items are not included: flywheel, alternator, compressor, fan, and other e...";
CM_ SG_ 2566841342 EnginePercentTorqueAtIdlePoint1 "Engine Percent Torque At Idle, Point 1: The torque limit that indicates the available engine torque which can be provided by the engine at idle speed.  This parameter may be influenced by engine temperature (after power up) and other stationary chang...";
CM_ SG_ 2566841342 EnginePercentTorqueAtPoint2 "Engine Percent Torque At Point 2: The torque limit that indicates the available engine torque which can be provided by the engine at point 2 of the engine map (see PGN 65251 and supporting documents).  In engine configuration mode 1 and 3 (see Table ...";
CM_ SG_ 2566841342 EnginePercentTorqueAtPoint3 "Engine Percent Torque At Point 3: The torque limit that indicates the available engine torque which can be provided by the engine at point 3, 4, and 5 of the engine map (see PGN 65251 and supporting documents)..  It is required that one of these poin...";
CM_ SG_ 2566841342 EnginePercentTorqueAtPoint4 "Engine Percent Torque At Point 4: The torque limit that indicates the available engine torque which can be provided by the engine at point 3, 4, and 5 of the engine map (see PGN 65251 and supporting documents).  It is required that one of these point...";
CM_ SG_ 2566841342 EnginePercentTorqueAtPoint5 "Engine Percent Torque At Point 5: The torque limit that indicates the available engine torque which can be provided by the engine at point 3, 4, and 5 of the engine map (see PGN 65251 and supporting documents).  It is required that one of these point...";
CM_ SG_ 2566841342 EngineReferenceTorque "Engine Reference Torque: This parameter is the 100% reference value for all defined indicated engine torque parameters.  It is only defined once and doesn't change if a different engine torque map becomes valid.";
CM_ SG_ 2566841342 EngineSpeedAtHighIdlePoint6 "Engine Speed At High Idle, Point 6: Engine speed of high idle (point 6) of the engine torque map (see PGN 65251 and supporting document).  In engine configuration mode 3 (see Figure PGN65251_C), point 6 is not defined by the engine torque map but by ...";
CM_ SG_ 2566841342 EngineSpeedAtIdlePoint1 "Engine Speed At Idle, Point 1: Stationary low idle speed of engine which includes influences due to engine temperature (after power up) and other stationary changes (calibration offsets, sensor failures, etc).  This parameter is point 1 of the engine...";
CM_ SG_ 2566841342 EngineSpeedAtPoint2 "Engine Speed At Point 2: Engine speed of point 2 of the engine torque map (see PGN 65251 and supporting document).  In engine configuration mode 1 and 3, point 2 is defined as the kick-in point from which torque is reduced to zero.  In mode 2 (see Ta...";
CM_ SG_ 2566841342 EngineSpeedAtPoint3 "Engine Speed At Point 3: Engine speed of point 3, 4, and 5 of the engine torque map (see PGN 65251 and supporting document).  It is recommended that one of these points indicate the peak torque point for the current engine torque map.  Points 3, 4, a...";
CM_ SG_ 2566841342 EngineSpeedAtPoint4 "Engine Speed At Point 4: Engine speed of point 3, 4, and 5 of the engine torque map (see PGN 65251 and supporting document).  It is recommended that one of these points indicate the peak torque point for the current engine torque map.  Points 3, 4, a...";
CM_ SG_ 2566841342 EngineSpeedAtPoint5 "Engine Speed At Point 5: Engine speed of point 3, 4, and 5 of the engine torque map (see PGN 65251 and supporting document).  It is recommended that one of these points indicate the peak torque point for the current engine torque map.  Points 3, 4, a...";
CM_ SG_ 2566841342 EngnGnKpOfThEndspdGvrnr "Engine Gain (kp) Of The Endspeed Governor: The endspeed governor is defined as a linear line with the following equations (Capital letters mean physical values, small letters mean normalized values).  Refer to Figures PGN65251_A and PGN65251_B.The ga...";
CM_ SG_ 2566841342 EngnMxmmMmntrOvrrdSpdPnt7 "Engine Maximum Momentary Override Speed, Point 7: The maximum engine speed above high idle allowed by the engine control during a momentary high idle override.  This duration of the override is limited by the maximum momentary override time limit, SP...";
CM_ SG_ 2566841342 EngnMxmmMmntrOvrrdTmLmt "Engine Maximum Momentary Override Time Limit: The maximum time limit allowed to override the engine's high idle speed.0 indicates that no override of high idle is allowed.  As value of 255 indicates no time restriction (not applicable)";
CM_ SG_ 2566841342 EngnRqstdSpdCntrlRngLwrLmt "Engine Requested Speed Control Range Lower Limit: The minimum engine speed that the engine will allow when operating in a speed control/limit mode.";
CM_ SG_ 2566841342 EngnRqstdSpdCntrlRngUpprLmt "Engine Requested Speed Control Range Upper Limit: The maximum engine speed regardless of load that the engine will allow when operating in a speed control/limit mode, excluding any maximum momentary engine override speed, if supported.";
CM_ SG_ 2566841342 EngnRqstdTrqCntrlRngLwrLmt "Engine Requested Torque Control Range Lower Limit: The minimum engine torque that the engine will allow when operating in a torque control/limit mode.";
CM_ SG_ 2566841342 EngnRqstdTrqCntrlRngUpprLmt "Engine Requested Torque Control Range Upper Limit: The maximum engine torque that the engine will allow when operating in a torque control/limit mode.";
CM_ SG_ 2566841342 ERqstdSpdCtRUppLtExtddR "Engine Requested Speed Control Range Upper Limit (Extended Range): The maximum engine speed regardless of load that the engine will allow when operating in a speed control/limit mode, excluding any maximum momentary engine override speed, if supporte...";
CM_ SG_ 2566841342 SupportTsc1ControlPurposeGroup1 "Support TSC1 Control Purpose Group 1: This parameter indicates which TSC1 control purposes are supported in group 1 of 4. One bit is used to convey the support of each Control Purpose. A value of 0 equals supported and a value of 1 equals not support...";
CM_ SG_ 2566841342 SupportTsc1ControlPurposeGroup2 "Support TSC1 Control Purpose Group 2: This parameter indicates which TSC1 control purposes are supported in group 2 of 4. One bit is used to convey the support of each Control Purpose. A value of 0 equals supported and a value of 1 equals not support...";
CM_ SG_ 2566841342 SupportTsc1ControlPurposeGroup3 "Support TSC1 Control Purpose Group 3: This parameter indicates which TSC1 control purposes are supported in group 3 of 4. One bit is used to convey the support of each Control Purpose. A value of 0 equals supported and a value of 1 equals not support...";
CM_ SG_ 2566841342 SupportTsc1ControlPurposeGroup4 "Support TSC1 Control Purpose Group 4: This parameter indicates which TSC1 control purposes are supported in group 4 of 4. One bit is used to convey the support of each Control Purpose. A value of 0 equals supported and a value of 1 equals not support...";
CM_ SG_ 2566841342 SupportVariableRateTsc1Message "Support Variable Rate TSC1 Message: This parameter indicates which TSC1 transmission rates are supported by the engine ECU in addition to the required 10ms transmission rate for temporary powertrain control purposes. Bit Position      Transmission Ra...";
CM_ SG_ 2566841342 EngineDefaultSpeedLimit "Engine Default Speed Limit: Companion parameter to SPN 23774 (Transmission Speed Limit).  This echo parameter provides confirmation to the transmission that the engine has received and will invoke the requested SPN 23774 (Transmission Speed Limit) in...";
CM_ BO_ 2566841598 "Shutdown";
CM_ SG_ 2566841598 ACHighPressureFanSwitch "A/C High Pressure Fan Switch: Switch signal which indicates that the pressure in the coolant circuit of an air conditioning system is high and the fan may be engaged.00b = Pressure normal01b = Pressure high, fan may be engaged10b = Error11b = Not ava...";
CM_ SG_ 2566841598 ClntLvlEngnPrttnShtdwnStts "Coolant Level Engine Protection Shutdown Status: Parameter which indicates the configuration of the coolant level engine protection shutdown.00b = Disabled - calibration does not allow engine protection due to low coolant level or the override is cur...";
CM_ SG_ 2566841598 EngineAirShutoffCommandStatus "Engine Air Shutoff Command Status: State signal which indicates when the Air Shutoff  driver output is being driven. Disabled means controller wants air flowing to the engine. Status of the airflow  shutoff as being commanded by the ECU.00b = Air Shu...";
CM_ SG_ 2566841598 EngineAirShutoffStatus "Engine Air Shutoff Status: State signal which indicates the actual measured position of the Air Shutoff.00b = Air flow allowed to engine01b = Air flow restricted10b = Error11b = Not AvailableNote:   This parameter, in conjunction with SPN 2813 - Engi...";
CM_ SG_ 2566841598 EngineAlarmAcknowledge "Engine Alarm Acknowledge: The Engine Alarm Acknowledge Input signal as measured by the reporting ECU.  The Engine Alarm Acknowledge is a mechanism for external acknowledgement of the SPN 2814,  Engine Alarm Output Command. 00b = Engine Alarm Acknowle...";
CM_ SG_ 2566841598 EngineAlarmOutputCommandStatus "Engine Alarm Output Command Status: State signal which indicates when the Alarm driver output is being driven. Not active means the Controller has no alarm level conditions.00b = Engine Alarm Output Command Not Active01b = Engine Alarm Output Command...";
CM_ SG_ 2566841598 EngineIdleShutdownTimerFunction "Engine Idle Shutdown Timer Function: Parameter which indicates the configuration of the idle shutdown timer system.00b = Disabled in calibration01b = Enabled in calibration10b = Error11b = Not available";
CM_ SG_ 2566841598 EngineIdleShutdownTimerOverride "Engine Idle Shutdown Timer Override: Status signal which indicates the status of the override feature of the idle shutdown timer system.  See Figure SPN590_A.00b = Inactive01b = Active10b = Error11b = Not available";
CM_ SG_ 2566841598 EngineIdleShutdownTimerState "Engine Idle Shutdown Timer State: Status signal which indicates the current mode of operation of the idle shutdown timer system.  See Figure SPN590_A.00b = Inactive01b = Active10b = Error11b = Not available";
CM_ SG_ 2566841598 EngineOilPressureSwitch "Engine Oil Pressure Switch: Measured engine oil pressure with respect to the pre-set threshold.00b = OK (Engine Oil Pressure Above Min Threshold)01b = Not OK (Engine Oil Pressure Below Min Threshold)10b = Error (Switch State Cannot Be Determined)11b ...";
CM_ SG_ 2566841598 EngineOverspeedTest "Engine Overspeed Test: The engine overspeed test signal as measured by the reporting ECM.  Engine Overspeed Test is a mechanism to simulate engine overspeed situations, while operating the engine within the engine's safe operating range.State signal ...";
CM_ SG_ 2566841598 EngineWaitToStartLamp "Engine Wait to Start Lamp: Lamp signal which indicates that the engine is too cold to start and the operator should wait until the signal becomes inactive (turns off).  See SPN 5416 for the lamp operating condition.00b = Off01b = On10b = Error11b = N...";
CM_ SG_ 2566841598 EngnIdlShtdwnDrvrAlrtMd "Engine Idle Shutdown Driver Alert Mode: Status signal which indicates the status of the driver alert mode of the idle shutdown timer system.  While the driver alert mode is active, the idle shutdown timer may be overridden.  See Figure SPN590_A.00b =...";
CM_ SG_ 2566841598 EngnIdlShtdwnHsShtdwnEngn "Engine Idle Shutdown has Shutdown Engine: Status signal which identifies whether or not the engine has been shutdown by the idle shutdown timer system.  See Figure SPN590_A.00b = No01b = Yes10b = Error11b = Not available";
CM_ SG_ 2566841598 EngnPrttnSstmApprhngShtdwn "Engine Protection System Approaching Shutdown: Status signal which indicates that engine shutdown is imminent.  This engine protection signal can be a result of different systems failing, i.e., engine overheating. See Figure SPN1107_A.00b = Not appro...";
CM_ SG_ 2566841598 EngnPrttnSstmCnfgrtn "Engine Protection System Configuration: Parameter which indicates the configuration of the engine shutdown system.00b = Disabled in calibration01b = Enabled in calibration10b = Error11b = Not available";
CM_ SG_ 2566841598 EngnPrttnSstmHsShtdwnEngn "Engine Protection System has Shutdown Engine: Status signal which indicates whether or not the engine protection system has shutdown the engine.  See Figure SPN1107_A.00b = No01b = Yes10b = Error11b = Not available";
CM_ SG_ 2566841598 EngnPrttnSstmTmrOvrrd "Engine Protection System Timer Override: Status signal which indicates the status of the override feature of the engine protection system timer. See Figure SPN1107_A.00b = Inactive01b = Active10b = Error11b = Not available";
CM_ SG_ 2566841598 EngnPrttnSstmTmrStt "Engine Protection System Timer State: Status signal which indicates the current mode of the engine protection system timer system.  See Figure SPN1107_A.00b = Inactive01b = Active10b = Error11b = Not available";
CM_ SG_ 2566841598 PtoShutdownHasShutdownEngine "PTO Shutdown has Shutdown Engine: Status signal which identifies whether or not the engine has been shutdown by the PTO shutdown system.00b = No01b = Yes10b = Error11b = Not available";
CM_ SG_ 2566841598 RefrigerantHighPressureSwitch "Refrigerant High Pressure Switch: Switch signal which indicates the position of the high pressure switch in the coolant circuit of an air conditioning system.  When the switch is enabled, the pressure inside the circuit is too high and the compressor...";
CM_ SG_ 2566841598 RefrigerantLowPressureSwitch "Refrigerant Low Pressure Switch: Switch signal which indicates the position of the low pressure switch in the coolant circuit of an air conditioning system.  When the switch is enabled, the pressure inside the circuit is too low and the compressor cl...";
CM_ SG_ 2566841598 MhnIntvtShtdwnHsShtdwnEngn "Machine Inactivity Shutdown has Shutdown Engine: Status signal which identifies whether or not the engine has been shutdown by the machine inactivity shutdown timer system.00b = No01b = Yes10b = Error11b = Not available";
CM_ BO_ 2566841854 "Engine Hours, Revolutions";
CM_ SG_ 2566841854 EngineTotalHoursOfOperation "Engine Total Hours of Operation: Accumulated time of operation of engine.";
CM_ SG_ 2566841854 EngineTotalRevolutions "Engine Total Revolutions: Accumulated number of revolutions of engine crankshaft during its operation.";
CM_ BO_ 2566842110 "Time/Date";
CM_ SG_ 2566842110 Day "Day: The day component of the current calendar date.  This should be reported as the day component of the current date at UTC (Universal Time Coordinate), a.k.a. GMT; however, it may be reported as the day component of the current date at a local tim...";
CM_ SG_ 2566842110 Hours "Hours: The hour component of the current time of day.  This should be reported as the hour component of the current time at UTC (Universal Time Coordinate), a.k.a. GMT; however, it may be reported as the hour component of the current time at a local ...";
CM_ SG_ 2566842110 LocalHourOffset "Local hour offset: The hour component of the offset between the UTC (Universal Time Coordinate) time and date and a local time zone time and date.  This is the number of hours to add to UTC, a.k.a. GMT, time and date to convert to the time and date i...";
CM_ SG_ 2566842110 LocalMinuteOffset "Local minute offset: The minute component of the offset between the UTC time and date and a local time zone time and date.  This is the number of minutes to add to UTC (Universal Time Coordinate) time and date to convert to the time and date in the l...";
CM_ SG_ 2566842110 Minutes "Minutes: The minutes component of the current time of day.  This should be reported as the minutes component of the current time at UTC (Universal Time Coordinate), a.k.a. GMT; however, it may be reported as the minutes component of the current time ...";
CM_ SG_ 2566842110 Month "Month: The month component of the current calendar date.  This should be reported as the month component of the current date at UTC (Universal Time Coordinate), a.k.a. GMT; however, it may be reported as the month component of the current date at a l...";
CM_ SG_ 2566842110 Seconds "Seconds: The seconds component of the current time of day.  This should be reported as the seconds component of the current time at UTC (Universal Time Coordinate), a.k.a. GMT; however, it may be reported as the seconds component of the current time ...";
CM_ SG_ 2566842110 Year "Year: The year component of the current calendar date.  This should be reported as the year component of the current date at UTC (Universal Time Coordinate), a.k.a. GMT; however, it may be reported as the year component of the current date at a local...";
CM_ BO_ 2566842366 "Vehicle Hours";
CM_ SG_ 2566842366 TotalPowerTakeoffHours "Total Power Takeoff Hours: Accumulated time of operation of power takeoff device.";
CM_ SG_ 2566842366 TotalVehicleHours "Total Vehicle Hours: Accumulated time of operation of vehicle.";
CM_ BO_ 2566842622 "Vehicle Direction/Speed";
CM_ SG_ 2566842622 Altitude "Altitude: Altitude of the vehicle referenced to sea level at standard atmospheric pressure and temperature.";
CM_ SG_ 2566842622 CompassBearing "Compass Bearing: Present compass bearing of vehicle.";
CM_ SG_ 2566842622 NavigationBasedVehicleSpeed "Navigation-Based Vehicle Speed: Speed of the vehicle as calculated from a device such as a Global Positioning System (GPS).";
CM_ SG_ 2566842622 Pitch "Pitch: Pitch (rotation about the y-axis) of the vehicle as calculated by the navigation device(s).  The pitch angle for an angle of ascent is reported with a positive value. This parameter is defined according to a Z-Down axis system and the sign of ...";
CM_ BO_ 2566842878 "Fuel Consumption (Liquid) 1";
CM_ SG_ 2566842878 EngineTotalFuelUsed "Engine Total Fuel Used: Accumulated amount of fuel used during vehicle operation.  See SPN 5054 for alternate resolution.";
CM_ SG_ 2566842878 EngineTripFuel "Engine Trip Fuel: Fuel consumed during all or part of a journey.  See SPN 5053 for alternate resolution.";
CM_ BO_ 2566843134 "Vehicle Weight";
CM_ SG_ 2566843134 AxleLocation "Axle Location: To identify to which of several similar devices (such as tires or fuel tanks) the information applies.The low order 4 bits represent a position number, counting left to right when facing in the direction of normal vehicle travel (forwa...";
CM_ SG_ 2566843134 AxleWeight "Axle Weight: Total mass imposed by the tires on the road surface at the specified axle.";
CM_ SG_ 2566843134 CargoWeight "Cargo Weight: The mass of freight carried.";
CM_ SG_ 2566843134 TrailerWeight "Trailer Weight: Total mass of freight-carrying vehicle designed to be pulled by truck, including the weight of the contents.";
CM_ BO_ 2566843902 "Cruise Control/Vehicle Speed Setup";
CM_ SG_ 2566843902 CruiseControlHighSetLimitSpeed "Cruise Control High Set Limit Speed: Maximum vehicle velocity at which cruise can be set.If Cruise Control Adjusted Maximum Speed (SPN 7495) is supported, then SPN 7495 has priority over SPN 87. See the definition for SPN 7495 for more details.";
CM_ SG_ 2566843902 MaximumVehicleSpeedLimit "Maximum Vehicle Speed Limit: Maximum vehicle velocity allowed.   See SPN 6808 for an alternate resolution.";
CM_ SG_ 2566843902 MxmmVhlSpdLmtHghRsltn "Maximum Vehicle Speed Limit (High Resolution): Maximum vehicle velocity allowed. See SPN 74 for an alternate resolution.";
CM_ SG_ 2566843902 CrsCntrlOprtrLwStLmtSpd "Cruise Control Operator Low Set Limit Speed: Minimum vehicle velocity at which cruise can be set by the operator or minimum vehicle velocity for cruise operation before it will exit cruise control operation.Associated with the CCVS1 signals SPN 599 -...";
CM_ SG_ 2566843902 CrsCntrlSstmLwStLmtSpd "Cruise Control System Low Set Limit Speed: Minimum vehicle velocity at which cruise can be set or resumed by a source other than the operator.Associated with the CCVS2 signals SPN 5604 - Cruise Control Resume Command and SPN 9843 - Cruise Control Set...";
CM_ SG_ 2566843902 CrsCntrlDslCmmndSpprt "Cruise Control Disable Command Support: Indicates support for SPN 5603 Cruise Control Disable Command by the system that manages cruise control.00b = System does not support the 'Cruise Control Disable Command'01b = System does support the Cruise Con...";
CM_ SG_ 2566843902 CrsCntrlRsmCmmndSpprt "Cruise Control Resume Command Support: Indicates support for SPN 5604 Cruise Control Resume Command by the system that manages cruise control.00b = System does not support the 'Cruise Control Resume Command' feature01b = System does support the Cruis...";
CM_ SG_ 2566843902 CrsCntrlPsCmmndSpprt "Cruise Control Pause Command Support: Indicates support for SPN 5605 Cruise Control Pause Command by the system that manages cruise control.00b = System does not support the 'Cruise Control Pause Command' feature01b = System does support the Cruise C...";
CM_ SG_ 2566843902 CruiseControlSetCommandSupport "Cruise Control Set Command Support: Indicates support for SPN 9843 Cruise Control Set Command by the system that manages cruise control.00b = System does not support the 'Cruise Control Set Command' feature01b = System does support the Cruise Control...";
CM_ SG_ 2566843902 PwrtrnAdptvCrsCntrlTp "Powertrain Adaptive Cruise Control Type: Status to indicate the type of adaptive cruise control that is supported by the powertrain and the controller that manages cruise control and its ability to support the Cruise Control Pause/Resume Command para...";
CM_ BO_ 2566844158 "Engine Temperature 1";
CM_ SG_ 2566844158 EngineCoolantTemperature "Engine Coolant Temperature: Temperature of liquid found in engine cooling system.";
CM_ SG_ 2566844158 EngineFuel1Temperature1 "Engine Fuel 1 Temperature 1: Temperature of fuel (or gas) of the first fuel type. See SPN 3468 for a second temperature measurement of the first fuel type.";
CM_ SG_ 2566844158 EngineIntercoolerTemperature "Engine Intercooler Temperature: Temperature of liquid found in the intercooler located after the turbocharger.";
CM_ SG_ 2566844158 EngineOilTemperature1 "Engine Oil Temperature 1: Temperature of the engine lubricant.Note:  If there is only one engine oil temperature measurement, this SP should be used.  This is the SP that is typically displayed on an on-highway truck instrument cluster.See also SPNs ...";
CM_ SG_ 2566844158 EngnChrgArClrThrmsttOpnng "Engine Charge Air Cooler Thermostat Opening: The current position of the thermostat used to regulate the temperature of the engine charge air cooler.  A value of 0% represents the thermostat being completely closed and 100% represents the thermostat ...";
CM_ SG_ 2566844158 EngnTrhrgr1OlTmprtr "Engine Turbocharger 1 Oil Temperature: Temperature of the turbocharger lubricant.";
CM_ BO_ 2566844414 "Engine Fluid Level/Pressure 1";
CM_ SG_ 2566844414 EngineCoolantLevel1 "Engine Coolant Level 1: Ratio of volume of liquid found in engine cooling system to total cooling system volume.  Typical monitoring location is in the coolant expansion tank.";
CM_ SG_ 2566844414 EngineCoolantPressure1 "Engine Coolant Pressure 1: Gage pressure of liquid found in engine cooling system.See SPN 20 for alternate range and resolution.";
CM_ SG_ 2566844414 EngineCrankcasePressure1 "Engine Crankcase Pressure 1: First instance of the gage pressure inside engine crankcase.";
CM_ SG_ 2566844414 EngineFuelDeliveryPressure "Engine Fuel Delivery Pressure: Gage pressure of fuel in system as delivered from supply pump to the injection pump.  See SPN 7469 for alternate resolution.See also SPN 5578 for Fuel Delivery Absolute Pressure.";
CM_ SG_ 2566844414 EngineOilLevel "Engine Oil Level: Ratio of current volume of engine sump oil to maximum required volume.";
CM_ SG_ 2566844414 EngineOilPressure1 "Engine Oil Pressure 1: Gage pressure of oil in engine lubrication system as provided by oil pump.  See SPN 7468 for alternate resolution.";
CM_ SG_ 2566844414 EngnExtnddCrnksBlwBPrssr "Engine Extended Crankcase Blow-by Pressure: Differential crankcase blow-by pressure as measured through a tube with a venturi. (SPN 1264 is not to be used - obsolete)";
BA_DEF_ SG_  "SPN" INT 0 524287;
BA_DEF_ BO_  "VFrameFormat" ENUM  "StandardCAN","ExtendedCAN","reserved","J1939PG";
BA_DEF_DEF_  "SPN" 0;
BA_DEF_DEF_  "VFrameFormat" "J1939PG";
BA_ "SPN" SG_ 2566775294 AirConditionerCompressorStatus 7853;
BA_ "SPN" SG_ 2566775294 CACRfrgrntCmprssrOtltPrssr 2609;
BA_ "SPN" SG_ 2566775294 FrntCnBlwrFnSpdStpnt 21128;
BA_ "SPN" SG_ 2566775294 CabACAutoModeSwitch 21283;
BA_ "SPN" SG_ 2566775294 CabACMaximumDefrostModeSwitch 21284;
BA_ "SPN" SG_ 2566775294 CabACRecirculationModeSwitch 21285;
BA_ "SPN" SG_ 2566775294 ACEvaporatorTemperature 1547;
BA_ "SPN" SG_ 2566775294 CACRfrgrntCmprssrStnPrssr 21282;
BA_ "SPN" SG_ 2566775294 CabACAirDistributionModeSwitch 21286;
BA_ "SPN" SG_ 2566775550 ArSspnsnSpplPrssrRqst 2608;
BA_ "SPN" SG_ 2566775550 AxlrEqpmntSpplPrssrRqst 2607;
BA_ "SPN" SG_ 2566775550 PneumaticSupplyPressureRequest 2603;
BA_ "SPN" SG_ 2566775550 PwrtrnCrtArSpplPrssrRqst 6306;
BA_ "SPN" SG_ 2566775550 SrvBrkArPrssrRqstCrt1 2605;
BA_ "SPN" SG_ 2566775550 SrvBrkArPrssrRqstCrt2 2606;
BA_ "SPN" SG_ 2566775550 PrkngAndOrTrlrArPrssrRqst 2604;
BA_ "SPN" SG_ 2566775806 TravelVelocityControlPosition 2601;
BA_ "SPN" SG_ 2566776062 PayloadCapacityPercentage 6854;
BA_ "SPN" SG_ 2566776062 PayloadCarryBackWeight 6853;
BA_ "SPN" SG_ 2566776062 PayloadPercentage 2600;
BA_ "SPN" SG_ 2566776062 PayloadWeight 6851;
BA_ "SPN" SG_ 2566776062 PayloadWeightConfidence 6852;
BA_ "SPN" SG_ 2566776318 AppliedVehicleSpeedLimit 2595;
BA_ "SPN" SG_ 2566776318 MaximumVehicleSpeedLimit1 2588;
BA_ "SPN" SG_ 2566776318 MaximumVehicleSpeedLimit2 2589;
BA_ "SPN" SG_ 2566776318 MaximumVehicleSpeedLimit3 2590;
BA_ "SPN" SG_ 2566776318 MaximumVehicleSpeedLimit4 2591;
BA_ "SPN" SG_ 2566776318 MaximumVehicleSpeedLimit5 2592;
BA_ "SPN" SG_ 2566776318 MaximumVehicleSpeedLimit6 2593;
BA_ "SPN" SG_ 2566776318 MaximumVehicleSpeedLimit7 2594;
BA_ "SPN" SG_ 2566785022 EngnExhstMnfldBnk1Tmprtr1 2434;
BA_ "SPN" SG_ 2566785022 EngnExhstMnfldBnk1Tmprtr2 5970;
BA_ "SPN" SG_ 2566785022 EngnExhstMnfldBnk2Tmprtr1 2433;
BA_ "SPN" SG_ 2566785022 EngnExhstMnfldBnk2Tmprtr2 5969;
BA_ "SPN" SG_ 2566799614 AlternateBeamHeadLightData 2352;
BA_ "SPN" SG_ 2566799614 BackUpLightAndAlarmHorn 2392;
BA_ "SPN" SG_ 2566799614 CenterStopLight 2376;
BA_ "SPN" SG_ 2566799614 HighBeamHeadLightData 2348;
BA_ "SPN" SG_ 2566799614 ImplementClearanceLight 2384;
BA_ "SPN" SG_ 2566799614 ImplementLeftFacingWorkLight 2400;
BA_ "SPN" SG_ 2566799614 ImplementLeftForwardWorkLight 2598;
BA_ "SPN" SG_ 2566799614 ImplementMarkerLight 2380;
BA_ "SPN" SG_ 2566799614 ImplementOemOption1Light 2396;
BA_ "SPN" SG_ 2566799614 ImplementOemOption2Light 2398;
BA_ "SPN" SG_ 2566799614 ImplementRearWorkLight 2394;
BA_ "SPN" SG_ 2566799614 ImplementRightFacingWorkLight 2407;
BA_ "SPN" SG_ 2566799614 ImplementRightForwardWorkLight 2402;
BA_ "SPN" SG_ 2566799614 LeftStopLight 2372;
BA_ "SPN" SG_ 2566799614 LeftTurnSignalLights 2368;
BA_ "SPN" SG_ 2566799614 LowBeamHeadLightData 2350;
BA_ "SPN" SG_ 2566799614 RearFogLights 2390;
BA_ "SPN" SG_ 2566799614 RightStopLight 2374;
BA_ "SPN" SG_ 2566799614 RightTurnSignalLights 2370;
BA_ "SPN" SG_ 2566799614 RotatingBeaconLight 2386;
BA_ "SPN" SG_ 2566799614 RunningLight 2404;
BA_ "SPN" SG_ 2566799614 TractorClearanceLight 2382;
BA_ "SPN" SG_ 2566799614 TractorFrontFogLights 2388;
BA_ "SPN" SG_ 2566799614 TractorMarkerLight 2378;
BA_ "SPN" SG_ 2566799614 TractorRearLowMountedWorkLights 2360;
BA_ "SPN" SG_ 2566799614 TractorSideLowMountedWorkLights 2364;
BA_ "SPN" SG_ 2566799614 TrtrFrntHghMntdWrkLghts 2356;
BA_ "SPN" SG_ 2566799614 TrtrFrntLwMntdWrkLghts 2354;
BA_ "SPN" SG_ 2566799614 TrtrRrHghMntdWrkLghts 2362;
BA_ "SPN" SG_ 2566799614 TrtrSdHghMntdWrkLghts 2366;
BA_ "SPN" SG_ 2566799614 TrtrUndrsdMntdWrkLghts 2358;
BA_ "SPN" SG_ 2566802174 ActiveShiftConsoleIndicator 2945;
BA_ "SPN" SG_ 2566802174 TransmissionEngineCrankEnable 2900;
BA_ "SPN" SG_ 2566802174 TransmissionManualModeIndicator 8291;
BA_ "SPN" SG_ 2566802174 TransmissionMode10Indicator 6568;
BA_ "SPN" SG_ 2566802174 TransmissionMode1Indicator 2536;
BA_ "SPN" SG_ 2566802174 TransmissionMode2Indicator 2537;
BA_ "SPN" SG_ 2566802174 TransmissionMode3Indicator 2538;
BA_ "SPN" SG_ 2566802174 TransmissionMode4Indicator 2539;
BA_ "SPN" SG_ 2566802174 TransmissionMode5Indicator 4250;
BA_ "SPN" SG_ 2566802174 TransmissionMode6Indicator 4251;
BA_ "SPN" SG_ 2566802174 TransmissionMode7Indicator 4252;
BA_ "SPN" SG_ 2566802174 TransmissionMode8Indicator 4253;
BA_ "SPN" SG_ 2566802174 TransmissionMode9Indicator 6567;
BA_ "SPN" SG_ 2566802174 TransmissionServiceIndicator 4178;
BA_ "SPN" SG_ 2566802174 TransmissionWarningIndicator 5344;
BA_ "SPN" SG_ 2566802174 TrnsmssnArSpplPrssrIndtr 6566;
BA_ "SPN" SG_ 2566802174 TrnsmssnAtNtrlMnlRtrnStt 7696;
BA_ "SPN" SG_ 2566802174 TrnsmssnCrrntRngDsplBlnkStt 4176;
BA_ "SPN" SG_ 2566802174 TrnsmssnRdFrBrkRls 3086;
BA_ "SPN" SG_ 2566802174 TrnsmssnRqstdGrFdk 3289;
BA_ "SPN" SG_ 2566802174 TrnsmssnRqstdRngDsplBlnkStt 1850;
BA_ "SPN" SG_ 2566802174 TrnsmssnRqstdRngDsplFlshStt 1849;
BA_ "SPN" SG_ 2566802174 TrnsmssnRvrsGrShftInhtStts 4261;
BA_ "SPN" SG_ 2566802174 TrnsmssnShftInhtIndtr 1851;
BA_ "SPN" SG_ 2566802174 TrnsmssnLdRdtnIndtr 11747;
BA_ "SPN" SG_ 2566802174 TrnsmssnPrDfndRngLmtIndtr 11748;
BA_ "SPN" SG_ 2566802174 TransmissionCoastModeIndicator 11749;
BA_ "SPN" SG_ 2566802174 TrnsmssnOtptShftBrkIndtr 23053;
BA_ "SPN" SG_ 2566802430 TransmissionReferenceTorque 7778;
BA_ "SPN" SG_ 2566802430 TransmissionTorqueLimit 1845;
BA_ "SPN" SG_ 2566802430 TrnsmssnCmmntnsFlrIdlTrqLmt 7827;
BA_ "SPN" SG_ 2566802430 TransmissionShiftSelectorType 21199;
BA_ "SPN" SG_ 2566802430 TransmissionSpeedLimit 23774;
BA_ "SPN" SG_ 2566802686 BlackOutBrakeStopLampSelect 1841;
BA_ "SPN" SG_ 2566802686 BlackOutWorkLampSelect 1842;
BA_ "SPN" SG_ 2566802686 ConvoyDrivingLampSelect 1837;
BA_ "SPN" SG_ 2566802686 ConvoyLampSelect 1838;
BA_ "SPN" SG_ 2566802686 FrontBlackOutMarkerLampSelect 1839;
BA_ "SPN" SG_ 2566802686 NightVisionIlluminatorSelect 1843;
BA_ "SPN" SG_ 2566802686 OprtrsBlkOtIntnstSltn 1844;
BA_ "SPN" SG_ 2566802686 RearBlackOutMarkerSelect 1840;
BA_ "SPN" SG_ 2566803198 PositionOfDoors 1821;
BA_ "SPN" SG_ 2566803198 RampWheelChairLiftPosition 1820;
BA_ "SPN" SG_ 2566803198 Status2OfDoors 3411;
BA_ "SPN" SG_ 2566803454 RopBrakeControlActive 1818;
BA_ "SPN" SG_ 2566803454 RopEngineControlActive 1816;
BA_ "SPN" SG_ 2566803454 TrailerVdcActive 5624;
BA_ "SPN" SG_ 2566803454 VdcBrakeLightRequest 1815;
BA_ "SPN" SG_ 2566803454 VdcFullyOperational 1814;
BA_ "SPN" SG_ 2566803454 VdcInformationSignal 1813;
BA_ "SPN" SG_ 2566803454 YcBrakeControlActive 1819;
BA_ "SPN" SG_ 2566803454 YcEngineControlActive 1817;
BA_ "SPN" SG_ 2566803710 SliBattery1Temperature 1800;
BA_ "SPN" SG_ 2566803710 SliBattery2Temperature 1801;
BA_ "SPN" SG_ 2566803710 SliBattery3Temperature 2779;
BA_ "SPN" SG_ 2566803710 SliBattery4Temperature 2780;
BA_ "SPN" SG_ 2566803966 AccUsageDemand 5023;
BA_ "SPN" SG_ 2566803966 RequestedAccDistanceMode 1799;
BA_ "SPN" SG_ 2566804222 AltrntrCrrntHghRngRsltn 1795;
BA_ "SPN" SG_ 2566804222 SliBattery2NetCurrent 7498;
BA_ "SPN" SG_ 2566804222 SlBttr1NtCrrntHghRngRsltn 2579;
BA_ "SPN" SG_ 2566804222 EcuKeySwitchState 22624;
BA_ "SPN" SG_ 2566804478 LwLmtThrshldFrMxmmRpmFrmRtrdr 1776;
BA_ "SPN" SG_ 2566804478 LwLmtThrshldFrMxmmTrqFrmRtrdr 1778;
BA_ "SPN" SG_ 2566804478 MaximumContinuousRetarderSpeed 1780;
BA_ "SPN" SG_ 2566804478 MaximumContinuousRetarderTorque 1782;
BA_ "SPN" SG_ 2566804478 MinimumContinuousRetarderSpeed 1781;
BA_ "SPN" SG_ 2566804478 MinimumContinuousRetarderTorque 1783;
BA_ "SPN" SG_ 2566804478 HLtTsdFMCtsRpFRtd 1777;
BA_ "SPN" SG_ 2566804478 HLtTsdFMCtsTqFRtd 1779;
BA_ "SPN" SG_ 2566804734 EngineMaximumContinuousRpm 1772;
BA_ "SPN" SG_ 2566804734 EngineMaximumContinuousTorque 1774;
BA_ "SPN" SG_ 2566804734 EngineMinimumContinuousRpm 1773;
BA_ "SPN" SG_ 2566804734 EngineMinimumContinuousTorque 1775;
BA_ "SPN" SG_ 2566804734 ELwLtTsdFMxRpFE 1768;
BA_ "SPN" SG_ 2566804734 EHLtTsdFMCtsERp 1769;
BA_ "SPN" SG_ 2566804734 ELwLtTsdFMxTqFE 1770;
BA_ "SPN" SG_ 2566804734 EHLtTsdFMCtsTqFE 1771;
BA_ "SPN" SG_ 2566804990 FuelEnergyContent 4245;
BA_ "SPN" SG_ 2566804990 ReferenceEngineGasMassFlowRate 5684;
BA_ "SPN" SG_ 2566804990 SpecificHeatRatio 1767;
BA_ "SPN" SG_ 2566805246 Aftrtrtmnt1DslExhstFldTnkHtr 3363;
BA_ "SPN" SG_ 2566805246 Aftrtrtmnt1DslExhstFldTnkLvl 3517;
BA_ "SPN" SG_ 2566805246 Aftrtrtmnt1DslExhstFldTnkVlm 1761;
BA_ "SPN" SG_ 2566805246 Atttt1DsExstFdTTpt1 3031;
BA_ "SPN" SG_ 2566805246 AttttDsExstFdTLwLvIdt 5245;
BA_ "SPN" SG_ 2566805246 Atttt1DsExstFdTLvVPF 3532;
BA_ "SPN" SG_ 2566805246 Atttt1DsExstFdT1TptPF 4365;
BA_ "SPN" SG_ 2566805246 AftrtrtmntSrOprtrIndmntSvrt 5246;
BA_ "SPN" SG_ 2566805246 Atttt1DsExstFdT1HtPF 4366;
BA_ "SPN" SG_ 2566805758 BellowPressureFrontAxleLeft 1725;
BA_ "SPN" SG_ 2566805758 BellowPressureFrontAxleRight 1726;
BA_ "SPN" SG_ 2566805758 BellowPressureRearAxleLeft 1727;
BA_ "SPN" SG_ 2566805758 BellowPressureRearAxleRight 1728;
BA_ "SPN" SG_ 2566806014 RelativeLevelFrontAxleLeft 1721;
BA_ "SPN" SG_ 2566806014 RelativeLevelFrontAxleRight 1722;
BA_ "SPN" SG_ 2566806014 RelativeLevelRearAxleLeft 1724;
BA_ "SPN" SG_ 2566806014 RelativeLevelRearAxleRight 1723;
BA_ "SPN" SG_ 2566806526 DriverAlertnessLevel 7474;
BA_ "SPN" SG_ 2566806526 DrvrAlrtnssWrnngSstmStt 7475;
BA_ "SPN" SG_ 2566806526 ForwardLaneImagerStatus 8142;
BA_ "SPN" SG_ 2566806526 LaneDepartureWarningSystemState 8141;
BA_ "SPN" SG_ 2566806526 LaneTrackingStatusLeftSide 1710;
BA_ "SPN" SG_ 2566806526 LaneTrackingStatusRightSide 1711;
BA_ "SPN" SG_ 2566806526 LeftWheelLaneDepartureDistance 8139;
BA_ "SPN" SG_ 2566806526 LnDprtrIndtnEnlStts 1702;
BA_ "SPN" SG_ 2566806526 RightWheelLaneDepartureDistance 8140;
BA_ "SPN" SG_ 2566809342 BatteryMainSwitchHoldState 1681;
BA_ "SPN" SG_ 2566809598 AxlrHtrMxmmOtptPwr 1690;
BA_ "SPN" SG_ 2566809854 HdrlOlFltrRstrtnSwth 1713;
BA_ "SPN" SG_ 2566809854 HydraulicOilLevel 2602;
BA_ "SPN" SG_ 2566809854 HydraulicTemperature 1638;
BA_ "SPN" SG_ 2566809854 WinchOilPressureSwitch 1857;
BA_ "SPN" SG_ 2566810110 EngnChrgArClr1OtltTmprtr 2630;
BA_ "SPN" SG_ 2566810110 EngnClntTmprtrHghRsltn 1637;
BA_ "SPN" SG_ 2566810110 EngnIntkMnfld1TmprtrHghRsltn 1636;
BA_ "SPN" SG_ 2566810110 EngnIntkVlvAttnSstmOlTmprtr 2986;
BA_ "SPN" SG_ 2566810366 EngineCoolantPreHeatedState 3553;
BA_ "SPN" SG_ 2566810366 EngineOilFilterOutletPressure 3549;
BA_ "SPN" SG_ 2566810366 EngineOilLevelRemoteReservoir 1380;
BA_ "SPN" SG_ 2566810366 EngineOilPreHeatedState 3552;
BA_ "SPN" SG_ 2566810366 EngineOilPrimingPumpSwitch 3550;
BA_ "SPN" SG_ 2566810366 EngineOilPrimingState 3551;
BA_ "SPN" SG_ 2566810366 EngineVentilationStatus 3554;
BA_ "SPN" SG_ 2566810366 EngineWasteOilReservoirLevel 3548;
BA_ "SPN" SG_ 2566810366 EngnFlFltrStnSdDffrntlPrssr 1382;
BA_ "SPN" SG_ 2566810366 EngnFlSpplPmpIntkAsltPrssr 1381;
BA_ "SPN" SG_ 2566810366 EngnFlSpplPmpIntkPrssr 7104;
BA_ "SPN" SG_ 2566810366 FuelPumpPrimerStatus 4083;
BA_ "SPN" SG_ 2566810366 EngineFuelPrimingState 11732;
BA_ "SPN" SG_ 2566811134 AdrCompliantHeaterInstallation 6821;
BA_ "SPN" SG_ 2566811134 AuxiliaryHeaterMode 1677;
BA_ "SPN" SG_ 2566811134 AuxiliaryHeaterWaterPumpStatus 1676;
BA_ "SPN" SG_ 2566811134 AxlrHtrInptArTmprtr 1688;
BA_ "SPN" SG_ 2566811134 AxlrHtrOtptClntTmprtr 1687;
BA_ "SPN" SG_ 2566811134 AxlrHtrOtptPwrPrnt 1689;
BA_ "SPN" SG_ 2566811134 CabHeatingZone 1680;
BA_ "SPN" SG_ 2566811134 CabVentilation 1678;
BA_ "SPN" SG_ 2566811134 EngineHeatingZone 1679;
BA_ "SPN" SG_ 2566811902 GrossCombinationVehicleWeight 1760;
BA_ "SPN" SG_ 2566811902 PoweredVehicleWeight 1585;
BA_ "SPN" SG_ 2566811902 GrssCmntnVhlWghtCnfdn 21792;
BA_ "SPN" SG_ 2566819326 BatteryPotentialPowerInput2 444;
BA_ "SPN" SG_ 2566819326 EcuPowerOutputSupplyVoltage1 3597;
BA_ "SPN" SG_ 2566819326 EcuPowerOutputSupplyVoltage2 3598;
BA_ "SPN" SG_ 2566819326 EcuPowerOutputSupplyVoltage3 3599;
BA_ "SPN" SG_ 2566819838 EngnExtrnlShtdwnArSpplPrssr 1320;
BA_ "SPN" SG_ 2566820094 CalibrationRecordDurationTime 1253;
BA_ "SPN" SG_ 2566820094 CalibrationRecordStartDay 1251;
BA_ "SPN" SG_ 2566820094 CalibrationRecordStartMonth 1250;
BA_ "SPN" SG_ 2566820094 CalibrationRecordStartYear 1252;
BA_ "SPN" SG_ 2566820094 EnginePeakTorque1 1248;
BA_ "SPN" SG_ 2566820094 EnginePeakTorque2 1249;
BA_ "SPN" SG_ 2566820094 EnginePower 1247;
BA_ "SPN" SG_ 2566820094 EngineTorqueLimit1Transmission 1256;
BA_ "SPN" SG_ 2566820094 EngineTorqueLimit2Transmission 1258;
BA_ "SPN" SG_ 2566820094 EngineTorqueLimit3Transmission 1260;
BA_ "SPN" SG_ 2566820094 EngineTorqueLimit4Transmission 1261;
BA_ "SPN" SG_ 2566820094 EngineTorqueLimit5Switch 1262;
BA_ "SPN" SG_ 2566820094 EngineTorqueLimit6AxleInput 1263;
BA_ "SPN" SG_ 2566820094 EngineTorqueLimitFeature 1632;
BA_ "SPN" SG_ 2566820094 TorqueLimitingFeatureStatus 1254;
BA_ "SPN" SG_ 2566820094 TransmissionGearRatio1 1255;
BA_ "SPN" SG_ 2566820094 TransmissionGearRatio2 1257;
BA_ "SPN" SG_ 2566820094 TransmissionGearRatio3 1259;
BA_ "SPN" SG_ 2566820094 NmrOfEngnTrqHstrRrds 1246;
BA_ "SPN" SG_ 2566821118 EngineAuxiliaryCoolantPressure 1203;
BA_ "SPN" SG_ 2566821118 EngnAxlrClntTmprtr 1212;
BA_ "SPN" SG_ 2566821118 EngnClntPmpClntOtltPrssr 8473;
BA_ "SPN" SG_ 2566821118 EngnClntPrssr1ExtnddRng 20;
BA_ "SPN" SG_ 2566821118 EngnClntPrssr2ExtnddRng 7313;
BA_ "SPN" SG_ 2566821118 SeaWaterPumpOutletPressure 2435;
BA_ "SPN" SG_ 2566821118 SeaWaterPumpOutletPressure2 12893;
BA_ "SPN" SG_ 2566821118 EngnAftrlrClntOtltPrssr 15237;
BA_ "SPN" SG_ 2566821630 EngnTrhrgrWstgtAttr1DsrdPstn 5370;
BA_ "SPN" SG_ 2566821630 EngnTrhrgrWstgtAttr1Pstn 1188;
BA_ "SPN" SG_ 2566821630 EngnTrhrgrWstgtAttr1TmprtrStts 5372;
BA_ "SPN" SG_ 2566821630 EngnTrhrgrWstgtAttr2DsrdPstn 5373;
BA_ "SPN" SG_ 2566821630 EngnTrhrgrWstgtAttr2Pstn 1189;
BA_ "SPN" SG_ 2566821630 EngnTrhrgrWstgtAttr3Pstn 1190;
BA_ "SPN" SG_ 2566821630 EngnTrhrgrWstgtAttr4Pstn 1191;
BA_ "SPN" SG_ 2566821630 EngnTrhrgrWstgtAttrCntrlArPrssr 1192;
BA_ "SPN" SG_ 2566821630 EngnTrhrgrWstgtAttr1PrlmnrFm 5371;
BA_ "SPN" SG_ 2566821886 EngnTrhrgr1TrnOtltTmprtr 1184;
BA_ "SPN" SG_ 2566821886 EngnTrhrgr2TrnOtltTmprtr 1185;
BA_ "SPN" SG_ 2566821886 EngnTrhrgr3TrnOtltTmprtr 1186;
BA_ "SPN" SG_ 2566821886 EngnTrhrgr4TrnOtltTmprtr 1187;
BA_ "SPN" SG_ 2566822142 EngnTrhrgr1TrnIntkTmprtr 1180;
BA_ "SPN" SG_ 2566822142 EngnTrhrgr2TrnIntkTmprtr 1181;
BA_ "SPN" SG_ 2566822142 EngnTrhrgr3TrnIntkTmprtr 1182;
BA_ "SPN" SG_ 2566822142 EngnTrhrgr4TrnIntkTmprtr 1183;
BA_ "SPN" SG_ 2566822398 EngnTrhrgr1CmprssrIntkPrssr 1176;
BA_ "SPN" SG_ 2566822398 EngnTrhrgr2CmprssrIntkPrssr 1177;
BA_ "SPN" SG_ 2566822398 EngnTrhrgr3CmprssrIntkPrssr 1178;
BA_ "SPN" SG_ 2566822398 EngnTrhrgr4CmprssrIntkPrssr 1179;
BA_ "SPN" SG_ 2566822654 EngnTrhrgr1CmprssrIntkTmprtr 1172;
BA_ "SPN" SG_ 2566822654 EngnTrhrgr2CmprssrIntkTmprtr 1173;
BA_ "SPN" SG_ 2566822654 EngnTrhrgr3CmprssrIntkTmprtr 1174;
BA_ "SPN" SG_ 2566822654 EngnTrhrgr4CmprssrIntkTmprtr 1175;
BA_ "SPN" SG_ 2566823166 EngineMainBearing10Temperature 1166;
BA_ "SPN" SG_ 2566823166 EngineMainBearing11Temperature 1167;
BA_ "SPN" SG_ 2566823166 EngineMainBearing12Temperature 6830;
BA_ "SPN" SG_ 2566823166 EngineMainBearing9Temperature 1165;
BA_ "SPN" SG_ 2566823422 EngineMainBearing5Temperature 1161;
BA_ "SPN" SG_ 2566823422 EngineMainBearing6Temperature 1162;
BA_ "SPN" SG_ 2566823422 EngineMainBearing7Temperature 1163;
BA_ "SPN" SG_ 2566823422 EngineMainBearing8Temperature 1164;
BA_ "SPN" SG_ 2566823678 EngineMainBearing1Temperature 1157;
BA_ "SPN" SG_ 2566823678 EngineMainBearing2Temperature 1158;
BA_ "SPN" SG_ 2566823678 EngineMainBearing3Temperature 1159;
BA_ "SPN" SG_ 2566823678 EngineMainBearing4Temperature 1160;
BA_ "SPN" SG_ 2566824190 EngnExhstGsPrt13Tmprtr 1149;
BA_ "SPN" SG_ 2566824190 EngnExhstGsPrt14Tmprtr 1150;
BA_ "SPN" SG_ 2566824190 EngnExhstGsPrt15Tmprtr 1151;
BA_ "SPN" SG_ 2566824190 EngnExhstGsPrt16Tmprtr 1152;
BA_ "SPN" SG_ 2566825214 EngineEcuTemperature 1136;
BA_ "SPN" SG_ 2566825214 EngineOilTemperature2 1135;
BA_ "SPN" SG_ 2566825214 EngnExhstGsRrltn1DffrntlPrssr 411;
BA_ "SPN" SG_ 2566825214 EngnExhstGsRrltn1Tmprtr 412;
BA_ "SPN" SG_ 2566825726 EngnTrhrgr1BstPrssr 1127;
BA_ "SPN" SG_ 2566825726 EngnTrhrgr2BstPrssr 1128;
BA_ "SPN" SG_ 2566825726 EngnTrhrgr3BstPrssr 1129;
BA_ "SPN" SG_ 2566825726 EngnTrhrgr4BstPrssr 1130;
BA_ "SPN" SG_ 2566827518 BApptPssHRFtAxLtW 1091;
BA_ "SPN" SG_ 2566827518 BApptPssHRFtAxRtW 1092;
BA_ "SPN" SG_ 2566827518 BApptPssHRRAx1LtW 1093;
BA_ "SPN" SG_ 2566827518 BApptPssHRRAx1RtW 1094;
BA_ "SPN" SG_ 2566827518 BApptPssHRRAx2LtW 1095;
BA_ "SPN" SG_ 2566827518 BApptPssHRRAx2RtW 1096;
BA_ "SPN" SG_ 2566827518 BApptPssHRRAx3LtW 1097;
BA_ "SPN" SG_ 2566827518 BApptPssHRRAx3RtW 1098;
BA_ "SPN" SG_ 2566827774 AirCompressorStatus 1351;
BA_ "SPN" SG_ 2566827774 AxlrEqpmntSpplPrssr 1089;
BA_ "SPN" SG_ 2566827774 ParkingAndOrTrailerAirPressure 1086;
BA_ "SPN" SG_ 2566827774 PneumaticSupplyPressure 46;
BA_ "SPN" SG_ 2566827774 PwrtrnCrtArSpplPrssr 6305;
BA_ "SPN" SG_ 2566827774 ServiceBrakeCircuit1AirPressure 1087;
BA_ "SPN" SG_ 2566827774 ServiceBrakeCircuit2AirPressure 1088;
BA_ "SPN" SG_ 2566827774 AirSuspensionSupplyPressure1 1090;
BA_ "SPN" SG_ 2566831614 EngineFan1EstimatedPercentSpeed 975;
BA_ "SPN" SG_ 2566831614 FanDriveBypassCommandStatus 4212;
BA_ "SPN" SG_ 2566831614 FanDriveState 977;
BA_ "SPN" SG_ 2566831614 FanSpeed 1639;
BA_ "SPN" SG_ 2566831614 HydraulicFanMotorPressure 4211;
BA_ "SPN" SG_ 2566831614 EngineFanReverseSwitch 22131;
BA_ "SPN" SG_ 2566831614 EngineFanBypassSwitch 22132;
BA_ "SPN" SG_ 2566832126 FrontAxleSpeed 904;
BA_ "SPN" SG_ 2566832126 RelativeSpeedFrontAxleLeftWheel 905;
BA_ "SPN" SG_ 2566832126 RltvSpdFrntAxlRghtWhl 906;
BA_ "SPN" SG_ 2566832126 RelativeSpeedRearAxle1LeftWheel 907;
BA_ "SPN" SG_ 2566832126 RltvSpdRrAxl1RghtWhl 908;
BA_ "SPN" SG_ 2566832126 RelativeSpeedRearAxle2LeftWheel 909;
BA_ "SPN" SG_ 2566832126 RltvSpdRrAxl2RghtWhl 910;
BA_ "SPN" SG_ 2566832382 ServiceDelayCalendarTimeBased 915;
BA_ "SPN" SG_ 2566832382 ServiceDistance 914;
BA_ "SPN" SG_ 2566832382 SrvDlOprtnlTmBsd 916;
BA_ "SPN" SG_ 2566832382 ServiceComponentIdentificationA 911;
BA_ "SPN" SG_ 2566832382 ServiceComponentIdentificationB 912;
BA_ "SPN" SG_ 2566832382 ServiceComponentIdentificationC 913;
BA_ "SPN" SG_ 2566832638 TripDistanceHighResolution 918;
BA_ "SPN" SG_ 2566832638 TtlVhlDstnHghRsltn 917;
BA_ "SPN" SG_ 2566837758 Alternator1Status 3353;
BA_ "SPN" SG_ 2566837758 Alternator2Status 3354;
BA_ "SPN" SG_ 2566837758 Alternator3Status 3355;
BA_ "SPN" SG_ 2566837758 Alternator4Status 3356;
BA_ "SPN" SG_ 2566837758 AlternatorSpeed 589;
BA_ "SPN" SG_ 2566837758 AltrntrEltrlFlrStts 23898;
BA_ "SPN" SG_ 2566837758 AltrntrMhnlFlrStts 23899;
BA_ "SPN" SG_ 2566837758 AltrntrHghTmprtrWrnngStts 23900;
BA_ "SPN" SG_ 2566837758 AlternatorLinTimeoutDetected 23901;
BA_ "SPN" SG_ 2566837758 AltrntrLnCmmntnFlrStts 23902;
BA_ "SPN" SG_ 2566837758 AlternatorLoadBalancingStatus 23903;
BA_ "SPN" SG_ 2566837758 AlternatorExcitationStatus 23904;
BA_ "SPN" SG_ 2566838014 PrplsnMtrClntFllSwth 8476;
BA_ "SPN" SG_ 2566838014 PwrEltrnsClntFllSwth 8475;
BA_ "SPN" SG_ 2566838014 HvssThrmlMngmntMntnnSwth 20877;
BA_ "SPN" SG_ 2566838014 HrdOrEvSstmPrttnOvrrdSwth 7548;
BA_ "SPN" SG_ 2566838014 HrdOrEvSstmPrplsnClntLvlSwth 7549;
BA_ "SPN" SG_ 2566838014 HrdOrEvSstmPwrEltrnsClntLvlSwth 7550;
BA_ "SPN" SG_ 2566838014 HrdOrEvSstmOffBrdChrgrCnntnStts 7551;
BA_ "SPN" SG_ 2566838014 HrdOrEvSstmRgnrtvBrkngDslSwth 7552;
BA_ "SPN" SG_ 2566838014 HdOEvSstBPdRtvBDsSwt 7553;
BA_ "SPN" SG_ 2566838014 HrdOrEvSstmPrplsnDslSwth 7554;
BA_ "SPN" SG_ 2566838014 HybridOrEvSystemShutdownSwitch 7555;
BA_ "SPN" SG_ 2566838014 HdOEvSstCstRtvBLvSt 7556;
BA_ "SPN" SG_ 2566838014 Hsi1EmbeddedIntegritySupport 22270;
BA_ "SPN" SG_ 2566838014 Hsi1Counter 22271;
BA_ "SPN" SG_ 2566838014 Hsi1Crc 22272;
BA_ "SPN" SG_ 2566838014 HrdOrEvOprtrStppngMdRqst 23743;
BA_ "SPN" SG_ 2566838782 AuxiliaryIO01 701;
BA_ "SPN" SG_ 2566838782 AuxiliaryIO02 702;
BA_ "SPN" SG_ 2566838782 AuxiliaryIO03 703;
BA_ "SPN" SG_ 2566838782 AuxiliaryIO04 704;
BA_ "SPN" SG_ 2566838782 AuxiliaryIO05 705;
BA_ "SPN" SG_ 2566838782 AuxiliaryIO06 706;
BA_ "SPN" SG_ 2566838782 AuxiliaryIO07 707;
BA_ "SPN" SG_ 2566838782 AuxiliaryIO08 708;
BA_ "SPN" SG_ 2566838782 AuxiliaryIO09 709;
BA_ "SPN" SG_ 2566838782 AuxiliaryIO10 710;
BA_ "SPN" SG_ 2566838782 AuxiliaryIO11 711;
BA_ "SPN" SG_ 2566838782 AuxiliaryIO12 712;
BA_ "SPN" SG_ 2566838782 AuxiliaryIO13 713;
BA_ "SPN" SG_ 2566838782 AuxiliaryIO14 714;
BA_ "SPN" SG_ 2566838782 AuxiliaryIO15 715;
BA_ "SPN" SG_ 2566838782 AuxiliaryIO16 716;
BA_ "SPN" SG_ 2566838782 AuxiliaryIOChannel1 1083;
BA_ "SPN" SG_ 2566838782 AuxiliaryIOChannel2 1084;
BA_ "SPN" SG_ 2566839038 NmrOfSftwrIdntftnFlds 965;
BA_ "SPN" SG_ 2566839294 EngnFl1InjtrMtrngRl1Prssr 157;
BA_ "SPN" SG_ 2566839294 EngnFl1InjtrMtrngRl2Prssr 1349;
BA_ "SPN" SG_ 2566839294 EngnFl1InjtrTmngRl1Prssr 156;
BA_ "SPN" SG_ 2566839294 EngnFlInjtnCntrlPrssr 164;
BA_ "SPN" SG_ 2566839550 EngineTotalIdleFuelUsed 236;
BA_ "SPN" SG_ 2566839550 EngineTotalIdleHours 235;
BA_ "SPN" SG_ 2566839806 EngineTurbocharger1Speed 103;
BA_ "SPN" SG_ 2566839806 EngnTrhrgrDffrntlSpd 5980;
BA_ "SPN" SG_ 2566839806 EngnTrhrgrLOlPrssr1 104;
BA_ "SPN" SG_ 2566839806 EngnTrhrgrOlLvlSwth 1665;
BA_ "SPN" SG_ 2566840062 EngineAirStartPressure 82;
BA_ "SPN" SG_ 2566840062 EngineAirStopPressure 6832;
BA_ "SPN" SG_ 2566840062 EngnArStrtPrssrExtnddRng 6831;
BA_ "SPN" SG_ 2566840318 Aftertreatment1ExhaustDewPoint 3238;
BA_ "SPN" SG_ 2566840318 Aftertreatment2ExhaustDewPoint 3240;
BA_ "SPN" SG_ 2566840318 Aftrtrtmnt1ExhstGsMssFlwRt 3236;
BA_ "SPN" SG_ 2566840318 EngineSDesiredOperatingSpeed 515;
BA_ "SPN" SG_ 2566840318 ESDsdOptSpdAstAdstt 519;
BA_ "SPN" SG_ 2566840318 EstmtdEngnPrstLsssPrntTrq 2978;
BA_ "SPN" SG_ 2566840318 NominalFrictionPercentTorque 514;
BA_ "SPN" SG_ 2566840318 EngineExhaust1DewPoint 3237;
BA_ "SPN" SG_ 2566840318 EngineExhaust2DewPoint 3239;
BA_ "SPN" SG_ 2566840574 TotalVehicleDistance 245;
BA_ "SPN" SG_ 2566840574 TripDistance 244;
BA_ "SPN" SG_ 2566840830 MaximumRetarderSpeedPoint2 548;
BA_ "SPN" SG_ 2566840830 RetarderControlMethod 557;
BA_ "SPN" SG_ 2566840830 RetarderLocation 902;
BA_ "SPN" SG_ 2566840830 RetarderPercentTorqueAtPoint3 553;
BA_ "SPN" SG_ 2566840830 RetarderPercentTorqueAtPoint4 554;
BA_ "SPN" SG_ 2566840830 RetarderReferenceTorque 556;
BA_ "SPN" SG_ 2566840830 RetarderSpeedAtIdlePoint1 546;
BA_ "SPN" SG_ 2566840830 RetarderSpeedAtPeakTorquePoint5 547;
BA_ "SPN" SG_ 2566840830 RetarderSpeedAtPoint3 549;
BA_ "SPN" SG_ 2566840830 RetarderSpeedAtPoint4 550;
BA_ "SPN" SG_ 2566840830 RetarderType 901;
BA_ "SPN" SG_ 2566840830 RtrdrPrntTrqAtIdlPnt1 551;
BA_ "SPN" SG_ 2566840830 RtrdrPrntTrqAtMxmmSpdPnt2 552;
BA_ "SPN" SG_ 2566840830 RtrdrPrntTrqAtPkTrqPnt5 555;
BA_ "SPN" SG_ 2566841086 NumberOfForwardGearRatios 957;
BA_ "SPN" SG_ 2566841086 NumberOfReverseGearRatios 958;
BA_ "SPN" SG_ 2566841086 TransmissionGearRatio 581;
BA_ "SPN" SG_ 2566841342 EngineDefaultIdleTorqueLimit 7828;
BA_ "SPN" SG_ 2566841342 EngineDefaultTorqueLimit 1846;
BA_ "SPN" SG_ 2566841342 EngineMomentOfInertia 1794;
BA_ "SPN" SG_ 2566841342 EnginePercentTorqueAtIdlePoint1 539;
BA_ "SPN" SG_ 2566841342 EnginePercentTorqueAtPoint2 540;
BA_ "SPN" SG_ 2566841342 EnginePercentTorqueAtPoint3 541;
BA_ "SPN" SG_ 2566841342 EnginePercentTorqueAtPoint4 542;
BA_ "SPN" SG_ 2566841342 EnginePercentTorqueAtPoint5 543;
BA_ "SPN" SG_ 2566841342 EngineReferenceTorque 544;
BA_ "SPN" SG_ 2566841342 EngineSpeedAtHighIdlePoint6 532;
BA_ "SPN" SG_ 2566841342 EngineSpeedAtIdlePoint1 188;
BA_ "SPN" SG_ 2566841342 EngineSpeedAtPoint2 528;
BA_ "SPN" SG_ 2566841342 EngineSpeedAtPoint3 529;
BA_ "SPN" SG_ 2566841342 EngineSpeedAtPoint4 530;
BA_ "SPN" SG_ 2566841342 EngineSpeedAtPoint5 531;
BA_ "SPN" SG_ 2566841342 EngnGnKpOfThEndspdGvrnr 545;
BA_ "SPN" SG_ 2566841342 EngnMxmmMmntrOvrrdSpdPnt7 533;
BA_ "SPN" SG_ 2566841342 EngnMxmmMmntrOvrrdTmLmt 534;
BA_ "SPN" SG_ 2566841342 EngnRqstdSpdCntrlRngLwrLmt 535;
BA_ "SPN" SG_ 2566841342 EngnRqstdSpdCntrlRngUpprLmt 536;
BA_ "SPN" SG_ 2566841342 EngnRqstdTrqCntrlRngLwrLmt 537;
BA_ "SPN" SG_ 2566841342 EngnRqstdTrqCntrlRngUpprLmt 538;
BA_ "SPN" SG_ 2566841342 ERqstdSpdCtRUppLtExtddR 1712;
BA_ "SPN" SG_ 2566841342 SupportTsc1ControlPurposeGroup1 3345;
BA_ "SPN" SG_ 2566841342 SupportTsc1ControlPurposeGroup2 3346;
BA_ "SPN" SG_ 2566841342 SupportTsc1ControlPurposeGroup3 3347;
BA_ "SPN" SG_ 2566841342 SupportTsc1ControlPurposeGroup4 3348;
BA_ "SPN" SG_ 2566841342 SupportVariableRateTsc1Message 3344;
BA_ "SPN" SG_ 2566841342 EngineDefaultSpeedLimit 23775;
BA_ "SPN" SG_ 2566841598 ACHighPressureFanSwitch 985;
BA_ "SPN" SG_ 2566841598 ClntLvlEngnPrttnShtdwnStts 5566;
BA_ "SPN" SG_ 2566841598 EngineAirShutoffCommandStatus 2813;
BA_ "SPN" SG_ 2566841598 EngineAirShutoffStatus 3667;
BA_ "SPN" SG_ 2566841598 EngineAlarmAcknowledge 2815;
BA_ "SPN" SG_ 2566841598 EngineAlarmOutputCommandStatus 2814;
BA_ "SPN" SG_ 2566841598 EngineIdleShutdownTimerFunction 591;
BA_ "SPN" SG_ 2566841598 EngineIdleShutdownTimerOverride 592;
BA_ "SPN" SG_ 2566841598 EngineIdleShutdownTimerState 590;
BA_ "SPN" SG_ 2566841598 EngineOilPressureSwitch 8159;
BA_ "SPN" SG_ 2566841598 EngineOverspeedTest 2812;
BA_ "SPN" SG_ 2566841598 EngineWaitToStartLamp 1081;
BA_ "SPN" SG_ 2566841598 EngnIdlShtdwnDrvrAlrtMd 594;
BA_ "SPN" SG_ 2566841598 EngnIdlShtdwnHsShtdwnEngn 593;
BA_ "SPN" SG_ 2566841598 EngnPrttnSstmApprhngShtdwn 1109;
BA_ "SPN" SG_ 2566841598 EngnPrttnSstmCnfgrtn 1111;
BA_ "SPN" SG_ 2566841598 EngnPrttnSstmHsShtdwnEngn 1110;
BA_ "SPN" SG_ 2566841598 EngnPrttnSstmTmrOvrrd 1108;
BA_ "SPN" SG_ 2566841598 EngnPrttnSstmTmrStt 1107;
BA_ "SPN" SG_ 2566841598 PtoShutdownHasShutdownEngine 5404;
BA_ "SPN" SG_ 2566841598 RefrigerantHighPressureSwitch 605;
BA_ "SPN" SG_ 2566841598 RefrigerantLowPressureSwitch 875;
BA_ "SPN" SG_ 2566841598 MhnIntvtShtdwnHsShtdwnEngn 22133;
BA_ "SPN" SG_ 2566841854 EngineTotalHoursOfOperation 247;
BA_ "SPN" SG_ 2566841854 EngineTotalRevolutions 249;
BA_ "SPN" SG_ 2566842110 Day 962;
BA_ "SPN" SG_ 2566842110 Hours 961;
BA_ "SPN" SG_ 2566842110 LocalHourOffset 1602;
BA_ "SPN" SG_ 2566842110 LocalMinuteOffset 1601;
BA_ "SPN" SG_ 2566842110 Minutes 960;
BA_ "SPN" SG_ 2566842110 Month 963;
BA_ "SPN" SG_ 2566842110 Seconds 959;
BA_ "SPN" SG_ 2566842110 Year 964;
BA_ "SPN" SG_ 2566842366 TotalPowerTakeoffHours 248;
BA_ "SPN" SG_ 2566842366 TotalVehicleHours 246;
BA_ "SPN" SG_ 2566842622 Altitude 580;
BA_ "SPN" SG_ 2566842622 CompassBearing 165;
BA_ "SPN" SG_ 2566842622 NavigationBasedVehicleSpeed 517;
BA_ "SPN" SG_ 2566842622 Pitch 583;
BA_ "SPN" SG_ 2566842878 EngineTotalFuelUsed 250;
BA_ "SPN" SG_ 2566842878 EngineTripFuel 182;
BA_ "SPN" SG_ 2566843134 AxleLocation 928;
BA_ "SPN" SG_ 2566843134 AxleWeight 582;
BA_ "SPN" SG_ 2566843134 CargoWeight 181;
BA_ "SPN" SG_ 2566843134 TrailerWeight 180;
BA_ "SPN" SG_ 2566843902 CruiseControlHighSetLimitSpeed 87;
BA_ "SPN" SG_ 2566843902 MaximumVehicleSpeedLimit 74;
BA_ "SPN" SG_ 2566843902 MxmmVhlSpdLmtHghRsltn 6808;
BA_ "SPN" SG_ 2566843902 CrsCntrlOprtrLwStLmtSpd 88;
BA_ "SPN" SG_ 2566843902 CrsCntrlSstmLwStLmtSpd 10289;
BA_ "SPN" SG_ 2566843902 CrsCntrlDslCmmndSpprt 10290;
BA_ "SPN" SG_ 2566843902 CrsCntrlRsmCmmndSpprt 10291;
BA_ "SPN" SG_ 2566843902 CrsCntrlPsCmmndSpprt 10292;
BA_ "SPN" SG_ 2566843902 CruiseControlSetCommandSupport 10293;
BA_ "SPN" SG_ 2566843902 PwrtrnAdptvCrsCntrlTp 10294;
BA_ "SPN" SG_ 2566844158 EngineCoolantTemperature 110;
BA_ "SPN" SG_ 2566844158 EngineFuel1Temperature1 174;
BA_ "SPN" SG_ 2566844158 EngineIntercoolerTemperature 52;
BA_ "SPN" SG_ 2566844158 EngineOilTemperature1 175;
BA_ "SPN" SG_ 2566844158 EngnChrgArClrThrmsttOpnng 1134;
BA_ "SPN" SG_ 2566844158 EngnTrhrgr1OlTmprtr 176;
BA_ "SPN" SG_ 2566844414 EngineCoolantLevel1 111;
BA_ "SPN" SG_ 2566844414 EngineCoolantPressure1 109;
BA_ "SPN" SG_ 2566844414 EngineCrankcasePressure1 101;
BA_ "SPN" SG_ 2566844414 EngineFuelDeliveryPressure 94;
BA_ "SPN" SG_ 2566844414 EngineOilLevel 98;
BA_ "SPN" SG_ 2566844414 EngineOilPressure1 100;
BA_ "SPN" SG_ 2566844414 EngnExtnddCrnksBlwBPrssr 22;
